VERSION "dbc-export 1 2025.20.8"

NS_ :

BS_:

BU_: ADSP APB APP APS APSB BB BMS CC CMP CMPD CP DAS DI DIF DIR DPB EPAS3P EPAS3S EPASTP EPASTS EPBL EPBR ESP EVSE FC GTW HCML HCMR HVP IBST ICR IDB LS OCS1P PARK PCS PM PMF PMR PNCD PTC RADC RCM RCM2 RCM3 RCU SCCM SCM SCS SDCR TAS TCU TPMS TRCM UI UIS UMC USM VC VCFRONT VCLEFT VCRIGHT VCSEC VEH

BO_ 852 TAS_alertMatrix: 8 TAS
 SG_ TAS_matrixIndex M : 0|4@1+ (1,0) [0|15] "" Vector__XXX
 SG_ TAS_a001_WatchdogReset m0 : 4|1@1+ (1,0) [0|1] "" Vector__XXX
 SG_ TAS_a002_PowerLossReset m0 : 5|1@1+ (1,0) [0|1] "" Vector__XXX
 SG_ TAS_a003_SWAssertion m0 : 6|1@1+ (1,0) [0|1] "" Vector__XXX
 SG_ TAS_a012_CPUReset m0 : 15|1@1+ (1,0) [0|1] "" Vector__XXX
 SG_ TAS_a015_NVMMError m0 : 18|1@1+ (1,0) [0|1] "" Vector__XXX
 SG_ TAS_a016_NVMMRecordError m0 : 19|1@1+ (1,0) [0|1] "" Vector__XXX
 SG_ TAS_a021_TaskSchedulerError m0 : 24|1@1+ (1,0) [0|1] "" Vector__XXX
 SG_ TAS_a022_TaskInitError m0 : 25|1@1+ (1,0) [0|1] "" Vector__XXX
 SG_ TAS_a023_rtosResetRequested m0 : 26|1@1+ (1,0) [0|1] "" Vector__XXX
 SG_ TAS_a024_prefetchAbort m0 : 27|1@1+ (1,0) [0|1] "" Vector__XXX
 SG_ TAS_a025_CrashEvent m0 : 28|1@1+ (1,0) [0|1] "" Vector__XXX
 SG_ TAS_a030_PWMerrorFL m0 : 33|1@1+ (1,0) [0|1] "" Vector__XXX
 SG_ TAS_a031_PWMerrorFR m0 : 34|1@1+ (1,0) [0|1] "" Vector__XXX
 SG_ TAS_a032_PWMerrorRL m0 : 35|1@1+ (1,0) [0|1] "" Vector__XXX
 SG_ TAS_a033_PWMerrorRR m0 : 36|1@1+ (1,0) [0|1] "" Vector__XXX
 SG_ TAS_a034_PWMshortFL m0 : 37|1@1+ (1,0) [0|1] "" Vector__XXX
 SG_ TAS_a035_PWMshortFR m0 : 38|1@1+ (1,0) [0|1] "" Vector__XXX
 SG_ TAS_a036_PWMshortRL m0 : 39|1@1+ (1,0) [0|1] "" Vector__XXX
 SG_ TAS_a037_PWMshortRR m0 : 40|1@1+ (1,0) [0|1] "" Vector__XXX
 SG_ TAS_a038_PWMopenFL m0 : 41|1@1+ (1,0) [0|1] "" Vector__XXX
 SG_ TAS_a039_PWMopenFR m0 : 42|1@1+ (1,0) [0|1] "" Vector__XXX
 SG_ TAS_a040_PWMopenRL m0 : 43|1@1+ (1,0) [0|1] "" Vector__XXX
 SG_ TAS_a041_PWMopenRR m0 : 44|1@1+ (1,0) [0|1] "" Vector__XXX
 SG_ TAS_a043_Task1msError m0 : 46|1@1+ (1,0) [0|1] "" Vector__XXX
 SG_ TAS_a044_Task10msError m0 : 47|1@1+ (1,0) [0|1] "" Vector__XXX
 SG_ TAS_a045_Task100msError m0 : 48|1@1+ (1,0) [0|1] "" Vector__XXX
 SG_ TAS_a046_Task1000msError m0 : 49|1@1+ (1,0) [0|1] "" Vector__XXX
 SG_ TAS_a061_XCPConnected m1 : 4|1@1+ (1,0) [0|1] "" Vector__XXX
 SG_ TAS_a062_XCPWasConnected m1 : 5|1@1+ (1,0) [0|1] "" Vector__XXX
 SG_ TAS_a063_abortFault m1 : 6|1@1+ (1,0) [0|1] "" Vector__XXX
 SG_ TAS_a064_abortFaultExt m1 : 7|1@1+ (1,0) [0|1] "" Vector__XXX
 SG_ TAS_a065_ahbWriteFault m1 : 8|1@1+ (1,0) [0|1] "" Vector__XXX
 SG_ TAS_a066_undefinedInstructionAbo m1 : 9|1@1+ (1,0) [0|1] "" Vector__XXX
 SG_ TAS_a067_reservedHandlerAbort m1 : 10|1@1+ (1,0) [0|1] "" Vector__XXX
 SG_ TAS_a070_underVoltage12V m1 : 13|1@1+ (1,0) [0|1] "" Vector__XXX
 SG_ TAS_a071_overVoltage12V m1 : 14|1@1+ (1,0) [0|1] "" Vector__XXX
 SG_ TAS_a072_shortCircuit5VOnBoard m1 : 15|1@1+ (1,0) [0|1] "" Vector__XXX
 SG_ TAS_a073_underVoltage5VOnBoard m1 : 16|1@1+ (1,0) [0|1] "" Vector__XXX
 SG_ TAS_a074_shortCircuit5VOffBoard m1 : 17|1@1+ (1,0) [0|1] "" Vector__XXX
 SG_ TAS_a075_underVoltage5VOffBoard m1 : 18|1@1+ (1,0) [0|1] "" Vector__XXX
 SG_ TAS_a076_overVoltage5VOffBoard m1 : 19|1@1+ (1,0) [0|1] "" Vector__XXX
 SG_ TAS_a077_pressureSigVTooLow m1 : 20|1@1+ (1,0) [0|1] "" Vector__XXX
 SG_ TAS_a078_pressureSigVTooHigh m1 : 21|1@1+ (1,0) [0|1] "" Vector__XXX
 SG_ TAS_a080_shortCircuit5VHeight m1 : 23|1@1+ (1,0) [0|1] "" Vector__XXX
 SG_ TAS_a081_underVoltage5VHeight m1 : 24|1@1+ (1,0) [0|1] "" Vector__XXX
 SG_ TAS_a082_overVoltage5VHeight m1 : 25|1@1+ (1,0) [0|1] "" Vector__XXX
 SG_ TAS_a083_shortCircuit5VAnalog m1 : 26|1@1+ (1,0) [0|1] "" Vector__XXX
 SG_ TAS_a084_underVoltage5VAnalog m1 : 27|1@1+ (1,0) [0|1] "" Vector__XXX
 SG_ TAS_a085_overVoltage5VAnalog m1 : 28|1@1+ (1,0) [0|1] "" Vector__XXX
 SG_ TAS_a086_underVoltage12VSwtchd m1 : 29|1@1+ (1,0) [0|1] "" Vector__XXX
 SG_ TAS_a087_overVoltage12VSwtchd m1 : 30|1@1+ (1,0) [0|1] "" Vector__XXX
 SG_ TAS_a093_OTPError m1 : 36|1@1+ (1,0) [0|1] "" Vector__XXX
 SG_ TAS_a098_VCFRONT_MIA m1 : 41|1@1+ (1,0) [0|1] "" Vector__XXX
 SG_ TAS_a099_UI_MIA m1 : 42|1@1+ (1,0) [0|1] "" Vector__XXX
 SG_ TAS_a100_RCM_MIA m1 : 43|1@1+ (1,0) [0|1] "" Vector__XXX
 SG_ TAS_a101_ESP_MIA m1 : 44|1@1+ (1,0) [0|1] "" Vector__XXX
 SG_ TAS_a102_DI_MIA m1 : 45|1@1+ (1,0) [0|1] "" Vector__XXX
 SG_ TAS_a103_GTW_MIA m1 : 46|1@1+ (1,0) [0|1] "" Vector__XXX
 SG_ TAS_a105_ECUDebugMode m1 : 48|1@1+ (1,0) [0|1] "" Vector__XXX
 SG_ TAS_a106_HighCPULoad m1 : 49|1@1+ (1,0) [0|1] "" Vector__XXX
 SG_ TAS_a107_HighStackUsage m1 : 50|1@1+ (1,0) [0|1] "" Vector__XXX
 SG_ TAS_a150_accelAvgImplausible_FL_ m2 : 33|1@1+ (1,0) [0|1] "" Vector__XXX
 SG_ TAS_a151_accelAvgImplausible_FL_ m2 : 34|1@1+ (1,0) [0|1] "" Vector__XXX
 SG_ TAS_a152_accelAvgImplausible_FL_ m2 : 35|1@1+ (1,0) [0|1] "" Vector__XXX
 SG_ TAS_a153_accelAvgImplausible_FR_ m2 : 36|1@1+ (1,0) [0|1] "" Vector__XXX
 SG_ TAS_a154_accelAvgImplausible_FR_ m2 : 37|1@1+ (1,0) [0|1] "" Vector__XXX
 SG_ TAS_a155_accelAvgImplausible_FR_ m2 : 38|1@1+ (1,0) [0|1] "" Vector__XXX
 SG_ TAS_a156_accelAvgImplausible_RL_ m2 : 39|1@1+ (1,0) [0|1] "" Vector__XXX
 SG_ TAS_a157_accelAvgImplausible_RL_ m2 : 40|1@1+ (1,0) [0|1] "" Vector__XXX
 SG_ TAS_a158_accelAvgImplausible_RL_ m2 : 41|1@1+ (1,0) [0|1] "" Vector__XXX
 SG_ TAS_a159_accelAvgImplausible_RR_ m2 : 42|1@1+ (1,0) [0|1] "" Vector__XXX
 SG_ TAS_a160_accelAvgImplausible_RR_ m2 : 43|1@1+ (1,0) [0|1] "" Vector__XXX
 SG_ TAS_a161_accelAvgImplausible_RR_ m2 : 44|1@1+ (1,0) [0|1] "" Vector__XXX
 SG_ TAS_a164_damperSolenoidMismatch m2 : 47|1@1+ (1,0) [0|1] "" Vector__XXX
 SG_ TAS_a165_damperValveCompFL m2 : 48|1@1+ (1,0) [0|1] "" Vector__XXX
 SG_ TAS_a166_damperValveRbndFL m2 : 49|1@1+ (1,0) [0|1] "" Vector__XXX
 SG_ TAS_a167_damperValveCompFR m2 : 50|1@1+ (1,0) [0|1] "" Vector__XXX
 SG_ TAS_a168_damperValveRbndFR m2 : 51|1@1+ (1,0) [0|1] "" Vector__XXX
 SG_ TAS_a169_damperValveCompRL m2 : 52|1@1+ (1,0) [0|1] "" Vector__XXX
 SG_ TAS_a170_damperValveRbndRL m2 : 53|1@1+ (1,0) [0|1] "" Vector__XXX
 SG_ TAS_a171_damperValveCompRR m2 : 54|1@1+ (1,0) [0|1] "" Vector__XXX
 SG_ TAS_a172_damperValveRbndRR m2 : 55|1@1+ (1,0) [0|1] "" Vector__XXX
 SG_ TAS_a173_staticLeakDetectFL m2 : 56|1@1+ (1,0) [0|1] "" Vector__XXX
 SG_ TAS_a174_staticLeakDetectFR m2 : 57|1@1+ (1,0) [0|1] "" Vector__XXX
 SG_ TAS_a175_staticLeakDetectRL m2 : 58|1@1+ (1,0) [0|1] "" Vector__XXX
 SG_ TAS_a176_staticLeakDetectRR m2 : 59|1@1+ (1,0) [0|1] "" Vector__XXX
 SG_ TAS_a190_a2bFrontAxleFault m3 : 13|1@1+ (1,0) [0|1] "" Vector__XXX
 SG_ TAS_a191_a2bRearAxleFault m3 : 14|1@1+ (1,0) [0|1] "" Vector__XXX
 SG_ TAS_a192_rideHeightObserverDiver m3 : 15|1@1+ (1,0) [0|1] "" Vector__XXX
 SG_ TAS_a193_EPAS3P_MIA m3 : 16|1@1+ (1,0) [0|1] "" Vector__XXX
 SG_ TAS_a194_a2bFrontAxleDataError m3 : 17|1@1+ (1,0) [0|1] "" Vector__XXX
 SG_ TAS_a195_a2bRearAxleDataError m3 : 18|1@1+ (1,0) [0|1] "" Vector__XXX
 SG_ TAS_a196_adaptiveDampingUsingDSP m3 : 19|1@1+ (1,0) [0|1] "" Vector__XXX
 SG_ TAS_a197_invalidAdaptiveModeRequ m3 : 20|1@1+ (1,0) [0|1] "" Vector__XXX
 SG_ TAS_a200_jackModeActive m3 : 23|1@1+ (1,0) [0|1] "" Vector__XXX
 SG_ TAS_a201_low12VBattery m3 : 24|1@1+ (1,0) [0|1] "" Vector__XXX
 SG_ TAS_a210_outOfRangeCalibration m3 : 33|1@1+ (1,0) [0|1] "" Vector__XXX
 SG_ TAS_a211_noRideHeightCalib m3 : 34|1@1+ (1,0) [0|1] "" Vector__XXX
 SG_ TAS_a213_yellowWarningLamp m3 : 36|1@1+ (1,0) [0|1] "" Vector__XXX
 SG_ TAS_a214_redWarningLamp m3 : 37|1@1+ (1,0) [0|1] "" Vector__XXX
 SG_ TAS_a215_limpHomeMode10 m3 : 38|1@1+ (1,0) [0|1] "" Vector__XXX
 SG_ TAS_a216_limpHomeMode20 m3 : 39|1@1+ (1,0) [0|1] "" Vector__XXX
 SG_ TAS_a217_limpHomeMode30 m3 : 40|1@1+ (1,0) [0|1] "" Vector__XXX
 SG_ TAS_a218_limpHomeMode40 m3 : 41|1@1+ (1,0) [0|1] "" Vector__XXX
 SG_ TAS_a220_exhaustGalleryFault m3 : 43|1@1+ (1,0) [0|1] "" Vector__XXX
 SG_ TAS_a221_valveLeakDetected m3 : 44|1@1+ (1,0) [0|1] "" Vector__XXX
 SG_ TAS_a222_compressorPrefillFault m3 : 45|1@1+ (1,0) [0|1] "" Vector__XXX
 SG_ TAS_a223_blockedAirline m3 : 46|1@1+ (1,0) [0|1] "" Vector__XXX
 SG_ TAS_a224_openAirline m3 : 47|1@1+ (1,0) [0|1] "" Vector__XXX
 SG_ TAS_a225_galleryPressureTooHigh m3 : 48|1@1+ (1,0) [0|1] "" Vector__XXX
 SG_ TAS_a226_PWMfastDetectFL m3 : 49|1@1+ (1,0) [0|1] "" Vector__XXX
 SG_ TAS_a227_PWMfastDetectFR m3 : 50|1@1+ (1,0) [0|1] "" Vector__XXX
 SG_ TAS_a228_PWMfastDetectRL m3 : 51|1@1+ (1,0) [0|1] "" Vector__XXX
 SG_ TAS_a229_PWMfastDetectRR m3 : 52|1@1+ (1,0) [0|1] "" Vector__XXX
 SG_ TAS_a230_notifyGeofence m3 : 53|1@1+ (1,0) [0|1] "" Vector__XXX
 SG_ TAS_a231_notifyRoughRoadRaise m3 : 54|1@1+ (1,0) [0|1] "" Vector__XXX
 SG_ TAS_a232_suspensionTypeMismatch m3 : 55|1@1+ (1,0) [0|1] "" Vector__XXX
 SG_ TAS_a233_compressorStuckOn m3 : 56|1@1+ (1,0) [0|1] "" Vector__XXX
 SG_ TAS_a234_damperHydraulicMismatch m3 : 57|1@1+ (1,0) [0|1] "" Vector__XXX
 SG_ TAS_a240_airSpringLeak m3 : 63|1@1+ (1,0) [0|1] "" Vector__XXX
 SG_ TAS_a284_serviceRunModeActive m4 : 47|1@1+ (1,0) [0|1] "" Vector__XXX
 SG_ TAS_a285_twistSustainedUserVis m4 : 48|1@1+ (1,0) [0|1] "" Vector__XXX
 SG_ TAS_a286_driveCycleStats1 m4 : 49|1@1+ (1,0) [0|1] "" Vector__XXX
 SG_ TAS_a287_driveCycleStats2 m4 : 50|1@1+ (1,0) [0|1] "" Vector__XXX
 SG_ TAS_a288_driveCycleStats3 m4 : 51|1@1+ (1,0) [0|1] "" Vector__XXX
 SG_ TAS_a289_driveCycleStats4 m4 : 52|1@1+ (1,0) [0|1] "" Vector__XXX
 SG_ TAS_a290_twistSustainedAtSpeed m4 : 53|1@1+ (1,0) [0|1] "" Vector__XXX
 SG_ TAS_a291_frontAxleTooHigh m4 : 54|1@1+ (1,0) [0|1] "" Vector__XXX
 SG_ TAS_a292_rearAxleTooHigh m4 : 55|1@1+ (1,0) [0|1] "" Vector__XXX
 SG_ TAS_a293_frontAxleTooLow m4 : 56|1@1+ (1,0) [0|1] "" Vector__XXX
 SG_ TAS_a294_rearAxleTooLow m4 : 57|1@1+ (1,0) [0|1] "" Vector__XXX
 SG_ TAS_a295_targetHeightNotMet m4 : 58|1@1+ (1,0) [0|1] "" Vector__XXX
 SG_ TAS_a296_chassisTypeMismatch m4 : 59|1@1+ (1,0) [0|1] "" Vector__XXX
 SG_ TAS_a297_vinMismatch m4 : 60|1@1+ (1,0) [0|1] "" Vector__XXX
 SG_ TAS_a298_vinNotLearned m4 : 61|1@1+ (1,0) [0|1] "" Vector__XXX
 SG_ TAS_a299_offsetEstimateTooLarge m4 : 62|1@1+ (1,0) [0|1] "" Vector__XXX
 SG_ TAS_a300_offsetEstimateData1 m4 : 63|1@1+ (1,0) [0|1] "" Vector__XXX
 SG_ TAS_a301_offsetEstimateData2 m5 : 4|1@1+ (1,0) [0|1] "" Vector__XXX
 SG_ TAS_a303_massEstimateFrozen m5 : 6|1@1+ (1,0) [0|1] "" Vector__XXX
 SG_ TAS_a304_massEstimateFrozenData m5 : 7|1@1+ (1,0) [0|1] "" Vector__XXX
 SG_ TAS_a305_newEndstopPosition m5 : 8|1@1+ (1,0) [0|1] "" Vector__XXX
 SG_ TAS_a306_hardwareProtectFrozen m5 : 9|1@1+ (1,0) [0|1] "" Vector__XXX
 SG_ TAS_a307_endstopBoundaryComp m5 : 10|1@1+ (1,0) [0|1] "" Vector__XXX
 SG_ TAS_a308_endstopBoundaryRbnd m5 : 11|1@1+ (1,0) [0|1] "" Vector__XXX
 SG_ TAS_a309_controlFrozen m5 : 12|1@1+ (1,0) [0|1] "" Vector__XXX
 SG_ TAS_a310_controlFrozenData m5 : 13|1@1+ (1,0) [0|1] "" Vector__XXX
 SG_ TAS_a311_accelsMIA m5 : 14|1@1+ (1,0) [0|1] "" Vector__XXX
 SG_ TAS_a312_rotationalRatesMIA m5 : 15|1@1+ (1,0) [0|1] "" Vector__XXX
 SG_ TAS_a313_dampingCntrlDisabled m5 : 16|1@1+ (1,0) [0|1] "" Vector__XXX
 SG_ TAS_a314_dampingReduced m5 : 17|1@1+ (1,0) [0|1] "" Vector__XXX
 SG_ TAS_a315_pcbaHighTemp m5 : 18|1@1+ (1,0) [0|1] "" Vector__XXX
 SG_ TAS_a316_offsetsAccels m5 : 19|1@1+ (1,0) [0|1] "" Vector__XXX
 SG_ TAS_a317_offsetsRotationalRates m5 : 20|1@1+ (1,0) [0|1] "" Vector__XXX
 SG_ TAS_a318_dampingCntrlInputMIA m5 : 21|1@1+ (1,0) [0|1] "" Vector__XXX
 SG_ TAS_a319_drivetrainTypeMismatch m5 : 22|1@1+ (1,0) [0|1] "" Vector__XXX
 SG_ TAS_a320_offsetsRotationalRates m5 : 23|1@1+ (1,0) [0|1] "" Vector__XXX
 SG_ TAS_a321_speedBumpAttributes1 m5 : 24|1@1+ (1,0) [0|1] "" Vector__XXX
 SG_ TAS_a322_speedBumpAttributes2 m5 : 25|1@1+ (1,0) [0|1] "" Vector__XXX
 SG_ TAS_a332_levelingThresholds1 m5 : 35|1@1+ (1,0) [0|1] "" Vector__XXX
 SG_ TAS_a333_levelingThresholds2 m5 : 36|1@1+ (1,0) [0|1] "" Vector__XXX

BO_ 523 TAS_axleData: 8 TAS
 SG_ TAS_axleIndex M : 0|1@1+ (1,0) [0|1] "" Vector__XXX
 SG_ TAS_rawHeightFL m0 : 4|10@1+ (1,-512) [-512|510] "mm" Vector__XXX
 SG_ TAS_staticHeightEstimateFL m0 : 14|10@1+ (1,-512) [-512|510] "mm" Vector__XXX
 SG_ TAS_componentPressureFL m0 : 24|8@1+ (0.1,0) [0|25.4] "bara" Vector__XXX
 SG_ TAS_rawHeightFR m0 : 32|10@1+ (1,-512) [-512|510] "mm" Vector__XXX
 SG_ TAS_staticHeightEstimateFR m0 : 42|10@1+ (1,-512) [-512|510] "mm" Vector__XXX
 SG_ TAS_componentPressureFR m0 : 52|8@1+ (0.1,0) [0|25.4] "bara" Vector__XXX
 SG_ TAS_rawHeightRL m1 : 4|10@1+ (1,-512) [-512|510] "mm" Vector__XXX
 SG_ TAS_staticHeightEstimateRL m1 : 14|10@1+ (1,-512) [-512|510] "mm" Vector__XXX
 SG_ TAS_componentPressureRL m1 : 24|8@1+ (0.1,0) [0|25.4] "bara" Vector__XXX
 SG_ TAS_rawHeightRR m1 : 32|10@1+ (1,-512) [-512|510] "mm" Vector__XXX
 SG_ TAS_staticHeightEstimateRR m1 : 42|10@1+ (1,-512) [-512|510] "mm" Vector__XXX
 SG_ TAS_componentPressureRR m1 : 52|8@1+ (0.1,0) [0|25.4] "bara" Vector__XXX

BO_ 1398 TAS_dampingStates: 8 TAS
 SG_ TAS_endstopState : 0|1@1+ (1,0) [0|1] "" Vector__XXX
 SG_ TAS_continuousControlState : 1|1@1+ (1,0) [0|1] "" Vector__XXX
 SG_ TAS_activeTireTune : 2|1@1+ (1,0) [0|1] "" Vector__XXX
 SG_ TAS_roughnessRaiseReason : 3|2@1+ (1,0) [0|3] "" Vector__XXX
 SG_ TAS_frontMetricDrivesRear : 5|2@1+ (1,0) [0|3] "" Vector__XXX
 SG_ TAS_roadCondition : 8|8@1+ (0.005,0) [0|1.27] "-" Vector__XXX
 SG_ TAS_bellyProtect : 16|2@1+ (1,0) [0|3] "" Vector__XXX
 SG_ TAS_frontMetricDrivesFront : 18|2@1+ (1,0) [0|3] "" Vector__XXX
 SG_ TAS_speedBumpAxleFront : 20|3@1+ (1,0) [0|7] "" Vector__XXX
 SG_ TAS_speedBumpAxleRear : 23|3@1+ (1,0) [0|7] "" Vector__XXX
 SG_ TAS_holeProtectFL : 26|2@1+ (1,0) [0|3] "" Vector__XXX
 SG_ TAS_holeProtectFR : 28|2@1+ (1,0) [0|3] "" Vector__XXX
 SG_ TAS_holeProtectRL : 30|2@1+ (1,0) [0|3] "" Vector__XXX
 SG_ TAS_holeProtectRR : 32|2@1+ (1,0) [0|3] "" Vector__XXX
 SG_ TAS_stepProtectFL : 34|2@1+ (1,0) [0|3] "" Vector__XXX
 SG_ TAS_stepProtectFR : 36|2@1+ (1,0) [0|3] "" Vector__XXX
 SG_ TAS_stepProtectRL : 38|2@1+ (1,0) [0|3] "" Vector__XXX
 SG_ TAS_stepProtectRR : 40|2@1+ (1,0) [0|3] "" Vector__XXX
 SG_ TAS_FDUTorqueCorruptionScale : 42|4@1+ (0.075,0) [0|1.05] "-" Vector__XXX
 SG_ TAS_sprungMassEstimate : 46|5@1+ (64,1800) [1800|3720] "kg" Vector__XXX
 SG_ TAS_anyDamperActive : 51|1@1+ (1,0) [0|1] "" Vector__XXX
 SG_ TAS_dampingStatesCounter : 52|4@1+ (1,0) [0|15] "" Vector__XXX
 SG_ TAS_dampingStatesChecksum : 56|8@1+ (1,0) [0|255] "" Vector__XXX

BO_ 1357 TAS_info: 8 TAS
 SG_ TAS_infoIndex M : 0|8@1+ (1,0) [0|255] "" Vector__XXX
 SG_ TAS_infoBuildType m10 : 8|8@1+ (1,0) [0|255] "" Vector__XXX
 SG_ TAS_infoBuildConfigId m10 : 16|16@1+ (1,0) [0|65535] "" Vector__XXX
 SG_ TAS_infoHardwareId m10 : 32|1@1+ (1,0) [0|1] "" Vector__XXX
 SG_ TAS_infoComponentId m10 : 48|16@1+ (1,0) [0|65535] "" Vector__XXX
 SG_ TAS_infoPcbaId m11 : 16|8@1+ (1,0) [0|255] "" Vector__XXX
 SG_ TAS_infoAssemblyId m11 : 24|8@1+ (1,0) [0|254] "" Vector__XXX
 SG_ TAS_infoUsageId m11 : 32|16@1+ (1,0) [0|65535] "" Vector__XXX
 SG_ TAS_infoSubUsageId m11 : 48|16@1+ (1,0) [0|65535] "" Vector__XXX
 SG_ TAS_infoAppCrc m13 : 32|32@1+ (1,0) [0|4294967295] "" Vector__XXX
 SG_ TAS_infoAppGitHash m17 : 8|56@1+ (1,0) [0|7.20575940379e+16] "" Vector__XXX
 SG_ TAS_infoBootGitHash m18 : 8|56@1+ (1,0) [0|7.20575940379e+16] "" Vector__XXX
 SG_ TAS_infoPlatformType m19 : 8|8@1+ (1,0) [0|255] "" Vector__XXX
 SG_ TAS_infoMajorVersion m19 : 16|8@1+ (1,0) [0|254] "" Vector__XXX
 SG_ TAS_infoBranchOrigin m19 : 24|8@1+ (1,0) [0|254] "" Vector__XXX
 SG_ TAS_infoMaturity m19 : 32|8@1+ (1,0) [0|254] "" Vector__XXX
 SG_ TAS_infoHardwareRevision m19 : 40|8@1+ (1,0) [0|254] "" Vector__XXX

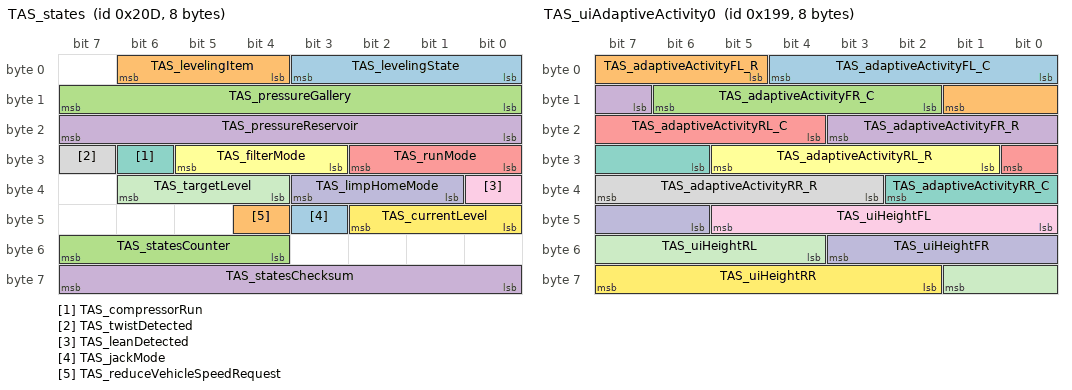
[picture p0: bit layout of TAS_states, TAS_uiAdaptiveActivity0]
BO_ 525 TAS_states: 8 TAS
 SG_ TAS_levelingState : 0|4@1+ (1,0) [0|15] "" Vector__XXX
 SG_ TAS_levelingItem : 4|3@1+ (1,0) [0|7] "" Vector__XXX
 SG_ TAS_pressureGallery : 8|8@1+ (0.1,0) [0|25.4] "bara" Vector__XXX
 SG_ TAS_pressureReservoir : 16|8@1+ (0.1,0) [0|25.4] "bara" Vector__XXX
 SG_ TAS_runMode : 24|3@1+ (1,0) [0|7] "" Vector__XXX
 SG_ TAS_filterMode : 27|3@1+ (1,0) [0|7] "" Vector__XXX
 SG_ TAS_compressorRun : 30|1@1+ (1,0) [0|1] "" Vector__XXX
 SG_ TAS_twistDetected : 31|1@1+ (1,0) [0|1] "" Vector__XXX
 SG_ TAS_leanDetected : 32|1@1+ (1,0) [0|1] "" Vector__XXX
 SG_ TAS_limpHomeMode : 33|3@1+ (1,0) [0|7] "" Vector__XXX
 SG_ TAS_targetLevel : 36|3@1+ (1,0) [0|7] "" Vector__XXX
 SG_ TAS_currentLevel : 40|3@1+ (1,0) [0|7] "" Vector__XXX
 SG_ TAS_jackMode : 43|1@1+ (1,0) [0|1] "" Vector__XXX
 SG_ TAS_reduceVehicleSpeedRequest : 44|1@1+ (1,0) [0|1] "" Vector__XXX
 SG_ TAS_statesCounter : 52|4@1+ (1,0) [0|15] "" Vector__XXX
 SG_ TAS_statesChecksum : 56|8@1+ (1,0) [0|255] "" Vector__XXX

BO_ 409 TAS_uiAdaptiveActivity0: 8 TAS
 SG_ TAS_adaptiveActivityFL_C : 0|5@1+ (0.04,0) [0|1] "-" Vector__XXX
 SG_ TAS_adaptiveActivityFL_R : 5|5@1+ (0.04,0) [0|1] "-" Vector__XXX
 SG_ TAS_adaptiveActivityFR_C : 10|5@1+ (0.04,0) [0|1] "-" Vector__XXX
 SG_ TAS_adaptiveActivityFR_R : 15|5@1+ (0.04,0) [0|1] "-" Vector__XXX
 SG_ TAS_adaptiveActivityRL_C : 20|5@1+ (0.04,0) [0|1] "-" Vector__XXX
 SG_ TAS_adaptiveActivityRL_R : 25|5@1+ (0.04,0) [0|1] "-" Vector__XXX
 SG_ TAS_adaptiveActivityRR_C : 30|5@1+ (0.04,0) [0|1] "-" Vector__XXX
 SG_ TAS_adaptiveActivityRR_R : 35|5@1+ (0.04,0) [0|1] "-" Vector__XXX
 SG_ TAS_uiHeightFL : 40|6@1+ (4,-128) [-128|120] "mm" Vector__XXX
 SG_ TAS_uiHeightFR : 46|6@1+ (4,-128) [-128|120] "mm" Vector__XXX
 SG_ TAS_uiHeightRL : 52|6@1+ (4,-128) [-128|120] "mm" Vector__XXX
 SG_ TAS_uiHeightRR : 58|6@1+ (4,-128) [-128|120] "mm" Vector__XXX

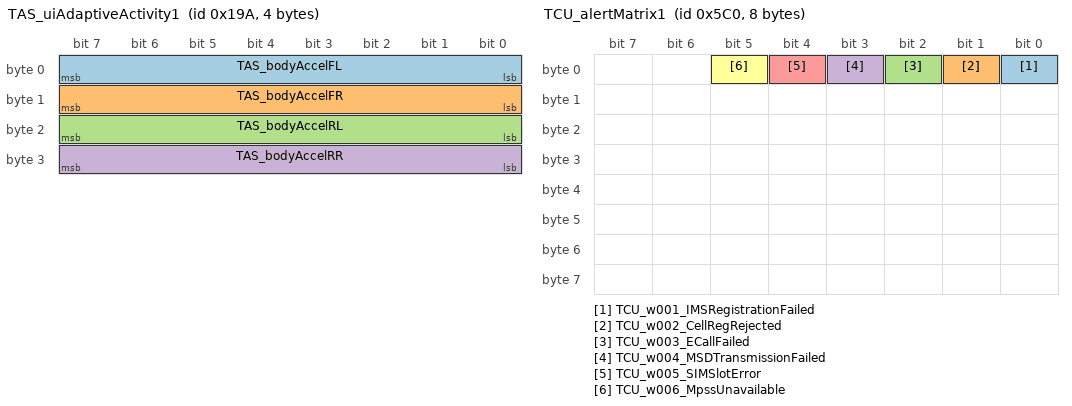
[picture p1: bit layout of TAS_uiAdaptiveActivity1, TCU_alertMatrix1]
BO_ 410 TAS_uiAdaptiveActivity1: 4 TAS
 SG_ TAS_bodyAccelFL : 0|8@1+ (0.05,-5) [-5|5] "g" Vector__XXX
 SG_ TAS_bodyAccelFR : 8|8@1+ (0.05,-5) [-5|5] "g" Vector__XXX
 SG_ TAS_bodyAccelRL : 16|8@1+ (0.05,-5) [-5|5] "g" Vector__XXX
 SG_ TAS_bodyAccelRR : 24|8@1+ (0.05,-5) [-5|5] "g" Vector__XXX

BO_ 538 TAS_uiControl: 5 TAS
 SG_ TAS_yellowWarningLamp : 0|1@1+ (1,0) [0|1] "" Vector__XXX
 SG_ TAS_redWarningLamp : 1|1@1+ (1,0) [0|1] "" Vector__XXX
 SG_ TAS_veryLowAllowed : 2|1@1+ (1,0) [0|1] "" Vector__XXX
 SG_ TAS_lowAllowed : 3|1@1+ (1,0) [0|1] "" Vector__XXX
 SG_ TAS_standardAllowed : 4|1@1+ (1,0) [0|1] "" Vector__XXX
 SG_ TAS_highAllowed : 5|1@1+ (1,0) [0|1] "" Vector__XXX
 SG_ TAS_veryHighAllowed : 6|1@1+ (1,0) [0|1] "" Vector__XXX
 SG_ TAS_extractAllowed : 7|1@1+ (1,0) [0|1] "" Vector__XXX
 SG_ TAS_showSpinner : 9|1@1+ (1,0) [0|1] "" Vector__XXX
 SG_ TAS_adaptiveRideModeOverride : 10|2@1+ (1,0) [0|2] "" Vector__XXX
 SG_ TAS_levelSelectEnabled : 12|1@1+ (1,0) [0|1] "" Vector__XXX
 SG_ TAS_jackModeToggleEnabled : 13|1@1+ (1,0) [0|1] "" Vector__XXX
 SG_ TAS_adaptiveRideSelectEnabled : 14|1@1+ (1,0) [0|1] "" Vector__XXX
 SG_ TAS_launchModeState : 16|3@1+ (1,0) [0|7] "" Vector__XXX
 SG_ TAS_restrictUpLevelingFalcons : 19|1@1+ (1,0) [0|1] "" Vector__XXX
 SG_ TAS_restrictUpLevelingTrunk : 20|1@1+ (1,0) [0|1] "" Vector__XXX
 SG_ TAS_restrictDownLevelingDoors : 21|1@1+ (1,0) [0|1] "" Vector__XXX
 SG_ TAS_restrictLevelingChargeCable : 22|1@1+ (1,0) [0|1] "" Vector__XXX
 SG_ TAS_restrictLevelingSystemCheck : 23|1@1+ (1,0) [0|1] "" Vector__XXX
 SG_ TAS_restrictLevelingTransport : 24|1@1+ (1,0) [0|1] "" Vector__XXX
 SG_ TAS_restrictLevelingShowroom : 25|1@1+ (1,0) [0|1] "" Vector__XXX
 SG_ TAS_uiControlCounter : 28|4@1+ (1,0) [0|15] "" Vector__XXX
 SG_ TAS_uiControlChecksum : 32|8@1+ (1,0) [0|255] "" Vector__XXX

BO_ 1410 TCU_alertLog: 8 TCU
 SG_ TCU_alertID M : 0|3@1+ (1,0) [0|7] "" Vector__XXX
 SG_ TCU_alertState : 15|1@1+ (1,0) [0|1] "" Vector__XXX
 SG_ TCU_w001_FailCode m1 : 16|32@1+ (1,0) [0|4294967295] "" Vector__XXX
 SG_ TCU_w002_RejCause m2 : 16|32@1+ (1,0) [0|4294967295] "" Vector__XXX
 SG_ TCU_w003_CallFailCode m3 : 16|32@1+ (1,0) [0|4294967295] "" Vector__XXX
 SG_ TCU_w004_MSDFailCode m4 : 16|32@1+ (1,0) [0|4294967295] "" Vector__XXX
 SG_ TCU_w006_Count m6 : 16|32@1+ (1,0) [0|4294967295] "" Vector__XXX

BO_ 1472 TCU_alertMatrix1: 8 TCU
 SG_ TCU_w001_IMSRegistrationFailed : 0|1@1+ (1,0) [0|1] "" Vector__XXX
 SG_ TCU_w002_CellRegRejected : 1|1@1+ (1,0) [0|1] "" Vector__XXX
 SG_ TCU_w003_ECallFailed : 2|1@1+ (1,0) [0|1] "" Vector__XXX
 SG_ TCU_w004_MSDTransmissionFailed : 3|1@1+ (1,0) [0|1] "" Vector__XXX
 SG_ TCU_w005_SIMSlotError : 4|1@1+ (1,0) [0|1] "" Vector__XXX
 SG_ TCU_w006_MpssUnavailable : 5|1@1+ (1,0) [0|1] "" Vector__XXX

BO_ 1409 TCU_log: 8 TCU
 SG_ TCU_logMux M : 0|32@1+ (1,0) [0|4294967295] "" Vector__XXX
 SG_ TCU_cpuTemp m0 : 32|32@1+ (1,0) [0|4294967295] "C" Vector__XXX
 SG_ TCU_cpuUsage m1 : 32|32@1+ (1,0) [0|4294967295] "%" Vector__XXX
 SG_ TCU_mdmCoreTemperature m2 : 32|32@1+ (1,0) [0|4294967295] "C" Vector__XXX
 SG_ TCU_availableMemory m3 : 32|32@1+ (1,0) [0|4294967295] "KB" Vector__XXX
 SG_ TCU_pwm m4 : 32|32@1+ (1,0) [0|4294967295] "" Vector__XXX
 SG_ TCU_pwmcap m5 : 32|32@1+ (1,0) [0|4294967295] "" Vector__XXX
 SG_ TCU_totalResumes m6 : 32|32@1+ (1,0) [0|4294967295] "" Vector__XXX
 SG_ TCU_mdmUplinkQueueSize m7 : 32|32@1+ (1,0) [0|4294967295] "bytes" Vector__XXX
 SG_ TCU_mdmRSRP m8 : 32|32@1- (1,0) [-2147483648|2147483647] "dBm" Vector__XXX
 SG_ TCU_mdmSINR m9 : 32|32@1- (1,0) [-2147483648|2147483647] "dBm" Vector__XXX
 SG_ TCU_mdmUplinkAllowedRate m10 : 32|32@1+ (1,0) [0|4294967295] "Kbps" Vector__XXX
 SG_ TCU_mdmUplinkAvgRage m11 : 32|32@1+ (1,0) [0|4294967295] "" Vector__XXX
 SG_ TCU_mdmServiceState m12 : 32|32@1+ (1,0) [0|4294967295] "" Vector__XXX
 SG_ TCU_mdmIMSStatus m13 : 32|32@1+ (1,0) [0|4294967295] "" Vector__XXX
 SG_ TCU_mdmSIMStatus m14 : 32|32@1+ (1,0) [0|4294967295] "" Vector__XXX
 SG_ TCU_mdmBusyActive m15 : 32|32@1+ (1,0) [0|4294967294] "" Vector__XXX

BO_ 1408 TCU_status: 8 TCU
 SG_ TCU_statusMux M : 0|32@1+ (1,0) [0|4294967295] "" Vector__XXX
 SG_ TCU_wakeUpReason m0 : 32|32@1+ (1,0) [0|4294967294] "" Vector__XXX
 SG_ TCU_tcuCmdId m1 : 32|1@1+ (1,0) [0|1] "" Vector__XXX
 SG_ TCU_goingToSleep m2 : 32|32@1+ (1,0) [0|4294967294] "" Vector__XXX

BO_ 879 TPMS_StatusC: 8 TPMS
 SG_ TPMS_c_globalHardWarning : 0|1@1+ (1,0) [0|1] "" Vector__XXX
 SG_ TPMS_c_globalSoftWarning : 1|1@1+ (1,0) [0|1] "" Vector__XXX
 SG_ TPMS_systemMalfunction : 2|1@1+ (1,0) [0|1] "" Vector__XXX
 SG_ TPMS_WA_version : 3|1@1+ (1,0) [0|1] "" Vector__XXX
 SG_ TPMS_globalDeltaPressure : 4|1@1+ (1,0) [0|1] "" Vector__XXX
 SG_ TPMS_newSensorLearnt : 5|3@1+ (1,0) [0|7] "" Vector__XXX
 SG_ TPMS_softWarningRR : 8|1@1+ (1,0) [0|1] "" Vector__XXX
 SG_ TPMS_hardWarningRR : 9|1@1+ (1,0) [0|1] "" Vector__XXX
 SG_ TPMS_softWarningRL : 10|1@1+ (1,0) [0|1] "" Vector__XXX
 SG_ TPMS_hardWarningRL : 11|1@1+ (1,0) [0|1] "" Vector__XXX
 SG_ TPMS_softWarningFR : 12|1@1+ (1,0) [0|1] "" Vector__XXX
 SG_ TPMS_hardWarningFR : 13|1@1+ (1,0) [0|1] "" Vector__XXX
 SG_ TPMS_softWarningFL : 14|1@1+ (1,0) [0|1] "" Vector__XXX
 SG_ TPMS_hardWarningFL : 15|1@1+ (1,0) [0|1] "" Vector__XXX
 SG_ TPMS_learningStatus : 16|2@1+ (1,0) [0|3] "" Vector__XXX
 SG_ TPMS_localisationStatus : 18|2@1+ (1,0) [0|3] "" Vector__XXX
 SG_ TPMS_deltaPressWarningFL : 20|1@1+ (1,0) [0|1] "" Vector__XXX
 SG_ TPMS_deltaPressWarningFR : 21|1@1+ (1,0) [0|1] "" Vector__XXX
 SG_ TPMS_deltaPressWarningRL : 22|1@1+ (1,0) [0|1] "" Vector__XXX
 SG_ TPMS_deltaPressWarningRR : 23|1@1+ (1,0) [0|1] "" Vector__XXX
 SG_ TPMS_sensorNoResponseFL : 24|1@1+ (1,0) [0|1] "" Vector__XXX
 SG_ TPMS_sensorNoResponseFR : 25|1@1+ (1,0) [0|1] "" Vector__XXX
 SG_ TPMS_sensorNoResponseRL : 26|1@1+ (1,0) [0|1] "" Vector__XXX
 SG_ TPMS_sensorNoResponseRR : 27|1@1+ (1,0) [0|1] "" Vector__XXX
 SG_ TPMS_sensorThermShutdownFL : 28|1@1+ (1,0) [0|1] "" Vector__XXX
 SG_ TPMS_sensorThermShutdownFR : 29|1@1+ (1,0) [0|1] "" Vector__XXX
 SG_ TPMS_sensorThermShutdownRL : 30|1@1+ (1,0) [0|1] "" Vector__XXX
 SG_ TPMS_sensorThermShutdownRR : 31|1@1+ (1,0) [0|1] "" Vector__XXX
 SG_ TPMS_sensorBatteryLowFL : 32|1@1+ (1,0) [0|1] "" Vector__XXX
 SG_ TPMS_sensorBatteryLowFR : 33|1@1+ (1,0) [0|1] "" Vector__XXX
 SG_ TPMS_sensorBatteryLowRL : 34|1@1+ (1,0) [0|1] "" Vector__XXX
 SG_ TPMS_sensorBatteryLowRR : 35|1@1+ (1,0) [0|1] "" Vector__XXX
 SG_ TPMS_sensorDefectiveFL : 36|1@1+ (1,0) [0|1] "" Vector__XXX
 SG_ TPMS_sensorDefectiveFR : 37|1@1+ (1,0) [0|1] "" Vector__XXX
 SG_ TPMS_sensorDefectiveRL : 38|1@1+ (1,0) [0|1] "" Vector__XXX
 SG_ TPMS_sensorDefectiveRR : 39|1@1+ (1,0) [0|1] "" Vector__XXX
 SG_ TPMS_ecuUnderVoltage : 40|1@1+ (1,0) [0|1] "" Vector__XXX
 SG_ TPMS_ecuOverVoltage : 41|1@1+ (1,0) [0|1] "" Vector__XXX
 SG_ TPMS_ecuRamRomNvMFail : 42|1@1+ (1,0) [0|1] "" Vector__XXX
 SG_ TPMS_rfReceiverFail : 43|1@1+ (1,0) [0|1] "" Vector__XXX
 SG_ TPMS_wheelPulseMissing : 44|1@1+ (1,0) [0|1] "" Vector__XXX
 SG_ TPMS_vehicleSpeedFail : 45|1@1+ (1,0) [0|1] "" Vector__XXX
 SG_ TPMS_externalTemperatureFail : 46|1@1+ (1,0) [0|1] "" Vector__XXX
 SG_ TPMS_eolNotCompleted : 47|1@1+ (1,0) [0|1] "" Vector__XXX
 SG_ TPMS_rcpFront : 48|8@1+ (0.025,0) [0|6.375] "bar" Vector__XXX
 SG_ TPMS_rcpRear : 56|8@1+ (0.025,0) [0|6.375] "bar" Vector__XXX

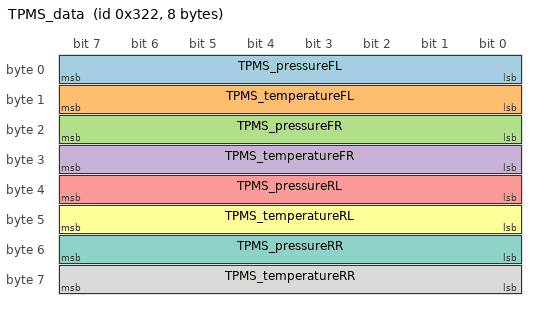
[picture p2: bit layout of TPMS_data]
BO_ 802 TPMS_data: 8 TPMS
 SG_ TPMS_pressureFL : 0|8@1+ (0.025,0) [0|6.35] "bar" Vector__XXX
 SG_ TPMS_temperatureFL : 8|8@1+ (1,-40) [-40|214] "degC" Vector__XXX
 SG_ TPMS_pressureFR : 16|8@1+ (0.025,0) [0|6.35] "bar" Vector__XXX
 SG_ TPMS_temperatureFR : 24|8@1+ (1,-40) [-40|214] "degC" Vector__XXX
 SG_ TPMS_pressureRL : 32|8@1+ (0.025,0) [0|6.35] "bar" Vector__XXX
 SG_ TPMS_temperatureRL : 40|8@1+ (1,-40) [-40|214] "degC" Vector__XXX
 SG_ TPMS_pressureRR : 48|8@1+ (0.025,0) [0|6.35] "bar" Vector__XXX
 SG_ TPMS_temperatureRR : 56|8@1+ (1,-40) [-40|214] "degC" Vector__XXX

BO_ 1519 TPMS_info: 8 TPMS
 SG_ TPMS_infoIndex M : 0|8@1+ (1,0) [0|255] "" Vector__XXX
 SG_ TPMS_infoComponentID m10 : 48|16@1+ (1,0) [0|65535] "" Vector__XXX
 SG_ TPMS_infoPcbaID m11 : 16|8@1+ (1,0) [0|255] "" Vector__XXX
 SG_ TPMS_infoAssemblyID m11 : 24|8@1+ (1,0) [0|255] "" Vector__XXX
 SG_ TPMS_infoUsageID m11 : 32|16@1+ (1,0) [0|65535] "" Vector__XXX
 SG_ TPMS_infoApplicationCRC m13 : 32|32@1+ (1,0) [0|4294967295] "" Vector__XXX
 SG_ TPMS_infoBootUdsProtoVersion m20 : 8|8@1+ (1,0) [0|255] "" Vector__XXX
 SG_ TPMS_infoBootloaderCRC m20 : 32|32@1+ (1,0) [0|4294967295] "" Vector__XXX

BO_ 1298 TRCM_alertLog: 8 TRCM
 SG_ TRCM_alertID M : 0|10@1+ (1,0) [0|1023] "" Vector__XXX
 SG_ TRCM_alertState : 15|1@1+ (1,0) [0|1] "" Vector__XXX
 SG_ TRCM_a015_NVMMMemOverflow m15 : 16|1@1+ (1,0) [0|1] "" Vector__XXX
 SG_ TRCM_a015_NVMMFilesystemError m15 : 17|1@1+ (1,0) [0|1] "" Vector__XXX
 SG_ TRCM_a015_NVMMRecordIDError m15 : 18|1@1+ (1,0) [0|1] "" Vector__XXX
 SG_ TRCM_a057_VEH_cpControl m57 : 16|1@1+ (1,0) [0|1] "" Vector__XXX
 SG_ TRCM_a059_voltageDrop m59 : 16|12@1+ (0.005443676,0) [0|22.29185322] "V" Vector__XXX
 SG_ TRCM_a059_resistanceEstimate m59 : 28|12@1+ (0.00244,0) [0|9.9918] "Ohms" Vector__XXX
 SG_ TRCM_a059_current m59 : 40|12@1+ (0.05,0) [0|204.75] "A" Vector__XXX
 SG_ TRCM_a063_switchChannel m63 : 16|8@1+ (1,0) [0|255] "" Vector__XXX
 SG_ TRCM_a063_switchType m63 : 24|8@1+ (1,0) [0|255] "" Vector__XXX
 SG_ TRCM_a063_ADCVoltage m63 : 32|8@1+ (0.025,0) [0|6.375] "V" Vector__XXX
 SG_ TRCM_a063_disconnected m63 : 40|1@1+ (1,0) [0|1] "" Vector__XXX
 SG_ TRCM_a063_indeterminate m63 : 41|1@1+ (1,0) [0|1] "" Vector__XXX
 SG_ TRCM_a063_stuckActive m63 : 42|1@1+ (1,0) [0|1] "" Vector__XXX
 SG_ TRCM_a063_faulted m63 : 43|1@1+ (1,0) [0|1] "" Vector__XXX
 SG_ TRCM_a082_RIPC_epbPrivateState m82 : 16|1@1+ (1,0) [0|1] "" Vector__XXX
 SG_ TRCM_a082_RIPC_remoteHSD m82 : 17|1@1+ (1,0) [0|1] "" Vector__XXX
 SG_ TRCM_a082_RIPC_railStatus m82 : 18|1@1+ (1,0) [0|1] "" Vector__XXX
 SG_ TRCM_a082_RIPC_remoteMux m82 : 19|1@1+ (1,0) [0|1] "" Vector__XXX
 SG_ TRCM_a083_LIPC_epbPrivateState m83 : 16|1@1+ (1,0) [0|1] "" Vector__XXX
 SG_ TRCM_a083_LIPC_remoteHSD m83 : 17|1@1+ (1,0) [0|1] "" Vector__XXX
 SG_ TRCM_a083_LIPC_railStatus m83 : 18|1@1+ (1,0) [0|1] "" Vector__XXX
 SG_ TRCM_a083_LIPC_HSDFaults m83 : 19|1@1+ (1,0) [0|1] "" Vector__XXX
 SG_ TRCM_a084_CH_StatusC m84 : 16|1@1+ (1,0) [0|1] "" Vector__XXX
 SG_ TRCM_a085_PARTY_buttonStatus m85 : 16|1@1+ (1,0) [0|1] "" Vector__XXX
 SG_ TRCM_a086_VEH_LVBMS_statusHigh m86 : 16|1@1+ (1,0) [0|1] "" Vector__XXX
 SG_ TRCM_a086_VEH_LVBMS_statusLow m86 : 17|1@1+ (1,0) [0|1] "" Vector__XXX
 SG_ TRCM_a086_VEH_status m86 : 18|1@1+ (1,0) [0|1] "" Vector__XXX
 SG_ TRCM_a086_VEH_12VBatteryStatus m86 : 19|1@1+ (1,0) [0|1] "" Vector__XXX
 SG_ TRCM_a086_VEH_LVPowerState m86 : 20|1@1+ (1,0) [0|1] "" Vector__XXX
 SG_ TRCM_a086_VEH_lightStatus m86 : 21|1@1+ (1,0) [0|1] "" Vector__XXX
 SG_ TRCM_a086_VEH_systemStatus m86 : 22|1@1+ (1,0) [0|1] "" Vector__XXX
 SG_ TRCM_a086_VEH_thermalStatus m86 : 23|1@1+ (1,0) [0|1] "" Vector__XXX
 SG_ TRCM_a086_VEH_vehNm m86 : 24|1@1+ (1,0) [0|1] "" Vector__XXX
 SG_ TRCM_a087_VEH_temperature m87 : 16|1@1+ (1,0) [0|1] "" Vector__XXX
 SG_ TRCM_a087_VEH_thermalControl m87 : 17|1@1+ (1,0) [0|1] "" Vector__XXX
 SG_ TRCM_a087_VEH_torque m87 : 18|1@1+ (1,0) [0|1] "" Vector__XXX
 SG_ TRCM_a087_VEH_status m87 : 19|1@1+ (1,0) [0|1] "" Vector__XXX
 SG_ TRCM_a087_PARTY_torque m87 : 20|1@1+ (1,0) [0|1] "" Vector__XXX
 SG_ TRCM_a087_PARTY_status m87 : 21|1@1+ (1,0) [0|1] "" Vector__XXX
 SG_ TRCM_a087_PARTY_temperature m87 : 22|1@1+ (1,0) [0|1] "" Vector__XXX
 SG_ TRCM_a087_PARTY_thermalControl m87 : 23|1@1+ (1,0) [0|1] "" Vector__XXX
 SG_ TRCM_a088_VEH_temperature m88 : 16|1@1+ (1,0) [0|1] "" Vector__XXX
 SG_ TRCM_a088_VEH_thermalControl m88 : 17|1@1+ (1,0) [0|1] "" Vector__XXX
 SG_ TRCM_a088_VEH_torque m88 : 18|1@1+ (1,0) [0|1] "" Vector__XXX
 SG_ TRCM_a088_VEH_status m88 : 19|1@1+ (1,0) [0|1] "" Vector__XXX
 SG_ TRCM_a088_PARTY_torque m88 : 20|1@1+ (1,0) [0|1] "" Vector__XXX
 SG_ TRCM_a088_PARTY_status m88 : 21|1@1+ (1,0) [0|1] "" Vector__XXX
 SG_ TRCM_a088_PARTY_temperature m88 : 22|1@1+ (1,0) [0|1] "" Vector__XXX
 SG_ TRCM_a088_PARTY_thermalControl m88 : 23|1@1+ (1,0) [0|1] "" Vector__XXX
 SG_ TRCM_a089_PARTY_party1 m89 : 16|1@1+ (1,0) [0|1] "" Vector__XXX
 SG_ TRCM_a089_PARTY_status m89 : 17|1@1+ (1,0) [0|1] "" Vector__XXX
 SG_ TRCM_a089_VEH_status m89 : 18|1@1+ (1,0) [0|1] "" Vector__XXX
 SG_ TRCM_a089_BDY_party1 m89 : 19|1@1+ (1,0) [0|1] "" Vector__XXX
 SG_ TRCM_a089_BDY_status m89 : 20|1@1+ (1,0) [0|1] "" Vector__XXX
 SG_ TRCM_a089_CH_status m89 : 21|1@1+ (1,0) [0|1] "" Vector__XXX
 SG_ TRCM_a089_CH_party1 m89 : 22|1@1+ (1,0) [0|1] "" Vector__XXX
 SG_ TRCM_a089_CH_party3 m89 : 23|1@1+ (1,0) [0|1] "" Vector__XXX
 SG_ TRCM_a089_VEH_party1 m89 : 24|1@1+ (1,0) [0|1] "" Vector__XXX
 SG_ TRCM_a089_VEH_party3 m89 : 25|1@1+ (1,0) [0|1] "" Vector__XXX
 SG_ TRCM_a091_VEH_faultsAndExtras m91 : 16|1@1+ (1,0) [0|1] "" Vector__XXX
 SG_ TRCM_a091_VEH_info m91 : 17|1@1+ (1,0) [0|1] "" Vector__XXX
 SG_ TRCM_a091_VEH_state m91 : 18|1@1+ (1,0) [0|1] "" Vector__XXX
 SG_ TRCM_a092_VEH_restraintStatus m92 : 16|1@1+ (1,0) [0|1] "" Vector__XXX
 SG_ TRCM_a092_VEH_switchStatus m92 : 17|1@1+ (1,0) [0|1] "" Vector__XXX
 SG_ TRCM_a092_VEH_seatStatus2 m92 : 18|1@1+ (1,0) [0|1] "" Vector__XXX
 SG_ TRCM_a092_VEH_vehNm m92 : 19|1@1+ (1,0) [0|1] "" Vector__XXX
 SG_ TRCM_a093_VEH_restraintStatus m93 : 16|1@1+ (1,0) [0|1] "" Vector__XXX
 SG_ TRCM_a093_VEH_switchStatus m93 : 17|1@1+ (1,0) [0|1] "" Vector__XXX
 SG_ TRCM_a093_VEH_seatStatus2 m93 : 18|1@1+ (1,0) [0|1] "" Vector__XXX
 SG_ TRCM_a093_VEH_vehNm m93 : 19|1@1+ (1,0) [0|1] "" Vector__XXX
 SG_ TRCM_a094_VEH_sysStatus m94 : 16|1@1+ (1,0) [0|1] "" Vector__XXX
 SG_ TRCM_a094_PARTY_sysStatus m94 : 17|1@1+ (1,0) [0|1] "" Vector__XXX
 SG_ TRCM_a095_PT_ptNm m95 : 16|1@1+ (1,0) [0|1] "" Vector__XXX
 SG_ TRCM_a095_PT_status m95 : 17|1@1+ (1,0) [0|1] "" Vector__XXX
 SG_ TRCM_a096_VEH_status m96 : 16|1@1+ (1,0) [0|1] "" Vector__XXX
 SG_ TRCM_a096_CH_status m96 : 17|1@1+ (1,0) [0|1] "" Vector__XXX
 SG_ TRCM_a098_CH_torque m98 : 16|1@1+ (1,0) [0|1] "" Vector__XXX
 SG_ TRCM_a098_VEH_hvStatus m98 : 17|1@1+ (1,0) [0|1] "" Vector__XXX
 SG_ TRCM_a098_VEH_status m98 : 18|1@1+ (1,0) [0|1] "" Vector__XXX
 SG_ TRCM_a098_VEH_thermalControl m98 : 19|1@1+ (1,0) [0|1] "" Vector__XXX
 SG_ TRCM_a098_VEH_temperature m98 : 20|1@1+ (1,0) [0|1] "" Vector__XXX
 SG_ TRCM_a098_VEH_torque m98 : 21|1@1+ (1,0) [0|1] "" Vector__XXX
 SG_ TRCM_a098_PARTY_status m98 : 22|1@1+ (1,0) [0|1] "" Vector__XXX
 SG_ TRCM_a098_PARTY_temperature m98 : 23|1@1+ (1,0) [0|1] "" Vector__XXX
 SG_ TRCM_a098_PARTY_thermalControl m98 : 24|1@1+ (1,0) [0|1] "" Vector__XXX
 SG_ TRCM_a098_PARTY_torque m98 : 25|1@1+ (1,0) [0|1] "" Vector__XXX
 SG_ TRCM_a098_PT_thermalControl m98 : 26|1@1+ (1,0) [0|1] "" Vector__XXX
 SG_ TRCM_a098_PT_temperature m98 : 27|1@1+ (1,0) [0|1] "" Vector__XXX
 SG_ TRCM_a099_VEH_oocStatus m99 : 16|1@1+ (1,0) [0|1] "" Vector__XXX
 SG_ TRCM_a100_VEH m100 : 16|1@1+ (1,0) [0|1] "" Vector__XXX
 SG_ TRCM_a100_PARTY m100 : 17|1@1+ (1,0) [0|1] "" Vector__XXX
 SG_ TRCM_a100_PT m100 : 18|1@1+ (1,0) [0|1] "" Vector__XXX
 SG_ TRCM_a100_CH m100 : 19|1@1+ (1,0) [0|1] "" Vector__XXX
 SG_ TRCM_a100_OBD m100 : 20|1@1+ (1,0) [0|1] "" Vector__XXX
 SG_ TRCM_a101_VEH_state m101 : 16|1@1+ (1,0) [0|1] "" Vector__XXX
 SG_ TRCM_a101_PARTY_locState m101 : 17|1@1+ (1,0) [0|1] "" Vector__XXX
 SG_ TRCM_a101_LIPC_externalWatchdogH m101 : 18|1@1+ (1,0) [0|1] "" Vector__XXX
 SG_ TRCM_a101_VEH_locState m101 : 19|1@1+ (1,0) [0|1] "" Vector__XXX
 SG_ TRCM_a101_BDY_locState m101 : 20|1@1+ (1,0) [0|1] "" Vector__XXX
 SG_ TRCM_a102_VEH_faultsAndExtras m102 : 16|1@1+ (1,0) [0|1] "" Vector__XXX
 SG_ TRCM_a102_VEH_feedbackStatus m102 : 17|1@1+ (1,0) [0|1] "" Vector__XXX
 SG_ TRCM_a102_VEH_sensorStatus m102 : 18|1@1+ (1,0) [0|1] "" Vector__XXX
 SG_ TRCM_a102_VEH_rods m102 : 19|1@1+ (1,0) [0|1] "" Vector__XXX
 SG_ TRCM_a103_VEH_hvsNm m103 : 16|1@1+ (1,0) [0|1] "" Vector__XXX
 SG_ TRCM_a103_VEH_vehNm m103 : 17|1@1+ (1,0) [0|1] "" Vector__XXX
 SG_ TRCM_a103_VEH_status m103 : 18|1@1+ (1,0) [0|1] "" Vector__XXX
 SG_ TRCM_a103_PT_ptNm m103 : 19|1@1+ (1,0) [0|1] "" Vector__XXX
 SG_ TRCM_a103_PT_status m103 : 20|1@1+ (1,0) [0|1] "" Vector__XXX
 SG_ TRCM_a103_VEH_evseStatus m103 : 21|1@1+ (1,0) [0|1] "" Vector__XXX
 SG_ TRCM_a105_VEH_states m105 : 16|1@1+ (1,0) [0|1] "" Vector__XXX
 SG_ TRCM_a105_VEH_chNm m105 : 17|1@1+ (1,0) [0|1] "" Vector__XXX
 SG_ TRCM_a105_VEH_dampingStates m105 : 18|1@1+ (1,0) [0|1] "" Vector__XXX
 SG_ TRCM_a106_VEH_dcdcStatus m106 : 16|1@1+ (1,0) [0|1] "" Vector__XXX
 SG_ TRCM_a106_VEH_thermalControl m106 : 17|1@1+ (1,0) [0|1] "" Vector__XXX
 SG_ TRCM_a106_VEH_thermalInterface m106 : 18|1@1+ (1,0) [0|1] "" Vector__XXX
 SG_ TRCM_a106_VEH_dcdcRailStatus m106 : 19|1@1+ (1,0) [0|1] "" Vector__XXX
 SG_ TRCM_a106_CH_dcdcRailStatus m106 : 20|1@1+ (1,0) [0|1] "" Vector__XXX
 SG_ TRCM_a106_CH_alertMatrix m106 : 21|1@1+ (1,0) [0|1] "" Vector__XXX
 SG_ TRCM_a107_VEH_hvsNm m107 : 16|1@1+ (1,0) [0|1] "" Vector__XXX
 SG_ TRCM_a107_VEH_vehNm m107 : 17|1@1+ (1,0) [0|1] "" Vector__XXX
 SG_ TRCM_a107_VEH_status m107 : 18|1@1+ (1,0) [0|1] "" Vector__XXX
 SG_ TRCM_a107_VEH_thermalStatus m107 : 19|1@1+ (1,0) [0|1] "" Vector__XXX
 SG_ TRCM_a107_VEH_thermalStatus2 m107 : 20|1@1+ (1,0) [0|1] "" Vector__XXX
 SG_ TRCM_a107_VEH_bmbMinMax m107 : 21|1@1+ (1,0) [0|1] "" Vector__XXX
 SG_ TRCM_a107_VEH_powerAvailable m107 : 22|1@1+ (1,0) [0|1] "" Vector__XXX
 SG_ TRCM_a107_PT_ptNm m107 : 23|1@1+ (1,0) [0|1] "" Vector__XXX
 SG_ TRCM_a107_PT_status m107 : 24|1@1+ (1,0) [0|1] "" Vector__XXX
 SG_ TRCM_a107_PT_thermalStatus m107 : 25|1@1+ (1,0) [0|1] "" Vector__XXX
 SG_ TRCM_a107_PT_socStatus m107 : 26|1@1+ (1,0) [0|1] "" Vector__XXX
 SG_ TRCM_a107_VEH_socStatus m107 : 27|1@1+ (1,0) [0|1] "" Vector__XXX
 SG_ TRCM_a107_VEH_packConfig m107 : 28|1@1+ (1,0) [0|1] "" Vector__XXX
 SG_ TRCM_a107_VEH_energyStatus m107 : 29|1@1+ (1,0) [0|1] "" Vector__XXX
 SG_ TRCM_a107_VEH_chargeInfo m107 : 30|1@1+ (1,0) [0|1] "" Vector__XXX
 SG_ TRCM_a108_VEH_hvStatus m108 : 16|1@1+ (1,0) [0|1] "" Vector__XXX
 SG_ TRCM_a108_VEH_temperature m108 : 17|1@1+ (1,0) [0|1] "" Vector__XXX
 SG_ TRCM_a108_VEH_thermalControl m108 : 18|1@1+ (1,0) [0|1] "" Vector__XXX
 SG_ TRCM_a108_VEH_torque m108 : 19|1@1+ (1,0) [0|1] "" Vector__XXX
 SG_ TRCM_a108_VEH_status m108 : 20|1@1+ (1,0) [0|1] "" Vector__XXX
 SG_ TRCM_a108_PARTY_torque m108 : 21|1@1+ (1,0) [0|1] "" Vector__XXX
 SG_ TRCM_a108_PARTY_status m108 : 22|1@1+ (1,0) [0|1] "" Vector__XXX
 SG_ TRCM_a108_PARTY_temperature m108 : 23|1@1+ (1,0) [0|1] "" Vector__XXX
 SG_ TRCM_a108_PARTY_thermalControl m108 : 24|1@1+ (1,0) [0|1] "" Vector__XXX
 SG_ TRCM_a108_PT_temperature m108 : 25|1@1+ (1,0) [0|1] "" Vector__XXX
 SG_ TRCM_a108_PT_thermalControl m108 : 26|1@1+ (1,0) [0|1] "" Vector__XXX
 SG_ TRCM_a109_PARTY_status m109 : 16|1@1+ (1,0) [0|1] "" Vector__XXX
 SG_ TRCM_a109_PARTY_inertial2 m109 : 17|1@1+ (1,0) [0|1] "" Vector__XXX
 SG_ TRCM_a109_PARTY_nearDeploy m109 : 18|1@1+ (1,0) [0|1] "" Vector__XXX
 SG_ TRCM_a109_PARTY_collision m109 : 19|1@1+ (1,0) [0|1] "" Vector__XXX
 SG_ TRCM_a109_VEH_status m109 : 20|1@1+ (1,0) [0|1] "" Vector__XXX
 SG_ TRCM_a109_VEH_imuOffsets m109 : 21|1@1+ (1,0) [0|1] "" Vector__XXX
 SG_ TRCM_a109_PARTY_inertial1 m109 : 22|1@1+ (1,0) [0|1] "" Vector__XXX
 SG_ TRCM_a109_BDY_imuOffsets m109 : 23|1@1+ (1,0) [0|1] "" Vector__XXX
 SG_ TRCM_a109_BDY_inertial1 m109 : 24|1@1+ (1,0) [0|1] "" Vector__XXX
 SG_ TRCM_a109_BDY_inertial2 m109 : 25|1@1+ (1,0) [0|1] "" Vector__XXX
 SG_ TRCM_a109_BDY_status m109 : 26|1@1+ (1,0) [0|1] "" Vector__XXX
 SG_ TRCM_a109_VEH_inertial1 m109 : 27|1@1+ (1,0) [0|1] "" Vector__XXX
 SG_ TRCM_a109_VEH_inertial2 m109 : 28|1@1+ (1,0) [0|1] "" Vector__XXX
 SG_ TRCM_a109_CH_inertial1 m109 : 29|1@1+ (1,0) [0|1] "" Vector__XXX
 SG_ TRCM_a109_CH_inertial2 m109 : 30|1@1+ (1,0) [0|1] "" Vector__XXX
 SG_ TRCM_a109_CH_status m109 : 31|1@1+ (1,0) [0|1] "" Vector__XXX
 SG_ TRCM_a110_VEH_carState m110 : 16|1@1+ (1,0) [0|1] "" Vector__XXX
 SG_ TRCM_a110_VEH_carConfig m110 : 17|1@1+ (1,0) [0|1] "" Vector__XXX
 SG_ TRCM_a110_VEH_time m110 : 18|1@1+ (1,0) [0|1] "" Vector__XXX
 SG_ TRCM_a110_VEH_updateStatus m110 : 19|1@1+ (1,0) [0|1] "" Vector__XXX
 SG_ TRCM_a110_VEH_vehNm m110 : 20|1@1+ (1,0) [0|1] "" Vector__XXX
 SG_ TRCM_a110_VEH_mismatchFault m110 : 21|1@1+ (1,0) [0|1] "" Vector__XXX
 SG_ TRCM_a110_VEH_vin m110 : 22|1@1+ (1,0) [0|1] "" Vector__XXX
 SG_ TRCM_a110_VEH_bmpDebug m110 : 23|1@1+ (1,0) [0|1] "" Vector__XXX
 SG_ TRCM_a110_VEH_gearControl m110 : 24|1@1+ (1,0) [0|1] "" Vector__XXX
 SG_ TRCM_a110_VEH_canLogAvailability m110 : 25|1@1+ (1,0) [0|1] "" Vector__XXX
 SG_ TRCM_a110_CH_airbagCutoffStatus m110 : 26|1@1+ (1,0) [0|1] "" Vector__XXX
 SG_ TRCM_a110_CH_carConfig m110 : 27|1@1+ (1,0) [0|1] "" Vector__XXX
 SG_ TRCM_a110_CH_carState m110 : 28|1@1+ (1,0) [0|1] "" Vector__XXX
 SG_ TRCM_a110_CH_vin m110 : 29|1@1+ (1,0) [0|1] "" Vector__XXX
 SG_ TRCM_a110_CH_chNm m110 : 30|1@1+ (1,0) [0|1] "" Vector__XXX
 SG_ TRCM_a110_CH_epochTimeGtw m110 : 31|1@1+ (1,0) [0|1] "" Vector__XXX
 SG_ TRCM_a111_VEH_internalStatus m111 : 16|1@1+ (1,0) [0|1] "" Vector__XXX
 SG_ TRCM_a111_VEH_status m111 : 17|1@1+ (1,0) [0|1] "" Vector__XXX
 SG_ TRCM_a111_VEH_vehNm m111 : 18|1@1+ (1,0) [0|1] "" Vector__XXX
 SG_ TRCM_a111_RIPC_LVPowerState m111 : 19|1@1+ (1,0) [0|1] "" Vector__XXX
 SG_ TRCM_a111_RIPC_epbPrivateState m111 : 20|1@1+ (1,0) [0|1] "" Vector__XXX
 SG_ TRCM_a111_RIPC_railStatus m111 : 21|1@1+ (1,0) [0|1] "" Vector__XXX
 SG_ TRCM_a111_RIPC_remoteADC m111 : 22|1@1+ (1,0) [0|1] "" Vector__XXX
 SG_ TRCM_a111_RIPC_switchStatus m111 : 23|1@1+ (1,0) [0|1] "" Vector__XXX
 SG_ TRCM_a111_VEH_LVPowerState m111 : 24|1@1+ (1,0) [0|1] "" Vector__XXX
 SG_ TRCM_a111_VEH_seatStatus m111 : 25|1@1+ (1,0) [0|1] "" Vector__XXX
 SG_ TRCM_a111_PARTY_status m111 : 26|1@1+ (1,0) [0|1] "" Vector__XXX
 SG_ TRCM_a111_CH_status m111 : 27|1@1+ (1,0) [0|1] "" Vector__XXX
 SG_ TRCM_a112_VEH_internalStatus m112 : 16|1@1+ (1,0) [0|1] "" Vector__XXX
 SG_ TRCM_a112_VEH_status m112 : 17|1@1+ (1,0) [0|1] "" Vector__XXX
 SG_ TRCM_a112_VEH_vehNm m112 : 18|1@1+ (1,0) [0|1] "" Vector__XXX
 SG_ TRCM_a112_LIPC_LVPowerState m112 : 19|1@1+ (1,0) [0|1] "" Vector__XXX
 SG_ TRCM_a112_LIPC_epbPrivateState m112 : 20|1@1+ (1,0) [0|1] "" Vector__XXX
 SG_ TRCM_a112_LIPC_railStatus m112 : 21|1@1+ (1,0) [0|1] "" Vector__XXX
 SG_ TRCM_a112_LIPC_remoteADC m112 : 22|1@1+ (1,0) [0|1] "" Vector__XXX
 SG_ TRCM_a112_LIPC_switchStatus m112 : 23|1@1+ (1,0) [0|1] "" Vector__XXX
 SG_ TRCM_a112_VEH_LVPowerState m112 : 24|1@1+ (1,0) [0|1] "" Vector__XXX
 SG_ TRCM_a112_PARTY_status m112 : 25|1@1+ (1,0) [0|1] "" Vector__XXX
 SG_ TRCM_a112_CH_status m112 : 26|1@1+ (1,0) [0|1] "" Vector__XXX
 SG_ TRCM_a114_PARTY_status m114 : 16|1@1+ (1,0) [0|1] "" Vector__XXX
 SG_ TRCM_a114_PARTY_wheelSpeeds m114 : 17|1@1+ (1,0) [0|1] "" Vector__XXX
 SG_ TRCM_a114_VEH_wheelSpeeds m114 : 18|1@1+ (1,0) [0|1] "" Vector__XXX
 SG_ TRCM_a114_CH_wheelSpeeds m114 : 19|1@1+ (1,0) [0|1] "" Vector__XXX
 SG_ TRCM_a114_PARTY_party3 m114 : 20|1@1+ (1,0) [0|1] "" Vector__XXX
 SG_ TRCM_a114_VEH_party3 m114 : 21|1@1+ (1,0) [0|1] "" Vector__XXX
 SG_ TRCM_a114_VEH_status m114 : 22|1@1+ (1,0) [0|1] "" Vector__XXX
 SG_ TRCM_a114_PARTY_wheelRotation m114 : 23|1@1+ (1,0) [0|1] "" Vector__XXX
 SG_ TRCM_a114_CH_wheelRotation m114 : 24|1@1+ (1,0) [0|1] "" Vector__XXX
 SG_ TRCM_a114_VEH_wheelRotation m114 : 25|1@1+ (1,0) [0|1] "" Vector__XXX
 SG_ TRCM_a114_PARTY_brakeTorque m114 : 26|1@1+ (1,0) [0|1] "" Vector__XXX
 SG_ TRCM_a114_PARTY_offsets m114 : 27|1@1+ (1,0) [0|1] "" Vector__XXX
 SG_ TRCM_a114_BDY_offsets m114 : 28|1@1+ (1,0) [0|1] "" Vector__XXX
 SG_ TRCM_a114_BDY_party3 m114 : 29|1@1+ (1,0) [0|1] "" Vector__XXX
 SG_ TRCM_a114_BDY_status m114 : 30|1@1+ (1,0) [0|1] "" Vector__XXX
 SG_ TRCM_a114_BDY_wheelRotation m114 : 31|1@1+ (1,0) [0|1] "" Vector__XXX
 SG_ TRCM_a114_BDY_wheelSpeeds m114 : 32|1@1+ (1,0) [0|1] "" Vector__XXX
 SG_ TRCM_a114_CH_party1 m114 : 33|1@1+ (1,0) [0|1] "" Vector__XXX
 SG_ TRCM_a114_CH_party3 m114 : 34|1@1+ (1,0) [0|1] "" Vector__XXX
 SG_ TRCM_a114_CH_status m114 : 35|1@1+ (1,0) [0|1] "" Vector__XXX
 SG_ TRCM_a115_VEH_vehNm m115 : 16|1@1+ (1,0) [0|1] "" Vector__XXX
 SG_ TRCM_a115_VEH_authentication m115 : 17|1@1+ (1,0) [0|1] "" Vector__XXX
 SG_ TRCM_a115_VEH_BLEResetRequest m115 : 18|1@1+ (1,0) [0|1] "" Vector__XXX
 SG_ TRCM_a115_VEH_requests m115 : 19|1@1+ (1,0) [0|1] "" Vector__XXX
 SG_ TRCM_a115_VEH_requests2 m115 : 20|1@1+ (1,0) [0|1] "" Vector__XXX
 SG_ TRCM_a115_REM_authentication m115 : 21|1@1+ (1,0) [0|1] "" Vector__XXX
 SG_ TRCM_a115_UI_corianderVehicleCon m115 : 22|1@1+ (1,0) [0|1] "" Vector__XXX
 SG_ TRCM_a115_CH_TPMSDisplay m115 : 23|1@1+ (1,0) [0|1] "" Vector__XXX
 SG_ TRCM_a116_PARTY_epbmStatus m116 : 16|1@1+ (1,0) [0|1] "" Vector__XXX
 SG_ TRCM_a116_VEH_vehNm m116 : 17|1@1+ (1,0) [0|1] "" Vector__XXX
 SG_ TRCM_a116_VEH_hvacRequest m116 : 18|1@1+ (1,0) [0|1] "" Vector__XXX
 SG_ TRCM_a116_VEH_hvacStatus m116 : 19|1@1+ (1,0) [0|1] "" Vector__XXX
 SG_ TRCM_a116_VEH_LVPowerState m116 : 20|1@1+ (1,0) [0|1] "" Vector__XXX
 SG_ TRCM_a116_VEH_lightStatus m116 : 21|1@1+ (1,0) [0|1] "" Vector__XXX
 SG_ TRCM_a116_VEH_seatStatus m116 : 22|1@1+ (1,0) [0|1] "" Vector__XXX
 SG_ TRCM_a116_VEH_thsStatus m116 : 23|1@1+ (1,0) [0|1] "" Vector__XXX
 SG_ TRCM_a116_VEH_doorStatus m116 : 24|1@1+ (1,0) [0|1] "" Vector__XXX
 SG_ TRCM_a116_VEH_seatHeatStatus m116 : 25|1@1+ (1,0) [0|1] "" Vector__XXX
 SG_ TRCM_a116_VEH_restraintStatus m116 : 26|1@1+ (1,0) [0|1] "" Vector__XXX
 SG_ TRCM_a116_VEH_switchStatus m116 : 27|1@1+ (1,0) [0|1] "" Vector__XXX
 SG_ TRCM_a116_VEH_logging1Hz m116 : 28|1@1+ (1,0) [0|1] "" Vector__XXX
 SG_ TRCM_a116_VEH_seatStatus2 m116 : 29|1@1+ (1,0) [0|1] "" Vector__XXX
 SG_ TRCM_a116_VEH_status m116 : 30|1@1+ (1,0) [0|1] "" Vector__XXX
 SG_ TRCM_a116_VEH_thermalCommand m116 : 31|1@1+ (1,0) [0|1] "" Vector__XXX
 SG_ TRCM_a116_VEH_windowStatus m116 : 32|1@1+ (1,0) [0|1] "" Vector__XXX
 SG_ TRCM_a116_PARTY_restraintStatus m116 : 33|1@1+ (1,0) [0|1] "" Vector__XXX
 SG_ TRCM_a116_PARTY_doorStatus m116 : 34|1@1+ (1,0) [0|1] "" Vector__XXX
 SG_ TRCM_a116_BDY_epbmStatus m116 : 35|1@1+ (1,0) [0|1] "" Vector__XXX
 SG_ TRCM_a116_BDY_restraintStatus m116 : 36|1@1+ (1,0) [0|1] "" Vector__XXX
 SG_ TRCM_a117_BDY_epbmStatus m117 : 16|1@1+ (1,0) [0|1] "" Vector__XXX
 SG_ TRCM_a117_BDY_restraintStatus m117 : 17|1@1+ (1,0) [0|1] "" Vector__XXX
 SG_ TRCM_a117_VEH_prndStatus m117 : 18|1@1+ (1,0) [0|1] "" Vector__XXX
 SG_ TRCM_a117_PARTY_epbmStatus m117 : 19|1@1+ (1,0) [0|1] "" Vector__XXX
 SG_ TRCM_a117_VEH_vehNm m117 : 20|1@1+ (1,0) [0|1] "" Vector__XXX
 SG_ TRCM_a117_VEH_hvacBlowerFdb m117 : 21|1@1+ (1,0) [0|1] "" Vector__XXX
 SG_ TRCM_a117_VEH_LVPowerState m117 : 22|1@1+ (1,0) [0|1] "" Vector__XXX
 SG_ TRCM_a117_VEH_restraintStatus m117 : 23|1@1+ (1,0) [0|1] "" Vector__XXX
 SG_ TRCM_a117_VEH_lightStatus m117 : 24|1@1+ (1,0) [0|1] "" Vector__XXX
 SG_ TRCM_a117_VEH_seatStatus m117 : 25|1@1+ (1,0) [0|1] "" Vector__XXX
 SG_ TRCM_a117_BDY_falconSwitchStatus m117 : 26|1@1+ (1,0) [0|1] "" Vector__XXX
 SG_ TRCM_a117_VEH_doorStatus m117 : 27|1@1+ (1,0) [0|1] "" Vector__XXX
 SG_ TRCM_a117_VEH_doorStatus2 m117 : 28|1@1+ (1,0) [0|1] "" Vector__XXX
 SG_ TRCM_a117_VEH_windowStatus m117 : 29|1@1+ (1,0) [0|1] "" Vector__XXX
 SG_ TRCM_a117_VEH_switchStatus m117 : 30|1@1+ (1,0) [0|1] "" Vector__XXX
 SG_ TRCM_a117_VEH_intrusionSensorSta m117 : 31|1@1+ (1,0) [0|1] "" Vector__XXX
 SG_ TRCM_a117_VEH_liftgateStatus m117 : 32|1@1+ (1,0) [0|1] "" Vector__XXX
 SG_ TRCM_a117_VEH_seatStatus2 m117 : 33|1@1+ (1,0) [0|1] "" Vector__XXX
 SG_ TRCM_a117_PARTY_restraintStatus m117 : 34|1@1+ (1,0) [0|1] "" Vector__XXX
 SG_ TRCM_a117_VEH_thermalStatus m117 : 35|1@1+ (1,0) [0|1] "" Vector__XXX
 SG_ TRCM_a117_PARTY_doorStatus m117 : 36|1@1+ (1,0) [0|1] "" Vector__XXX
 SG_ TRCM_a117_VEH_status m117 : 37|1@1+ (1,0) [0|1] "" Vector__XXX
 SG_ TRCM_a117_PARTY_prndStatus m117 : 38|1@1+ (1,0) [0|1] "" Vector__XXX
 SG_ TRCM_a118_VEH_vehNm m118 : 16|1@1+ (1,0) [0|1] "" Vector__XXX
 SG_ TRCM_a118_VEH_lighting m118 : 17|1@1+ (1,0) [0|1] "" Vector__XXX
 SG_ TRCM_a118_VEH_sensors m118 : 18|1@1+ (1,0) [0|1] "" Vector__XXX
 SG_ TRCM_a118_VEH_status m118 : 19|1@1+ (1,0) [0|1] "" Vector__XXX
 SG_ TRCM_a118_VEH_okToUseHighPwr m118 : 20|1@1+ (1,0) [0|1] "" Vector__XXX
 SG_ TRCM_a118_VEH_LVPowerState m118 : 21|1@1+ (1,0) [0|1] "" Vector__XXX
 SG_ TRCM_a118_VEH_coolant m118 : 22|1@1+ (1,0) [0|1] "" Vector__XXX
 SG_ TRCM_a118_VEH_vehicleStatus m118 : 23|1@1+ (1,0) [0|1] "" Vector__XXX
 SG_ TRCM_a118_VEH_12VBatteryStatus m118 : 24|1@1+ (1,0) [0|1] "" Vector__XXX
 SG_ TRCM_a118_VEH_systemStatus m118 : 25|1@1+ (1,0) [0|1] "" Vector__XXX
 SG_ TRCM_a118_PARTY_LVPowerState m118 : 26|1@1+ (1,0) [0|1] "" Vector__XXX
 SG_ TRCM_a118_PARTY_outputPowerStatu m118 : 27|1@1+ (1,0) [0|1] "" Vector__XXX
 SG_ TRCM_a118_PARTY_vehicleTime m118 : 28|1@1+ (1,0) [0|1] "" Vector__XXX
 SG_ TRCM_a118_VEH_thermalCommand m118 : 29|1@1+ (1,0) [0|1] "" Vector__XXX
 SG_ TRCM_a118_CH_LVPowerState m118 : 30|1@1+ (1,0) [0|1] "" Vector__XXX
 SG_ TRCM_a118_PARTY_sensors m118 : 31|1@1+ (1,0) [0|1] "" Vector__XXX
 SG_ TRCM_a118_CH_sensors m118 : 32|1@1+ (1,0) [0|1] "" Vector__XXX
 SG_ TRCM_a118_VEH_interNodeResistanc m118 : 33|1@1+ (1,0) [0|1] "" Vector__XXX
 SG_ TRCM_a118_CH_lighting m118 : 34|1@1+ (1,0) [0|1] "" Vector__XXX
 SG_ TRCM_a118_VEH_lightStatus m118 : 35|1@1+ (1,0) [0|1] "" Vector__XXX
 SG_ TRCM_a118_PARTY_vehNm m118 : 36|1@1+ (1,0) [0|1] "" Vector__XXX
 SG_ TRCM_a118_CH_12VBatteryStatus m118 : 37|1@1+ (1,0) [0|1] "" Vector__XXX
 SG_ TRCM_a118_CH_LVBMS_statusHigh m118 : 38|1@1+ (1,0) [0|1] "" Vector__XXX
 SG_ TRCM_a118_CH_alertMatrix m118 : 39|1@1+ (1,0) [0|1] "" Vector__XXX
 SG_ TRCM_a118_BDY_outputPowerStatus m118 : 40|1@1+ (1,0) [0|1] "" Vector__XXX
 SG_ TRCM_a118_BDY_vehicleTime m118 : 41|1@1+ (1,0) [0|1] "" Vector__XXX
 SG_ TRCM_a118_PARTY_AP_vehicleState1 m118 : 42|1@1+ (1,0) [0|1] "" Vector__XXX
 SG_ TRCM_a118_BDY_AP_vehicleState1Hz m118 : 43|1@1+ (1,0) [0|1] "" Vector__XXX
 SG_ TRCM_a119_VEH_steerAngle m119 : 16|1@1+ (1,0) [0|1] "" Vector__XXX
 SG_ TRCM_a119_VEH_leftStalk m119 : 17|1@1+ (1,0) [0|1] "" Vector__XXX
 SG_ TRCM_a119_VEH_rightStalk m119 : 18|1@1+ (1,0) [0|1] "" Vector__XXX
 SG_ TRCM_a119_PARTY_rightStalk m119 : 19|1@1+ (1,0) [0|1] "" Vector__XXX
 SG_ TRCM_a119_CH_steerAngle m119 : 20|1@1+ (1,0) [0|1] "" Vector__XXX
 SG_ TRCM_a119_PARTY_steerAngle m119 : 21|1@1+ (1,0) [0|1] "" Vector__XXX
 SG_ TRCM_a120_PARTY_chassisCntl m120 : 16|1@1+ (1,0) [0|1] "" Vector__XXX
 SG_ TRCM_a120_VEH_systemStatus m120 : 17|1@1+ (1,0) [0|1] "" Vector__XXX
 SG_ TRCM_a120_CH_chassisCntl m120 : 18|1@1+ (1,0) [0|1] "" Vector__XXX
 SG_ TRCM_a120_PARTY_systemStatus m120 : 19|1@1+ (1,0) [0|1] "" Vector__XXX
 SG_ TRCM_a120_PARTY_torque m120 : 20|1@1+ (1,0) [0|1] "" Vector__XXX
 SG_ TRCM_a120_VEH_torque m120 : 21|1@1+ (1,0) [0|1] "" Vector__XXX
 SG_ TRCM_a120_PARTY_locStatus m120 : 22|1@1+ (1,0) [0|1] "" Vector__XXX
 SG_ TRCM_a120_PARTY_speed m120 : 23|1@1+ (1,0) [0|1] "" Vector__XXX
 SG_ TRCM_a120_VEH_speed m120 : 24|1@1+ (1,0) [0|1] "" Vector__XXX
 SG_ TRCM_a120_PARTY_status m120 : 25|1@1+ (1,0) [0|1] "" Vector__XXX
 SG_ TRCM_a120_PT_speed m120 : 26|1@1+ (1,0) [0|1] "" Vector__XXX
 SG_ TRCM_a120_PT_systemStatus m120 : 27|1@1+ (1,0) [0|1] "" Vector__XXX
 SG_ TRCM_a120_PARTY_vehicleEstimates m120 : 28|1@1+ (1,0) [0|1] "" Vector__XXX
 SG_ TRCM_a120_VEH_aggregatedAxleSpee m120 : 29|1@1+ (1,0) [0|1] "" Vector__XXX
 SG_ TRCM_a120_PARTY_aggregatedAxleSp m120 : 30|1@1+ (1,0) [0|1] "" Vector__XXX
 SG_ TRCM_a120_VEH_systemPower m120 : 31|1@1+ (1,0) [0|1] "" Vector__XXX
 SG_ TRCM_a120_PT_systemPower m120 : 32|1@1+ (1,0) [0|1] "" Vector__XXX
 SG_ TRCM_a120_PARTY_stalklessInterfa m120 : 33|1@1+ (1,0) [0|1] "" Vector__XXX
 SG_ TRCM_a120_CH_speed m120 : 34|1@1+ (1,0) [0|1] "" Vector__XXX
 SG_ TRCM_a120_VEH_estimatedBrakeTemp m120 : 35|1@1+ (1,0) [0|1] "" Vector__XXX
 SG_ TRCM_a120_PARTY_prndControl m120 : 36|1@1+ (1,0) [0|1] "" Vector__XXX
 SG_ TRCM_a120_PARTY_locStatus2 m120 : 37|1@1+ (1,0) [0|1] "" Vector__XXX
 SG_ TRCM_a120_VEH_chassisCntl m120 : 38|1@1+ (1,0) [0|1] "" Vector__XXX
 SG_ TRCM_a120_VEH_locStatus m120 : 39|1@1+ (1,0) [0|1] "" Vector__XXX
 SG_ TRCM_a120_VEH_locStatus2 m120 : 40|1@1+ (1,0) [0|1] "" Vector__XXX
 SG_ TRCM_a120_VEH_prndControl m120 : 41|1@1+ (1,0) [0|1] "" Vector__XXX
 SG_ TRCM_a120_VEH_vehicleEstimates m120 : 42|1@1+ (1,0) [0|1] "" Vector__XXX

BO_TX_BU_ 852 : TAS;
BO_TX_BU_ 523 : TAS;
BO_TX_BU_ 1398 : TAS;
BO_TX_BU_ 1357 : TAS;
BO_TX_BU_ 525 : TAS;
BO_TX_BU_ 409 : TAS;
BO_TX_BU_ 410 : TAS;
BO_TX_BU_ 538 : TAS;
BO_TX_BU_ 1410 : TCU;
BO_TX_BU_ 1472 : TCU;
BO_TX_BU_ 1409 : TCU;
BO_TX_BU_ 1408 : TCU;
BO_TX_BU_ 879 : TPMS;
BO_TX_BU_ 802 : TPMS;
BO_TX_BU_ 1519 : TPMS;
BO_TX_BU_ 1298 : TRCM;
CM_ BO_ 852 "Air suspension controller message: alert matrix";
CM_ SG_ 852 TAS_matrixIndex "Air suspension controller: matrix index";
CM_ SG_ 852 TAS_a001_WatchdogReset "Air suspension controller: a001 watchdog reset";
CM_ SG_ 852 TAS_a002_PowerLossReset "Air suspension controller: a002 power loss reset";
CM_ SG_ 852 TAS_a003_SWAssertion "Air suspension controller: a003 SW assertion";
CM_ SG_ 852 TAS_a012_CPUReset "Air suspension controller: a012 CPU reset";
CM_ SG_ 852 TAS_a015_NVMMError "Air suspension controller: a015 NVMM error";
CM_ SG_ 852 TAS_a016_NVMMRecordError "Air suspension controller: a016 NVMM record error";
CM_ SG_ 852 TAS_a021_TaskSchedulerError "Air suspension controller: a021 task scheduler error";
CM_ SG_ 852 TAS_a022_TaskInitError "Air suspension controller: a022 task init error";
CM_ SG_ 852 TAS_a023_rtosResetRequested "Air suspension controller: a023 rtos reset requested";
CM_ SG_ 852 TAS_a024_prefetchAbort "Air suspension controller: a024 prefetch abort";
CM_ SG_ 852 TAS_a025_CrashEvent "Air suspension controller: a025 crash event";
CM_ SG_ 852 TAS_a030_PWMerrorFL "Air suspension controller: a030 PW merror FL";
CM_ SG_ 852 TAS_a031_PWMerrorFR "Air suspension controller: a031 PW merror FR";
CM_ SG_ 852 TAS_a032_PWMerrorRL "Air suspension controller: a032 PW merror RL";
CM_ SG_ 852 TAS_a033_PWMerrorRR "Air suspension controller: a033 PW merror RR";
CM_ SG_ 852 TAS_a034_PWMshortFL "Air suspension controller: a034 PW mshort FL";
CM_ SG_ 852 TAS_a035_PWMshortFR "Air suspension controller: a035 PW mshort FR";
CM_ SG_ 852 TAS_a036_PWMshortRL "Air suspension controller: a036 PW mshort RL";
CM_ SG_ 852 TAS_a037_PWMshortRR "Air suspension controller: a037 PW mshort RR";
CM_ SG_ 852 TAS_a038_PWMopenFL "Air suspension controller: a038 PW mopen FL";
CM_ SG_ 852 TAS_a039_PWMopenFR "Air suspension controller: a039 PW mopen FR";
CM_ SG_ 852 TAS_a040_PWMopenRL "Air suspension controller: a040 PW mopen RL";
CM_ SG_ 852 TAS_a041_PWMopenRR "Air suspension controller: a041 PW mopen RR";
CM_ SG_ 852 TAS_a043_Task1msError "Air suspension controller: a043 task1ms error";
CM_ SG_ 852 TAS_a044_Task10msError "Air suspension controller: a044 task10ms error";
CM_ SG_ 852 TAS_a045_Task100msError "Air suspension controller: a045 task100ms error";
CM_ SG_ 852 TAS_a046_Task1000msError "Air suspension controller: a046 task1000ms error";
CM_ SG_ 852 TAS_a061_XCPConnected "Air suspension controller: a061 XCP connected";
CM_ SG_ 852 TAS_a062_XCPWasConnected "Air suspension controller: a062 XCP was connected";
CM_ SG_ 852 TAS_a063_abortFault "Air suspension controller: a063 abort fault";
CM_ SG_ 852 TAS_a064_abortFaultExt "Air suspension controller: a064 abort fault ext";
CM_ SG_ 852 TAS_a065_ahbWriteFault "Air suspension controller: a065 ahb write fault";
CM_ SG_ 852 TAS_a066_undefinedInstructionAbo "Air suspension controller: a066 undefined instruction abort";
CM_ SG_ 852 TAS_a067_reservedHandlerAbort "Air suspension controller: a067 reserved handler abort";
CM_ SG_ 852 TAS_a070_underVoltage12V "Air suspension controller: a070 under voltage12 v";
CM_ SG_ 852 TAS_a071_overVoltage12V "Air suspension controller: a071 over voltage12 v";
CM_ SG_ 852 TAS_a072_shortCircuit5VOnBoard "Air suspension controller: a072 short circuit5 v on board";
CM_ SG_ 852 TAS_a073_underVoltage5VOnBoard "Air suspension controller: a073 under voltage5 v on board";
CM_ SG_ 852 TAS_a074_shortCircuit5VOffBoard "Air suspension controller: a074 short circuit5 v off board";
CM_ SG_ 852 TAS_a075_underVoltage5VOffBoard "Air suspension controller: a075 under voltage5 v off board";
CM_ SG_ 852 TAS_a076_overVoltage5VOffBoard "Air suspension controller: a076 over voltage5 v off board";
CM_ SG_ 852 TAS_a077_pressureSigVTooLow "Air suspension controller: a077 pressure sig v too low";
CM_ SG_ 852 TAS_a078_pressureSigVTooHigh "Air suspension controller: a078 pressure sig v too high";
CM_ SG_ 852 TAS_a080_shortCircuit5VHeight "Air suspension controller: a080 short circuit5 v height";
CM_ SG_ 852 TAS_a081_underVoltage5VHeight "Air suspension controller: a081 under voltage5 v height";
CM_ SG_ 852 TAS_a082_overVoltage5VHeight "Air suspension controller: a082 over voltage5 v height";
CM_ SG_ 852 TAS_a083_shortCircuit5VAnalog "Air suspension controller: a083 short circuit5 v analog";
CM_ SG_ 852 TAS_a084_underVoltage5VAnalog "Air suspension controller: a084 under voltage5 v analog";
CM_ SG_ 852 TAS_a085_overVoltage5VAnalog "Air suspension controller: a085 over voltage5 v analog";
CM_ SG_ 852 TAS_a086_underVoltage12VSwtchd "Air suspension controller: a086 under voltage12 v swtchd";
CM_ SG_ 852 TAS_a087_overVoltage12VSwtchd "Air suspension controller: a087 over voltage12 v swtchd";
CM_ SG_ 852 TAS_a093_OTPError "Air suspension controller: a093 OTP error";
CM_ SG_ 852 TAS_a098_VCFRONT_MIA "Air suspension controller: a098 VCFRONT MIA";
CM_ SG_ 852 TAS_a099_UI_MIA "Air suspension controller: a099 UI MIA";
CM_ SG_ 852 TAS_a100_RCM_MIA "Air suspension controller: a100 RCM MIA";
CM_ SG_ 852 TAS_a101_ESP_MIA "Air suspension controller: a101 ESP MIA";
CM_ SG_ 852 TAS_a102_DI_MIA "Air suspension controller: a102 DI MIA";
CM_ SG_ 852 TAS_a103_GTW_MIA "Air suspension controller: a103 GTW MIA";
CM_ SG_ 852 TAS_a105_ECUDebugMode "Air suspension controller: a105 ECU debug mode";
CM_ SG_ 852 TAS_a106_HighCPULoad "Air suspension controller: a106 high CPU load";
CM_ SG_ 852 TAS_a107_HighStackUsage "Air suspension controller: a107 high stack usage";
CM_ SG_ 852 TAS_a150_accelAvgImplausible_FL_ "Air suspension controller: a150 accel avg implausible FL x";
CM_ SG_ 852 TAS_a151_accelAvgImplausible_FL_ "Air suspension controller: a151 accel avg implausible FL y";
CM_ SG_ 852 TAS_a152_accelAvgImplausible_FL_ "Air suspension controller: a152 accel avg implausible FL z";
CM_ SG_ 852 TAS_a153_accelAvgImplausible_FR_ "Air suspension controller: a153 accel avg implausible FR x";
CM_ SG_ 852 TAS_a154_accelAvgImplausible_FR_ "Air suspension controller: a154 accel avg implausible FR y";
CM_ SG_ 852 TAS_a155_accelAvgImplausible_FR_ "Air suspension controller: a155 accel avg implausible FR z";
CM_ SG_ 852 TAS_a156_accelAvgImplausible_RL_ "Air suspension controller: a156 accel avg implausible RL x";
CM_ SG_ 852 TAS_a157_accelAvgImplausible_RL_ "Air suspension controller: a157 accel avg implausible RL y";
CM_ SG_ 852 TAS_a158_accelAvgImplausible_RL_ "Air suspension controller: a158 accel avg implausible RL z";
CM_ SG_ 852 TAS_a159_accelAvgImplausible_RR_ "Air suspension controller: a159 accel avg implausible RR x";
CM_ SG_ 852 TAS_a160_accelAvgImplausible_RR_ "Air suspension controller: a160 accel avg implausible RR y";
CM_ SG_ 852 TAS_a161_accelAvgImplausible_RR_ "Air suspension controller: a161 accel avg implausible RR z";
CM_ SG_ 852 TAS_a164_damperSolenoidMismatch "Air suspension controller: a164 damper solenoid mismatch";
CM_ SG_ 852 TAS_a165_damperValveCompFL "Air suspension controller: a165 damper valve comp FL";
CM_ SG_ 852 TAS_a166_damperValveRbndFL "Air suspension controller: a166 damper valve rbnd FL";
CM_ SG_ 852 TAS_a167_damperValveCompFR "Air suspension controller: a167 damper valve comp FR";
CM_ SG_ 852 TAS_a168_damperValveRbndFR "Air suspension controller: a168 damper valve rbnd FR";
CM_ SG_ 852 TAS_a169_damperValveCompRL "Air suspension controller: a169 damper valve comp RL";
CM_ SG_ 852 TAS_a170_damperValveRbndRL "Air suspension controller: a170 damper valve rbnd RL";
CM_ SG_ 852 TAS_a171_damperValveCompRR "Air suspension controller: a171 damper valve comp RR";
CM_ SG_ 852 TAS_a172_damperValveRbndRR "Air suspension controller: a172 damper valve rbnd RR";
CM_ SG_ 852 TAS_a173_staticLeakDetectFL "Air suspension controller: a173 static leak detect FL";
CM_ SG_ 852 TAS_a174_staticLeakDetectFR "Air suspension controller: a174 static leak detect FR";
CM_ SG_ 852 TAS_a175_staticLeakDetectRL "Air suspension controller: a175 static leak detect RL";
CM_ SG_ 852 TAS_a176_staticLeakDetectRR "Air suspension controller: a176 static leak detect RR";
CM_ SG_ 852 TAS_a190_a2bFrontAxleFault "Air suspension controller: a190 a2b front axle fault";
CM_ SG_ 852 TAS_a191_a2bRearAxleFault "Air suspension controller: a191 a2b rear axle fault";
CM_ SG_ 852 TAS_a192_rideHeightObserverDiver "Air suspension controller: a192 ride height observer divergence";
CM_ SG_ 852 TAS_a193_EPAS3P_MIA "Air suspension controller: a193 EPAS3 p MIA";
CM_ SG_ 852 TAS_a194_a2bFrontAxleDataError "Air suspension controller: a194 a2b front axle data error";
CM_ SG_ 852 TAS_a195_a2bRearAxleDataError "Air suspension controller: a195 a2b rear axle data error";
CM_ SG_ 852 TAS_a196_adaptiveDampingUsingDSP "Air suspension controller: a196 adaptive damping using DSP";
CM_ SG_ 852 TAS_a197_invalidAdaptiveModeRequ "Air suspension controller: a197 invalid adaptive mode requested";
CM_ SG_ 852 TAS_a200_jackModeActive "Air suspension controller: a200 jack mode active";
CM_ SG_ 852 TAS_a201_low12VBattery "Air suspension controller: a201 low12 v battery";
CM_ SG_ 852 TAS_a210_outOfRangeCalibration "Air suspension controller: a210 out of range calibration";
CM_ SG_ 852 TAS_a211_noRideHeightCalib "Air suspension controller: a211 no ride height calib";
CM_ SG_ 852 TAS_a213_yellowWarningLamp "Air suspension controller: a213 yellow warning lamp";
CM_ SG_ 852 TAS_a214_redWarningLamp "Air suspension controller: a214 red warning lamp";
CM_ SG_ 852 TAS_a215_limpHomeMode10 "Air suspension controller: a215 limp home mode10";
CM_ SG_ 852 TAS_a216_limpHomeMode20 "Air suspension controller: a216 limp home mode20";
CM_ SG_ 852 TAS_a217_limpHomeMode30 "Air suspension controller: a217 limp home mode30";
CM_ SG_ 852 TAS_a218_limpHomeMode40 "Air suspension controller: a218 limp home mode40";
CM_ SG_ 852 TAS_a220_exhaustGalleryFault "Air suspension controller: a220 exhaust gallery fault";
CM_ SG_ 852 TAS_a221_valveLeakDetected "Air suspension controller: a221 valve leak detected";
CM_ SG_ 852 TAS_a222_compressorPrefillFault "Air suspension controller: a222 compressor prefill fault";
CM_ SG_ 852 TAS_a223_blockedAirline "Air suspension controller: a223 blocked airline";
CM_ SG_ 852 TAS_a224_openAirline "Air suspension controller: a224 open airline";
CM_ SG_ 852 TAS_a225_galleryPressureTooHigh "Air suspension controller: a225 gallery pressure too high";
CM_ SG_ 852 TAS_a226_PWMfastDetectFL "Air suspension controller: a226 PW mfast detect FL";
CM_ SG_ 852 TAS_a227_PWMfastDetectFR "Air suspension controller: a227 PW mfast detect FR";
CM_ SG_ 852 TAS_a228_PWMfastDetectRL "Air suspension controller: a228 PW mfast detect RL";
CM_ SG_ 852 TAS_a229_PWMfastDetectRR "Air suspension controller: a229 PW mfast detect RR";
CM_ SG_ 852 TAS_a230_notifyGeofence "Air suspension controller: a230 notify geofence";
CM_ SG_ 852 TAS_a231_notifyRoughRoadRaise "Air suspension controller: a231 notify rough road raise";
CM_ SG_ 852 TAS_a232_suspensionTypeMismatch "Air suspension controller: a232 suspension type mismatch";
CM_ SG_ 852 TAS_a233_compressorStuckOn "Air suspension controller: a233 compressor stuck on";
CM_ SG_ 852 TAS_a234_damperHydraulicMismatch "Air suspension controller: a234 damper hydraulic mismatch";
CM_ SG_ 852 TAS_a240_airSpringLeak "Air suspension controller: a240 air spring leak";
CM_ SG_ 852 TAS_a284_serviceRunModeActive "Air suspension controller: a284 service run mode active";
CM_ SG_ 852 TAS_a285_twistSustainedUserVis "Air suspension controller: a285 twist sustained user vis";
CM_ SG_ 852 TAS_a286_driveCycleStats1 "Air suspension controller: a286 drive cycle stats1";
CM_ SG_ 852 TAS_a287_driveCycleStats2 "Air suspension controller: a287 drive cycle stats2";
CM_ SG_ 852 TAS_a288_driveCycleStats3 "Air suspension controller: a288 drive cycle stats3";
CM_ SG_ 852 TAS_a289_driveCycleStats4 "Air suspension controller: a289 drive cycle stats4";
CM_ SG_ 852 TAS_a290_twistSustainedAtSpeed "Air suspension controller: a290 twist sustained at speed";
CM_ SG_ 852 TAS_a291_frontAxleTooHigh "Air suspension controller: a291 front axle too high";
CM_ SG_ 852 TAS_a292_rearAxleTooHigh "Air suspension controller: a292 rear axle too high";
CM_ SG_ 852 TAS_a293_frontAxleTooLow "Air suspension controller: a293 front axle too low";
CM_ SG_ 852 TAS_a294_rearAxleTooLow "Air suspension controller: a294 rear axle too low";
CM_ SG_ 852 TAS_a295_targetHeightNotMet "Air suspension controller: a295 target height not met";
CM_ SG_ 852 TAS_a296_chassisTypeMismatch "Air suspension controller: a296 chassis type mismatch";
CM_ SG_ 852 TAS_a297_vinMismatch "Air suspension controller: a297 vin mismatch";
CM_ SG_ 852 TAS_a298_vinNotLearned "Air suspension controller: a298 vin not learned";
CM_ SG_ 852 TAS_a299_offsetEstimateTooLarge "Air suspension controller: a299 offset estimate too large";
CM_ SG_ 852 TAS_a300_offsetEstimateData1 "Air suspension controller: a300 offset estimate data1";
CM_ SG_ 852 TAS_a301_offsetEstimateData2 "Air suspension controller: a301 offset estimate data2";
CM_ SG_ 852 TAS_a303_massEstimateFrozen "Air suspension controller: a303 mass estimate frozen";
CM_ SG_ 852 TAS_a304_massEstimateFrozenData "Air suspension controller: a304 mass estimate frozen data";
CM_ SG_ 852 TAS_a305_newEndstopPosition "Air suspension controller: a305 new endstop position";
CM_ SG_ 852 TAS_a306_hardwareProtectFrozen "Air suspension controller: a306 hardware protect frozen";
CM_ SG_ 852 TAS_a307_endstopBoundaryComp "Air suspension controller: a307 endstop boundary comp";
CM_ SG_ 852 TAS_a308_endstopBoundaryRbnd "Air suspension controller: a308 endstop boundary rbnd";
CM_ SG_ 852 TAS_a309_controlFrozen "Air suspension controller: a309 control frozen";
CM_ SG_ 852 TAS_a310_controlFrozenData "Air suspension controller: a310 control frozen data";
CM_ SG_ 852 TAS_a311_accelsMIA "Air suspension controller: a311 accels MIA";
CM_ SG_ 852 TAS_a312_rotationalRatesMIA "Air suspension controller: a312 rotational rates MIA";
CM_ SG_ 852 TAS_a313_dampingCntrlDisabled "Air suspension controller: a313 damping cntrl disabled";
CM_ SG_ 852 TAS_a314_dampingReduced "Air suspension controller: a314 damping reduced";
CM_ SG_ 852 TAS_a315_pcbaHighTemp "Air suspension controller: a315 pcba high temp";
CM_ SG_ 852 TAS_a316_offsetsAccels "Air suspension controller: a316 offsets accels";
CM_ SG_ 852 TAS_a317_offsetsRotationalRates "Air suspension controller: a317 offsets rotational rates";
CM_ SG_ 852 TAS_a318_dampingCntrlInputMIA "Air suspension controller: a318 damping cntrl input MIA";
CM_ SG_ 852 TAS_a319_drivetrainTypeMismatch "Air suspension controller: a319 drivetrain type mismatch";
CM_ SG_ 852 TAS_a320_offsetsRotationalRates "Air suspension controller: a320 offsets rotational rates";
CM_ SG_ 852 TAS_a321_speedBumpAttributes1 "Air suspension controller: a321 speed bump attributes1";
CM_ SG_ 852 TAS_a322_speedBumpAttributes2 "Air suspension controller: a322 speed bump attributes2";
CM_ SG_ 852 TAS_a332_levelingThresholds1 "Air suspension controller: a332 leveling thresholds1";
CM_ SG_ 852 TAS_a333_levelingThresholds2 "Air suspension controller: a333 leveling thresholds2";
CM_ BO_ 523 "Air suspension controller message: axle data";
CM_ SG_ 523 TAS_axleIndex "Air suspension controller: axle index";
CM_ SG_ 523 TAS_rawHeightFL "Current height of the FL air spring.; raw 1023 = signal not available (SNA)";
CM_ SG_ 523 TAS_staticHeightEstimateFL "Current static height estimate of the FL air spring.; raw 1023 = signal not available (SNA)";
CM_ SG_ 523 TAS_componentPressureFL "Current static pressure of the FL air spring.; raw 255 = signal not available (SNA)";
CM_ SG_ 523 TAS_rawHeightFR "Current height of the FR air spring.; raw 1023 = signal not available (SNA)";
CM_ SG_ 523 TAS_staticHeightEstimateFR "Current static height estimate of the FR air spring.; raw 1023 = signal not available (SNA)";
CM_ SG_ 523 TAS_componentPressureFR "Current static pressure of the FR air spring.; raw 255 = signal not available (SNA)";
CM_ SG_ 523 TAS_rawHeightRL "Current height of the RL air spring.; raw 1023 = signal not available (SNA)";
CM_ SG_ 523 TAS_staticHeightEstimateRL "Current static height estimate of the RL air spring.; raw 1023 = signal not available (SNA)";
CM_ SG_ 523 TAS_componentPressureRL "Current static pressure of the RL air spring.; raw 255 = signal not available (SNA)";
CM_ SG_ 523 TAS_rawHeightRR "Current height of the RR air spring.; raw 1023 = signal not available (SNA)";
CM_ SG_ 523 TAS_staticHeightEstimateRR "Current static height estimate of the RR air spring.; raw 1023 = signal not available (SNA)";
CM_ SG_ 523 TAS_componentPressureRR "Current static pressure of the RR air spring.; raw 255 = signal not available (SNA)";
CM_ BO_ 1398 "Air suspension controller message: damping states";
CM_ SG_ 1398 TAS_endstopState "Air suspension controller: endstop state";
CM_ SG_ 1398 TAS_continuousControlState "SW-237496";
CM_ SG_ 1398 TAS_activeTireTune "Air suspension controller: active tire tune";
CM_ SG_ 1398 TAS_roughnessRaiseReason "Air suspension controller: roughness raise reason";
CM_ SG_ 1398 TAS_frontMetricDrivesRear "Air suspension controller: front metric drives rear";
CM_ SG_ 1398 TAS_roadCondition "Air suspension controller: road condition; raw 255 = signal not available (SNA)";
CM_ SG_ 1398 TAS_bellyProtect "Air suspension controller: belly protect";
CM_ SG_ 1398 TAS_frontMetricDrivesFront "Air suspension controller: front metric drives front";
CM_ SG_ 1398 TAS_speedBumpAxleFront "Air suspension controller: speed bump axle front";
CM_ SG_ 1398 TAS_speedBumpAxleRear "Air suspension controller: speed bump axle rear";
CM_ SG_ 1398 TAS_holeProtectFL "Air suspension controller: hole protect FL";
CM_ SG_ 1398 TAS_holeProtectFR "Air suspension controller: hole protect FR";
CM_ SG_ 1398 TAS_holeProtectRL "Air suspension controller: hole protect RL";
CM_ SG_ 1398 TAS_holeProtectRR "Air suspension controller: hole protect RR";
CM_ SG_ 1398 TAS_stepProtectFL "Air suspension controller: step protect FL";
CM_ SG_ 1398 TAS_stepProtectFR "Air suspension controller: step protect FR";
CM_ SG_ 1398 TAS_stepProtectRL "Air suspension controller: step protect RL";
CM_ SG_ 1398 TAS_stepProtectRR "Air suspension controller: step protect RR";
CM_ SG_ 1398 TAS_FDUTorqueCorruptionScale "Air suspension controller: FDU torque corruption scale; raw 15 = signal not available (SNA)";
CM_ SG_ 1398 TAS_sprungMassEstimate "Air suspension controller: sprung mass estimate; raw 31 = signal not available (SNA)";
CM_ SG_ 1398 TAS_anyDamperActive "Air suspension controller: any damper active";
CM_ SG_ 1398 TAS_dampingStatesCounter "Air suspension controller: damping states counter";
CM_ SG_ 1398 TAS_dampingStatesChecksum "Air suspension controller: damping states checksum";
CM_ BO_ 1357 "Air suspension controller message: info";
CM_ SG_ 1357 TAS_infoIndex "Air suspension controller: info index";
CM_ SG_ 1357 TAS_infoBuildType "Air suspension controller: info build type";
CM_ SG_ 1357 TAS_infoBuildConfigId "Air suspension controller: info build config id";
CM_ SG_ 1357 TAS_infoHardwareId "Air suspension controller: info hardware id";
CM_ SG_ 1357 TAS_infoComponentId "Air suspension controller: info component id";
CM_ SG_ 1357 TAS_infoPcbaId "Air suspension controller: info pcba id";
CM_ SG_ 1357 TAS_infoAssemblyId "Air suspension controller: info assembly id; raw 255 = signal not available (SNA)";
CM_ SG_ 1357 TAS_infoUsageId "Air suspension controller: info usage id";
CM_ SG_ 1357 TAS_infoSubUsageId "Air suspension controller: info sub usage id";
CM_ SG_ 1357 TAS_infoAppCrc "Air suspension controller: info app crc";
CM_ SG_ 1357 TAS_infoAppGitHash "Air suspension controller: info app git hash";
CM_ SG_ 1357 TAS_infoBootGitHash "Air suspension controller: info boot git hash";
CM_ SG_ 1357 TAS_infoPlatformType "Air suspension controller: info platform type";
CM_ SG_ 1357 TAS_infoMajorVersion "Air suspension controller: info major version; raw 255 = signal not available (SNA)";
CM_ SG_ 1357 TAS_infoBranchOrigin "Air suspension controller: info branch origin; raw 255 = signal not available (SNA)";
CM_ SG_ 1357 TAS_infoMaturity "Air suspension controller: info maturity; raw 255 = signal not available (SNA)";
CM_ SG_ 1357 TAS_infoHardwareRevision "Air suspension controller: info hardware revision; raw 255 = signal not available (SNA)";
CM_ BO_ 525 "Air suspension controller message: states";
CM_ SG_ 525 TAS_levelingState "Indicates air suspension leveling state.";
CM_ SG_ 525 TAS_levelingItem "Indicates the currently active air suspension components.";
CM_ SG_ 525 TAS_pressureGallery "Current air suspension valve block gallery pressure.; raw 255 = signal not available (SNA)";
CM_ SG_ 525 TAS_pressureReservoir "Indicates the latest valid reservoir pressure.; raw 255 = signal not available (SNA)";
CM_ SG_ 525 TAS_runMode "Indicates the status of run mode.";
CM_ SG_ 525 TAS_filterMode "Indicates the status of filter mode.";
CM_ SG_ 525 TAS_compressorRun "Either an indication that the compressor is running or a request to run the air compressor";
CM_ SG_ 525 TAS_twistDetected "TAS has detected large amount of twist.";
CM_ SG_ 525 TAS_leanDetected "TAS has detected vehicle to be leaning left or right.";
CM_ SG_ 525 TAS_limpHomeMode "Indicates which limp home mode is active.";
CM_ SG_ 525 TAS_targetLevel "Indicates target ride height.";
CM_ SG_ 525 TAS_currentLevel "Indicates current ride height.";
CM_ SG_ 525 TAS_jackMode "Indicates the status of Jack mode.";
CM_ SG_ 525 TAS_reduceVehicleSpeedRequest "Air suspension controller: reduce vehicle speed request";
CM_ SG_ 525 TAS_statesCounter "Air suspension controller: states counter";
CM_ SG_ 525 TAS_statesChecksum "Air suspension controller: states checksum";
CM_ BO_ 409 "Air suspension controller message: ui adaptive activity0";
CM_ SG_ 409 TAS_adaptiveActivityFL_C "Air suspension controller: adaptive activity FL c; raw 31 = signal not available (SNA)";
CM_ SG_ 409 TAS_adaptiveActivityFL_R "Air suspension controller: adaptive activity FL r; raw 31 = signal not available (SNA)";
CM_ SG_ 409 TAS_adaptiveActivityFR_C "Air suspension controller: adaptive activity FR c; raw 31 = signal not available (SNA)";
CM_ SG_ 409 TAS_adaptiveActivityFR_R "Air suspension controller: adaptive activity FR r; raw 31 = signal not available (SNA)";
CM_ SG_ 409 TAS_adaptiveActivityRL_C "Air suspension controller: adaptive activity RL c; raw 31 = signal not available (SNA)";
CM_ SG_ 409 TAS_adaptiveActivityRL_R "Air suspension controller: adaptive activity RL r; raw 31 = signal not available (SNA)";
CM_ SG_ 409 TAS_adaptiveActivityRR_C "Air suspension controller: adaptive activity RR c; raw 31 = signal not available (SNA)";
CM_ SG_ 409 TAS_adaptiveActivityRR_R "Air suspension controller: adaptive activity RR r; raw 31 = signal not available (SNA)";
CM_ SG_ 409 TAS_uiHeightFL "Air suspension controller: ui height FL; raw 63 = signal not available (SNA)";
CM_ SG_ 409 TAS_uiHeightFR "Air suspension controller: ui height FR; raw 63 = signal not available (SNA)";
CM_ SG_ 409 TAS_uiHeightRL "Air suspension controller: ui height RL; raw 63 = signal not available (SNA)";
CM_ SG_ 409 TAS_uiHeightRR "Air suspension controller: ui height RR; raw 63 = signal not available (SNA)";
CM_ BO_ 410 "Air suspension controller message: ui adaptive activity1";
CM_ SG_ 410 TAS_bodyAccelFL "Air suspension controller: body accel FL; raw 255 = signal not available (SNA)";
CM_ SG_ 410 TAS_bodyAccelFR "Air suspension controller: body accel FR; raw 255 = signal not available (SNA)";
CM_ SG_ 410 TAS_bodyAccelRL "Air suspension controller: body accel RL; raw 255 = signal not available (SNA)";
CM_ SG_ 410 TAS_bodyAccelRR "Air suspension controller: body accel RR; raw 255 = signal not available (SNA)";
CM_ BO_ 538 "Air suspension controller message: ui control";
CM_ SG_ 538 TAS_yellowWarningLamp "Air suspension controller: yellow warning lamp";
CM_ SG_ 538 TAS_redWarningLamp "Air suspension controller: red warning lamp";
CM_ SG_ 538 TAS_veryLowAllowed "Air suspension controller: very low allowed";
CM_ SG_ 538 TAS_lowAllowed "Air suspension controller: low allowed";
CM_ SG_ 538 TAS_standardAllowed "Air suspension controller: standard allowed";
CM_ SG_ 538 TAS_highAllowed "Air suspension controller: high allowed";
CM_ SG_ 538 TAS_veryHighAllowed "Air suspension controller: very high allowed";
CM_ SG_ 538 TAS_extractAllowed "Air suspension controller: extract allowed";
CM_ SG_ 538 TAS_showSpinner "Air suspension controller: show spinner";
CM_ SG_ 538 TAS_adaptiveRideModeOverride "Air suspension controller: adaptive ride mode override; raw 3 = signal not available (SNA)";
CM_ SG_ 538 TAS_levelSelectEnabled "Air suspension controller: level select enabled";
CM_ SG_ 538 TAS_jackModeToggleEnabled "Air suspension controller: jack mode toggle enabled";
CM_ SG_ 538 TAS_adaptiveRideSelectEnabled "Air suspension controller: adaptive ride select enabled";
CM_ SG_ 538 TAS_launchModeState "Air suspension controller: launch mode state";
CM_ SG_ 538 TAS_restrictUpLevelingFalcons "Air suspension controller: restrict up leveling falcons";
CM_ SG_ 538 TAS_restrictUpLevelingTrunk "Air suspension controller: restrict up leveling trunk";
CM_ SG_ 538 TAS_restrictDownLevelingDoors "Air suspension controller: restrict down leveling doors";
CM_ SG_ 538 TAS_restrictLevelingChargeCable "Air suspension controller: restrict leveling charge cable";
CM_ SG_ 538 TAS_restrictLevelingSystemCheck "Air suspension controller: restrict leveling system check";
CM_ SG_ 538 TAS_restrictLevelingTransport "Air suspension controller: restrict leveling transport";
CM_ SG_ 538 TAS_restrictLevelingShowroom "Indication that up and down leveling are restricted while showroom mode is active.";
CM_ SG_ 538 TAS_uiControlCounter "Air suspension controller: ui control counter";
CM_ SG_ 538 TAS_uiControlChecksum "Air suspension controller: ui control checksum";
CM_ BO_ 1410 "TCU ECU message: alert log";
CM_ SG_ 1410 TCU_alertID "TCU ECU: alert ID";
CM_ SG_ 1410 TCU_alertState "TCU ECU: alert state";
CM_ SG_ 1410 TCU_w001_FailCode "TCU ECU: w001 fail code";
CM_ SG_ 1410 TCU_w002_RejCause "TCU ECU: w002 rej cause";
CM_ SG_ 1410 TCU_w003_CallFailCode "TCU ECU: w003 call fail code";
CM_ SG_ 1410 TCU_w004_MSDFailCode "TCU ECU: w004 MSD fail code";
CM_ SG_ 1410 TCU_w006_Count "TCU ECU: w006 count";
CM_ BO_ 1472 "TCU ECU message: alert matrix1";
CM_ SG_ 1472 TCU_w001_IMSRegistrationFailed "TCU ECU: w001 IMS registration failed";
CM_ SG_ 1472 TCU_w002_CellRegRejected "TCU ECU: w002 cell reg rejected";
CM_ SG_ 1472 TCU_w003_ECallFailed "TCU ECU: w003 e call failed";
CM_ SG_ 1472 TCU_w004_MSDTransmissionFailed "TCU ECU: w004 MSD transmission failed";
CM_ SG_ 1472 TCU_w005_SIMSlotError "TCU ECU: w005 SIM slot error";
CM_ SG_ 1472 TCU_w006_MpssUnavailable "TCU ECU: w006 mpss unavailable";
CM_ BO_ 1409 "TCU ECU message: log";
CM_ SG_ 1409 TCU_logMux "TCU ECU: log mux";
CM_ SG_ 1409 TCU_cpuTemp "Indicates the current temperature reported by the Central Processing Unit (CPU) in the modem application processor";
CM_ SG_ 1409 TCU_cpuUsage "Indicates the current CPU usage in percentage reported by the modem application processor";
CM_ SG_ 1409 TCU_mdmCoreTemperature "Indicates the current Communication Processor (CP) temperature reported by the modem CP.";
CM_ SG_ 1409 TCU_availableMemory "Indicates the currently available Random Access Memory in the modem application processor";
CM_ SG_ 1409 TCU_pwm "Indicates the active Pulse Width Modulation (PWM) duty cycle applied to the modem fan.";
CM_ SG_ 1409 TCU_pwmcap "Indicates the active Pulse Width Modulation (PWM) duty cycle restriciton applied to the modem fan.";
CM_ SG_ 1409 TCU_totalResumes "Indicates the total amount of times the modem has been resumed";
CM_ SG_ 1409 TCU_mdmUplinkQueueSize "TCU ECU: mdm uplink queue size";
CM_ SG_ 1409 TCU_mdmRSRP "TCU ECU: mdm RSRP";
CM_ SG_ 1409 TCU_mdmSINR "TCU ECU: mdm SINR";
CM_ SG_ 1409 TCU_mdmUplinkAllowedRate "TCU ECU: mdm uplink allowed rate";
CM_ SG_ 1409 TCU_mdmUplinkAvgRage "TCU ECU: mdm uplink avg rage";
CM_ SG_ 1409 TCU_mdmServiceState "TCU ECU: mdm service state";
CM_ SG_ 1409 TCU_mdmIMSStatus "Indicates the current IP Multimedia System (IMS) registration state.";
CM_ SG_ 1409 TCU_mdmSIMStatus "TCU ECU: mdm SIM status";
CM_ SG_ 1409 TCU_mdmBusyActive "Reports whether the modem busy service is active on the modem application processor.; raw 4294967295 = signal not available (SNA)";
CM_ BO_ 1408 "TCU ECU message: status";
CM_ SG_ 1408 TCU_statusMux "TCU ECU: status mux";
CM_ SG_ 1408 TCU_wakeUpReason "TCU ECU: wake up reason; raw 4294967295 = signal not available (SNA)";
CM_ SG_ 1408 TCU_tcuCmdId "TCU ECU: tcu cmd id";
CM_ SG_ 1408 TCU_goingToSleep "TCU ECU: going to sleep; raw 4294967295 = signal not available (SNA)";
CM_ BO_ 879 "Tire pressure monitoring message: status c";
CM_ SG_ 879 TPMS_c_globalHardWarning "Tire pressure monitoring: c global hard warning";
CM_ SG_ 879 TPMS_c_globalSoftWarning "Tire pressure monitoring: c global soft warning";
CM_ SG_ 879 TPMS_systemMalfunction "Tire pressure monitoring: system malfunction";
CM_ SG_ 879 TPMS_WA_version "Tire pressure monitoring: WA version";
CM_ SG_ 879 TPMS_globalDeltaPressure "Tire pressure monitoring: global delta pressure";
CM_ SG_ 879 TPMS_newSensorLearnt "Tire pressure monitoring: new sensor learnt";
CM_ SG_ 879 TPMS_softWarningRR "Tire pressure monitoring: soft warning RR";
CM_ SG_ 879 TPMS_hardWarningRR "Tire pressure monitoring: hard warning RR";
CM_ SG_ 879 TPMS_softWarningRL "Tire pressure monitoring: soft warning RL";
CM_ SG_ 879 TPMS_hardWarningRL "Tire pressure monitoring: hard warning RL";
CM_ SG_ 879 TPMS_softWarningFR "Tire pressure monitoring: soft warning FR";
CM_ SG_ 879 TPMS_hardWarningFR "Tire pressure monitoring: hard warning FR";
CM_ SG_ 879 TPMS_softWarningFL "Tire pressure monitoring: soft warning FL";
CM_ SG_ 879 TPMS_hardWarningFL "Tire pressure monitoring: hard warning FL";
CM_ SG_ 879 TPMS_learningStatus "Monitors Tire Pressure Monitoring System (TPMS) Learn Status and evaluates issues.";
CM_ SG_ 879 TPMS_localisationStatus "Monitors Tire Pressure Monitoring System (TPMS) Localization Status and evaluates issues.";
CM_ SG_ 879 TPMS_deltaPressWarningFL "Tire pressure monitoring: delta press warning FL";
CM_ SG_ 879 TPMS_deltaPressWarningFR "Tire pressure monitoring: delta press warning FR";
CM_ SG_ 879 TPMS_deltaPressWarningRL "Tire pressure monitoring: delta press warning RL";
CM_ SG_ 879 TPMS_deltaPressWarningRR "Tire pressure monitoring: delta press warning RR";
CM_ SG_ 879 TPMS_sensorNoResponseFL "Count of times Front Left sensor did not respond to message";
CM_ SG_ 879 TPMS_sensorNoResponseFR "Count of times Front Right sensor did not respond to message";
CM_ SG_ 879 TPMS_sensorNoResponseRL "Count of times Rear Left sensor did not respond to message";
CM_ SG_ 879 TPMS_sensorNoResponseRR "Count of times Rear Right sensor did not respond to message";
CM_ SG_ 879 TPMS_sensorThermShutdownFL "Tire pressure monitoring: sensor therm shutdown FL";
CM_ SG_ 879 TPMS_sensorThermShutdownFR "Tire pressure monitoring: sensor therm shutdown FR";
CM_ SG_ 879 TPMS_sensorThermShutdownRL "Tire pressure monitoring: sensor therm shutdown RL";
CM_ SG_ 879 TPMS_sensorThermShutdownRR "Tire pressure monitoring: sensor therm shutdown RR";
CM_ SG_ 879 TPMS_sensorBatteryLowFL "Tracks near end of life sensor batteries in the fleet.";
CM_ SG_ 879 TPMS_sensorBatteryLowFR "Tracks near end of life sensor batteries in the fleet.";
CM_ SG_ 879 TPMS_sensorBatteryLowRL "Tracks near end of life sensor batteries in the fleet.";
CM_ SG_ 879 TPMS_sensorBatteryLowRR "Tracks near end of life sensor batteries in the fleet.";
CM_ SG_ 879 TPMS_sensorDefectiveFL "Tracks malfunctioning sensors in the fleet.";
CM_ SG_ 879 TPMS_sensorDefectiveFR "Tracks malfunctioning sensors in the fleet.";
CM_ SG_ 879 TPMS_sensorDefectiveRL "Tracks malfunctioning sensors in the fleet.";
CM_ SG_ 879 TPMS_sensorDefectiveRR "Tracks malfunctioning sensors in the fleet.";
CM_ SG_ 879 TPMS_ecuUnderVoltage "Tire pressure monitoring: ecu under voltage";
CM_ SG_ 879 TPMS_ecuOverVoltage "Tire pressure monitoring: ecu over voltage";
CM_ SG_ 879 TPMS_ecuRamRomNvMFail "Tire pressure monitoring: ecu ram rom nv m fail";
CM_ SG_ 879 TPMS_rfReceiverFail "Tire pressure monitoring: rf receiver fail";
CM_ SG_ 879 TPMS_wheelPulseMissing "Tire pressure monitoring: wheel pulse missing";
CM_ SG_ 879 TPMS_vehicleSpeedFail "Tire pressure monitoring: vehicle speed fail";
CM_ SG_ 879 TPMS_externalTemperatureFail "Tire pressure monitoring: external temperature fail";
CM_ SG_ 879 TPMS_eolNotCompleted "Monitors sensor completion of End of Line (EOL) routine.";
CM_ SG_ 879 TPMS_rcpFront "Front tire recommended cold pressure";
CM_ SG_ 879 TPMS_rcpRear "Rear tire recommended cold pressure";
CM_ BO_ 802 "Tire pressure monitoring message: data";
CM_ SG_ 802 TPMS_pressureFL "front left tire pressure; raw 255 = signal not available (SNA)";
CM_ SG_ 802 TPMS_temperatureFL "front left tire temperature; raw 255 = signal not available (SNA)";
CM_ SG_ 802 TPMS_pressureFR "front right tire pressure; raw 255 = signal not available (SNA)";
CM_ SG_ 802 TPMS_temperatureFR "front right tire temperature; raw 255 = signal not available (SNA)";
CM_ SG_ 802 TPMS_pressureRL "rear left tire pressure; raw 255 = signal not available (SNA)";
CM_ SG_ 802 TPMS_temperatureRL "rear left tire temperature; raw 255 = signal not available (SNA)";
CM_ SG_ 802 TPMS_pressureRR "rear right tire pressure; raw 255 = signal not available (SNA)";
CM_ SG_ 802 TPMS_temperatureRR "rear right tire temperature; raw 255 = signal not available (SNA)";
CM_ BO_ 1519 "Tire pressure monitoring message: info";
CM_ SG_ 1519 TPMS_infoIndex "Tire pressure monitoring: info index";
CM_ SG_ 1519 TPMS_infoComponentID "Tire pressure monitoring: info component ID";
CM_ SG_ 1519 TPMS_infoPcbaID "Tire pressure monitoring: info pcba ID";
CM_ SG_ 1519 TPMS_infoAssemblyID "Tire pressure monitoring: info assembly ID";
CM_ SG_ 1519 TPMS_infoUsageID "Tire pressure monitoring: info usage ID";
CM_ SG_ 1519 TPMS_infoApplicationCRC "Tire pressure monitoring: info application CRC";
CM_ SG_ 1519 TPMS_infoBootUdsProtoVersion "Tire pressure monitoring: info boot uds proto version";
CM_ SG_ 1519 TPMS_infoBootloaderCRC "Tire pressure monitoring: info bootloader CRC";
CM_ BO_ 1298 "TRCM ECU message: alert log";
CM_ SG_ 1298 TRCM_alertID "TRCM ECU: alert ID";
CM_ SG_ 1298 TRCM_alertState "TRCM ECU: alert state";
CM_ SG_ 1298 TRCM_a015_NVMMMemOverflow "TRCM ECU: a015 NVMM mem overflow";
CM_ SG_ 1298 TRCM_a015_NVMMFilesystemError "TRCM ECU: a015 NVMM filesystem error";
CM_ SG_ 1298 TRCM_a015_NVMMRecordIDError "TRCM ECU: a015 NVMM record ID error";
CM_ SG_ 1298 TRCM_a057_VEH_cpControl "TRCM ECU: a057 VEH cp control";
CM_ SG_ 1298 TRCM_a059_voltageDrop "TRCM ECU: a059 voltage drop";
CM_ SG_ 1298 TRCM_a059_resistanceEstimate "TRCM ECU: a059 resistance estimate";
CM_ SG_ 1298 TRCM_a059_current "TRCM ECU: a059 current";
CM_ SG_ 1298 TRCM_a063_switchChannel "TRCM ECU: a063 switch channel";
CM_ SG_ 1298 TRCM_a063_switchType "TRCM ECU: a063 switch type";
CM_ SG_ 1298 TRCM_a063_ADCVoltage "TRCM ECU: a063 ADC voltage";
CM_ SG_ 1298 TRCM_a063_disconnected "TRCM ECU: a063 disconnected";
CM_ SG_ 1298 TRCM_a063_indeterminate "TRCM ECU: a063 indeterminate";
CM_ SG_ 1298 TRCM_a063_stuckActive "TRCM ECU: a063 stuck active";
CM_ SG_ 1298 TRCM_a063_faulted "TRCM ECU: a063 faulted";
CM_ SG_ 1298 TRCM_a082_RIPC_epbPrivateState "TRCM ECU: a082 RIPC epb private state";
CM_ SG_ 1298 TRCM_a082_RIPC_remoteHSD "TRCM ECU: a082 RIPC remote HSD";
CM_ SG_ 1298 TRCM_a082_RIPC_railStatus "TRCM ECU: a082 RIPC rail status";
CM_ SG_ 1298 TRCM_a082_RIPC_remoteMux "TRCM ECU: a082 RIPC remote mux";
CM_ SG_ 1298 TRCM_a083_LIPC_epbPrivateState "TRCM ECU: a083 LIPC epb private state";
CM_ SG_ 1298 TRCM_a083_LIPC_remoteHSD "TRCM ECU: a083 LIPC remote HSD";
CM_ SG_ 1298 TRCM_a083_LIPC_railStatus "TRCM ECU: a083 LIPC rail status";
CM_ SG_ 1298 TRCM_a083_LIPC_HSDFaults "TRCM ECU: a083 LIPC HSD faults";
CM_ SG_ 1298 TRCM_a084_CH_StatusC "TRCM ECU: a084 CH status c";
CM_ SG_ 1298 TRCM_a085_PARTY_buttonStatus "TRCM ECU: a085 PARTY button status";
CM_ SG_ 1298 TRCM_a086_VEH_LVBMS_statusHigh "TRCM ECU: a086 VEH LVBMS status high";
CM_ SG_ 1298 TRCM_a086_VEH_LVBMS_statusLow "TRCM ECU: a086 VEH LVBMS status low";
CM_ SG_ 1298 TRCM_a086_VEH_status "TRCM ECU: a086 VEH status";
CM_ SG_ 1298 TRCM_a086_VEH_12VBatteryStatus "TRCM ECU: a086 VEH 12 v battery status";
CM_ SG_ 1298 TRCM_a086_VEH_LVPowerState "TRCM ECU: a086 VEH LV power state";
CM_ SG_ 1298 TRCM_a086_VEH_lightStatus "TRCM ECU: a086 VEH light status";
CM_ SG_ 1298 TRCM_a086_VEH_systemStatus "TRCM ECU: a086 VEH system status";
CM_ SG_ 1298 TRCM_a086_VEH_thermalStatus "TRCM ECU: a086 VEH thermal status";
CM_ SG_ 1298 TRCM_a086_VEH_vehNm "TRCM ECU: a086 VEH veh nm";
CM_ SG_ 1298 TRCM_a087_VEH_temperature "TRCM ECU: a087 VEH temperature";
CM_ SG_ 1298 TRCM_a087_VEH_thermalControl "TRCM ECU: a087 VEH thermal control";
CM_ SG_ 1298 TRCM_a087_VEH_torque "TRCM ECU: a087 VEH torque";
CM_ SG_ 1298 TRCM_a087_VEH_status "TRCM ECU: a087 VEH status";
CM_ SG_ 1298 TRCM_a087_PARTY_torque "TRCM ECU: a087 PARTY torque";
CM_ SG_ 1298 TRCM_a087_PARTY_status "TRCM ECU: a087 PARTY status";
CM_ SG_ 1298 TRCM_a087_PARTY_temperature "TRCM ECU: a087 PARTY temperature";
CM_ SG_ 1298 TRCM_a087_PARTY_thermalControl "TRCM ECU: a087 PARTY thermal control";
CM_ SG_ 1298 TRCM_a088_VEH_temperature "TRCM ECU: a088 VEH temperature";
CM_ SG_ 1298 TRCM_a088_VEH_thermalControl "TRCM ECU: a088 VEH thermal control";
CM_ SG_ 1298 TRCM_a088_VEH_torque "TRCM ECU: a088 VEH torque";
CM_ SG_ 1298 TRCM_a088_VEH_status "TRCM ECU: a088 VEH status";
CM_ SG_ 1298 TRCM_a088_PARTY_torque "TRCM ECU: a088 PARTY torque";
CM_ SG_ 1298 TRCM_a088_PARTY_status "TRCM ECU: a088 PARTY status";
CM_ SG_ 1298 TRCM_a088_PARTY_temperature "TRCM ECU: a088 PARTY temperature";
CM_ SG_ 1298 TRCM_a088_PARTY_thermalControl "TRCM ECU: a088 PARTY thermal control";
CM_ SG_ 1298 TRCM_a089_PARTY_party1 "TRCM ECU: a089 PARTY party1";
CM_ SG_ 1298 TRCM_a089_PARTY_status "TRCM ECU: a089 PARTY status";
CM_ SG_ 1298 TRCM_a089_VEH_status "TRCM ECU: a089 VEH status";
CM_ SG_ 1298 TRCM_a089_BDY_party1 "TRCM ECU: a089 BDY party1";
CM_ SG_ 1298 TRCM_a089_BDY_status "TRCM ECU: a089 BDY status";
CM_ SG_ 1298 TRCM_a089_CH_status "TRCM ECU: a089 CH status";
CM_ SG_ 1298 TRCM_a089_CH_party1 "TRCM ECU: a089 CH party1";
CM_ SG_ 1298 TRCM_a089_CH_party3 "TRCM ECU: a089 CH party3";
CM_ SG_ 1298 TRCM_a089_VEH_party1 "TRCM ECU: a089 VEH party1";
CM_ SG_ 1298 TRCM_a089_VEH_party3 "TRCM ECU: a089 VEH party3";
CM_ SG_ 1298 TRCM_a091_VEH_faultsAndExtras "TRCM ECU: a091 VEH faults and extras";
CM_ SG_ 1298 TRCM_a091_VEH_info "TRCM ECU: a091 VEH info";
CM_ SG_ 1298 TRCM_a091_VEH_state "TRCM ECU: a091 VEH state";
CM_ SG_ 1298 TRCM_a092_VEH_restraintStatus "TRCM ECU: a092 VEH restraint status";
CM_ SG_ 1298 TRCM_a092_VEH_switchStatus "TRCM ECU: a092 VEH switch status";
CM_ SG_ 1298 TRCM_a092_VEH_seatStatus2 "TRCM ECU: a092 VEH seat status2";
CM_ SG_ 1298 TRCM_a092_VEH_vehNm "TRCM ECU: a092 VEH veh nm";
CM_ SG_ 1298 TRCM_a093_VEH_restraintStatus "TRCM ECU: a093 VEH restraint status";
CM_ SG_ 1298 TRCM_a093_VEH_switchStatus "TRCM ECU: a093 VEH switch status";
CM_ SG_ 1298 TRCM_a093_VEH_seatStatus2 "TRCM ECU: a093 VEH seat status2";
CM_ SG_ 1298 TRCM_a093_VEH_vehNm "TRCM ECU: a093 VEH veh nm";
CM_ SG_ 1298 TRCM_a094_VEH_sysStatus "TRCM ECU: a094 VEH sys status";
CM_ SG_ 1298 TRCM_a094_PARTY_sysStatus "TRCM ECU: a094 PARTY sys status";
CM_ SG_ 1298 TRCM_a095_PT_ptNm "TRCM ECU: a095 PT pt nm";
CM_ SG_ 1298 TRCM_a095_PT_status "TRCM ECU: a095 PT status";
CM_ SG_ 1298 TRCM_a096_VEH_status "TRCM ECU: a096 VEH status";
CM_ SG_ 1298 TRCM_a096_CH_status "TRCM ECU: a096 CH status";
CM_ SG_ 1298 TRCM_a098_CH_torque "TRCM ECU: a098 CH torque";
CM_ SG_ 1298 TRCM_a098_VEH_hvStatus "TRCM ECU: a098 VEH hv status";
CM_ SG_ 1298 TRCM_a098_VEH_status "TRCM ECU: a098 VEH status";
CM_ SG_ 1298 TRCM_a098_VEH_thermalControl "TRCM ECU: a098 VEH thermal control";
CM_ SG_ 1298 TRCM_a098_VEH_temperature "TRCM ECU: a098 VEH temperature";
CM_ SG_ 1298 TRCM_a098_VEH_torque "TRCM ECU: a098 VEH torque";
CM_ SG_ 1298 TRCM_a098_PARTY_status "TRCM ECU: a098 PARTY status";
CM_ SG_ 1298 TRCM_a098_PARTY_temperature "TRCM ECU: a098 PARTY temperature";
CM_ SG_ 1298 TRCM_a098_PARTY_thermalControl "TRCM ECU: a098 PARTY thermal control";
CM_ SG_ 1298 TRCM_a098_PARTY_torque "TRCM ECU: a098 PARTY torque";
CM_ SG_ 1298 TRCM_a098_PT_thermalControl "TRCM ECU: a098 PT thermal control";
CM_ SG_ 1298 TRCM_a098_PT_temperature "TRCM ECU: a098 PT temperature";
CM_ SG_ 1298 TRCM_a099_VEH_oocStatus "TRCM ECU: a099 VEH ooc status";
CM_ SG_ 1298 TRCM_a100_VEH "TRCM ECU: a100 VEH";
CM_ SG_ 1298 TRCM_a100_PARTY "TRCM ECU: a100 PARTY";
CM_ SG_ 1298 TRCM_a100_PT "TRCM ECU: a100 PT";
CM_ SG_ 1298 TRCM_a100_CH "TRCM ECU: a100 CH";
CM_ SG_ 1298 TRCM_a100_OBD "TRCM ECU: a100 OBD";
CM_ SG_ 1298 TRCM_a101_VEH_state "TRCM ECU: a101 VEH state";
CM_ SG_ 1298 TRCM_a101_PARTY_locState "TRCM ECU: a101 PARTY loc state";
CM_ SG_ 1298 TRCM_a101_LIPC_externalWatchdogH "TRCM ECU: a101 LIPC external watchdog heart beat";
CM_ SG_ 1298 TRCM_a101_VEH_locState "TRCM ECU: a101 VEH loc state";
CM_ SG_ 1298 TRCM_a101_BDY_locState "TRCM ECU: a101 BDY loc state";
CM_ SG_ 1298 TRCM_a102_VEH_faultsAndExtras "TRCM ECU: a102 VEH faults and extras";
CM_ SG_ 1298 TRCM_a102_VEH_feedbackStatus "TRCM ECU: a102 VEH feedback status";
CM_ SG_ 1298 TRCM_a102_VEH_sensorStatus "TRCM ECU: a102 VEH sensor status";
CM_ SG_ 1298 TRCM_a102_VEH_rods "TRCM ECU: a102 VEH rods";
CM_ SG_ 1298 TRCM_a103_VEH_hvsNm "TRCM ECU: a103 VEH hvs nm";
CM_ SG_ 1298 TRCM_a103_VEH_vehNm "TRCM ECU: a103 VEH veh nm";
CM_ SG_ 1298 TRCM_a103_VEH_status "TRCM ECU: a103 VEH status";
CM_ SG_ 1298 TRCM_a103_PT_ptNm "TRCM ECU: a103 PT pt nm";
CM_ SG_ 1298 TRCM_a103_PT_status "TRCM ECU: a103 PT status";
CM_ SG_ 1298 TRCM_a103_VEH_evseStatus "TRCM ECU: a103 VEH evse status";
CM_ SG_ 1298 TRCM_a105_VEH_states "TRCM ECU: a105 VEH states";
CM_ SG_ 1298 TRCM_a105_VEH_chNm "TRCM ECU: a105 VEH ch nm";
CM_ SG_ 1298 TRCM_a105_VEH_dampingStates "TRCM ECU: a105 VEH damping states";
CM_ SG_ 1298 TRCM_a106_VEH_dcdcStatus "TRCM ECU: a106 VEH dcdc status";
CM_ SG_ 1298 TRCM_a106_VEH_thermalControl "TRCM ECU: a106 VEH thermal control";
CM_ SG_ 1298 TRCM_a106_VEH_thermalInterface "TRCM ECU: a106 VEH thermal interface";
CM_ SG_ 1298 TRCM_a106_VEH_dcdcRailStatus "TRCM ECU: a106 VEH dcdc rail status";
CM_ SG_ 1298 TRCM_a106_CH_dcdcRailStatus "TRCM ECU: a106 CH dcdc rail status";
CM_ SG_ 1298 TRCM_a106_CH_alertMatrix "TRCM ECU: a106 CH alert matrix";
CM_ SG_ 1298 TRCM_a107_VEH_hvsNm "TRCM ECU: a107 VEH hvs nm";
CM_ SG_ 1298 TRCM_a107_VEH_vehNm "TRCM ECU: a107 VEH veh nm";
CM_ SG_ 1298 TRCM_a107_VEH_status "TRCM ECU: a107 VEH status";
CM_ SG_ 1298 TRCM_a107_VEH_thermalStatus "TRCM ECU: a107 VEH thermal status";
CM_ SG_ 1298 TRCM_a107_VEH_thermalStatus2 "TRCM ECU: a107 VEH thermal status2";
CM_ SG_ 1298 TRCM_a107_VEH_bmbMinMax "TRCM ECU: a107 VEH bmb min max";
CM_ SG_ 1298 TRCM_a107_VEH_powerAvailable "TRCM ECU: a107 VEH power available";
CM_ SG_ 1298 TRCM_a107_PT_ptNm "TRCM ECU: a107 PT pt nm";
CM_ SG_ 1298 TRCM_a107_PT_status "TRCM ECU: a107 PT status";
CM_ SG_ 1298 TRCM_a107_PT_thermalStatus "TRCM ECU: a107 PT thermal status";
CM_ SG_ 1298 TRCM_a107_PT_socStatus "TRCM ECU: a107 PT soc status";
CM_ SG_ 1298 TRCM_a107_VEH_socStatus "TRCM ECU: a107 VEH soc status";
CM_ SG_ 1298 TRCM_a107_VEH_packConfig "TRCM ECU: a107 VEH pack config";
CM_ SG_ 1298 TRCM_a107_VEH_energyStatus "TRCM ECU: a107 VEH energy status";
CM_ SG_ 1298 TRCM_a107_VEH_chargeInfo "TRCM ECU: a107 VEH charge info";
CM_ SG_ 1298 TRCM_a108_VEH_hvStatus "TRCM ECU: a108 VEH hv status";
CM_ SG_ 1298 TRCM_a108_VEH_temperature "TRCM ECU: a108 VEH temperature";
CM_ SG_ 1298 TRCM_a108_VEH_thermalControl "TRCM ECU: a108 VEH thermal control";
CM_ SG_ 1298 TRCM_a108_VEH_torque "TRCM ECU: a108 VEH torque";
CM_ SG_ 1298 TRCM_a108_VEH_status "TRCM ECU: a108 VEH status";
CM_ SG_ 1298 TRCM_a108_PARTY_torque "TRCM ECU: a108 PARTY torque";
CM_ SG_ 1298 TRCM_a108_PARTY_status "TRCM ECU: a108 PARTY status";
CM_ SG_ 1298 TRCM_a108_PARTY_temperature "TRCM ECU: a108 PARTY temperature";
CM_ SG_ 1298 TRCM_a108_PARTY_thermalControl "TRCM ECU: a108 PARTY thermal control";
CM_ SG_ 1298 TRCM_a108_PT_temperature "TRCM ECU: a108 PT temperature";
CM_ SG_ 1298 TRCM_a108_PT_thermalControl "TRCM ECU: a108 PT thermal control";
CM_ SG_ 1298 TRCM_a109_PARTY_status "TRCM ECU: a109 PARTY status";
CM_ SG_ 1298 TRCM_a109_PARTY_inertial2 "TRCM ECU: a109 PARTY inertial2";
CM_ SG_ 1298 TRCM_a109_PARTY_nearDeploy "TRCM ECU: a109 PARTY near deploy";
CM_ SG_ 1298 TRCM_a109_PARTY_collision "TRCM ECU: a109 PARTY collision";
CM_ SG_ 1298 TRCM_a109_VEH_status "TRCM ECU: a109 VEH status";
CM_ SG_ 1298 TRCM_a109_VEH_imuOffsets "TRCM ECU: a109 VEH imu offsets";
CM_ SG_ 1298 TRCM_a109_PARTY_inertial1 "TRCM ECU: a109 PARTY inertial1";
CM_ SG_ 1298 TRCM_a109_BDY_imuOffsets "TRCM ECU: a109 BDY imu offsets";
CM_ SG_ 1298 TRCM_a109_BDY_inertial1 "TRCM ECU: a109 BDY inertial1";
CM_ SG_ 1298 TRCM_a109_BDY_inertial2 "TRCM ECU: a109 BDY inertial2";
CM_ SG_ 1298 TRCM_a109_BDY_status "TRCM ECU: a109 BDY status";
CM_ SG_ 1298 TRCM_a109_VEH_inertial1 "TRCM ECU: a109 VEH inertial1";
CM_ SG_ 1298 TRCM_a109_VEH_inertial2 "TRCM ECU: a109 VEH inertial2";
CM_ SG_ 1298 TRCM_a109_CH_inertial1 "TRCM ECU: a109 CH inertial1";
CM_ SG_ 1298 TRCM_a109_CH_inertial2 "TRCM ECU: a109 CH inertial2";
CM_ SG_ 1298 TRCM_a109_CH_status "TRCM ECU: a109 CH status";
CM_ SG_ 1298 TRCM_a110_VEH_carState "TRCM ECU: a110 VEH car state";
CM_ SG_ 1298 TRCM_a110_VEH_carConfig "TRCM ECU: a110 VEH car config";
CM_ SG_ 1298 TRCM_a110_VEH_time "TRCM ECU: a110 VEH time";
CM_ SG_ 1298 TRCM_a110_VEH_updateStatus "TRCM ECU: a110 VEH update status";
CM_ SG_ 1298 TRCM_a110_VEH_vehNm "TRCM ECU: a110 VEH veh nm";
CM_ SG_ 1298 TRCM_a110_VEH_mismatchFault "TRCM ECU: a110 VEH mismatch fault";
CM_ SG_ 1298 TRCM_a110_VEH_vin "TRCM ECU: a110 VEH vin";
CM_ SG_ 1298 TRCM_a110_VEH_bmpDebug "TRCM ECU: a110 VEH bmp debug";
CM_ SG_ 1298 TRCM_a110_VEH_gearControl "TRCM ECU: a110 VEH gear control";
CM_ SG_ 1298 TRCM_a110_VEH_canLogAvailability "TRCM ECU: a110 VEH can log availability";
CM_ SG_ 1298 TRCM_a110_CH_airbagCutoffStatus "TRCM ECU: a110 CH airbag cutoff status";
CM_ SG_ 1298 TRCM_a110_CH_carConfig "TRCM ECU: a110 CH car config";
CM_ SG_ 1298 TRCM_a110_CH_carState "TRCM ECU: a110 CH car state";
CM_ SG_ 1298 TRCM_a110_CH_vin "TRCM ECU: a110 CH vin";
CM_ SG_ 1298 TRCM_a110_CH_chNm "TRCM ECU: a110 CH ch nm";
CM_ SG_ 1298 TRCM_a110_CH_epochTimeGtw "TRCM ECU: a110 CH epoch time gtw";
CM_ SG_ 1298 TRCM_a111_VEH_internalStatus "TRCM ECU: a111 VEH internal status";
CM_ SG_ 1298 TRCM_a111_VEH_status "TRCM ECU: a111 VEH status";
CM_ SG_ 1298 TRCM_a111_VEH_vehNm "TRCM ECU: a111 VEH veh nm";
CM_ SG_ 1298 TRCM_a111_RIPC_LVPowerState "TRCM ECU: a111 RIPC LV power state";
CM_ SG_ 1298 TRCM_a111_RIPC_epbPrivateState "TRCM ECU: a111 RIPC epb private state";
CM_ SG_ 1298 TRCM_a111_RIPC_railStatus "TRCM ECU: a111 RIPC rail status";
CM_ SG_ 1298 TRCM_a111_RIPC_remoteADC "TRCM ECU: a111 RIPC remote ADC";
CM_ SG_ 1298 TRCM_a111_RIPC_switchStatus "TRCM ECU: a111 RIPC switch status";
CM_ SG_ 1298 TRCM_a111_VEH_LVPowerState "TRCM ECU: a111 VEH LV power state";
CM_ SG_ 1298 TRCM_a111_VEH_seatStatus "TRCM ECU: a111 VEH seat status";
CM_ SG_ 1298 TRCM_a111_PARTY_status "TRCM ECU: a111 PARTY status";
CM_ SG_ 1298 TRCM_a111_CH_status "TRCM ECU: a111 CH status";
CM_ SG_ 1298 TRCM_a112_VEH_internalStatus "TRCM ECU: a112 VEH internal status";
CM_ SG_ 1298 TRCM_a112_VEH_status "TRCM ECU: a112 VEH status";
CM_ SG_ 1298 TRCM_a112_VEH_vehNm "TRCM ECU: a112 VEH veh nm";
CM_ SG_ 1298 TRCM_a112_LIPC_LVPowerState "TRCM ECU: a112 LIPC LV power state";
CM_ SG_ 1298 TRCM_a112_LIPC_epbPrivateState "TRCM ECU: a112 LIPC epb private state";
CM_ SG_ 1298 TRCM_a112_LIPC_railStatus "TRCM ECU: a112 LIPC rail status";
CM_ SG_ 1298 TRCM_a112_LIPC_remoteADC "TRCM ECU: a112 LIPC remote ADC";
CM_ SG_ 1298 TRCM_a112_LIPC_switchStatus "TRCM ECU: a112 LIPC switch status";
CM_ SG_ 1298 TRCM_a112_VEH_LVPowerState "TRCM ECU: a112 VEH LV power state";
CM_ SG_ 1298 TRCM_a112_PARTY_status "TRCM ECU: a112 PARTY status";
CM_ SG_ 1298 TRCM_a112_CH_status "TRCM ECU: a112 CH status";
CM_ SG_ 1298 TRCM_a114_PARTY_status "TRCM ECU: a114 PARTY status";
CM_ SG_ 1298 TRCM_a114_PARTY_wheelSpeeds "TRCM ECU: a114 PARTY wheel speeds";
CM_ SG_ 1298 TRCM_a114_VEH_wheelSpeeds "TRCM ECU: a114 VEH wheel speeds";
CM_ SG_ 1298 TRCM_a114_CH_wheelSpeeds "TRCM ECU: a114 CH wheel speeds";
CM_ SG_ 1298 TRCM_a114_PARTY_party3 "TRCM ECU: a114 PARTY party3";
CM_ SG_ 1298 TRCM_a114_VEH_party3 "TRCM ECU: a114 VEH party3";
CM_ SG_ 1298 TRCM_a114_VEH_status "TRCM ECU: a114 VEH status";
CM_ SG_ 1298 TRCM_a114_PARTY_wheelRotation "TRCM ECU: a114 PARTY wheel rotation";
CM_ SG_ 1298 TRCM_a114_CH_wheelRotation "TRCM ECU: a114 CH wheel rotation";
CM_ SG_ 1298 TRCM_a114_VEH_wheelRotation "TRCM ECU: a114 VEH wheel rotation";
CM_ SG_ 1298 TRCM_a114_PARTY_brakeTorque "TRCM ECU: a114 PARTY brake torque";
CM_ SG_ 1298 TRCM_a114_PARTY_offsets "TRCM ECU: a114 PARTY offsets";
CM_ SG_ 1298 TRCM_a114_BDY_offsets "TRCM ECU: a114 BDY offsets";
CM_ SG_ 1298 TRCM_a114_BDY_party3 "TRCM ECU: a114 BDY party3";
CM_ SG_ 1298 TRCM_a114_BDY_status "TRCM ECU: a114 BDY status";
CM_ SG_ 1298 TRCM_a114_BDY_wheelRotation "TRCM ECU: a114 BDY wheel rotation";
CM_ SG_ 1298 TRCM_a114_BDY_wheelSpeeds "TRCM ECU: a114 BDY wheel speeds";
CM_ SG_ 1298 TRCM_a114_CH_party1 "TRCM ECU: a114 CH party1";
CM_ SG_ 1298 TRCM_a114_CH_party3 "TRCM ECU: a114 CH party3";
CM_ SG_ 1298 TRCM_a114_CH_status "TRCM ECU: a114 CH status";
CM_ SG_ 1298 TRCM_a115_VEH_vehNm "TRCM ECU: a115 VEH veh nm";
CM_ SG_ 1298 TRCM_a115_VEH_authentication "TRCM ECU: a115 VEH authentication";
CM_ SG_ 1298 TRCM_a115_VEH_BLEResetRequest "TRCM ECU: a115 VEH BLE reset request";
CM_ SG_ 1298 TRCM_a115_VEH_requests "TRCM ECU: a115 VEH requests";
CM_ SG_ 1298 TRCM_a115_VEH_requests2 "TRCM ECU: a115 VEH requests2";
CM_ SG_ 1298 TRCM_a115_REM_authentication "TRCM ECU: a115 REM authentication";
CM_ SG_ 1298 TRCM_a115_UI_corianderVehicleCon "TRCM ECU: a115 UI coriander vehicle control";
CM_ SG_ 1298 TRCM_a115_CH_TPMSDisplay "TRCM ECU: a115 CH TPMS display";
CM_ SG_ 1298 TRCM_a116_PARTY_epbmStatus "TRCM ECU: a116 PARTY epbm status";
CM_ SG_ 1298 TRCM_a116_VEH_vehNm "TRCM ECU: a116 VEH veh nm";
CM_ SG_ 1298 TRCM_a116_VEH_hvacRequest "TRCM ECU: a116 VEH hvac request";
CM_ SG_ 1298 TRCM_a116_VEH_hvacStatus "TRCM ECU: a116 VEH hvac status";
CM_ SG_ 1298 TRCM_a116_VEH_LVPowerState "TRCM ECU: a116 VEH LV power state";
CM_ SG_ 1298 TRCM_a116_VEH_lightStatus "TRCM ECU: a116 VEH light status";
CM_ SG_ 1298 TRCM_a116_VEH_seatStatus "TRCM ECU: a116 VEH seat status";
CM_ SG_ 1298 TRCM_a116_VEH_thsStatus "TRCM ECU: a116 VEH ths status";
CM_ SG_ 1298 TRCM_a116_VEH_doorStatus "TRCM ECU: a116 VEH door status";
CM_ SG_ 1298 TRCM_a116_VEH_seatHeatStatus "TRCM ECU: a116 VEH seat heat status";
CM_ SG_ 1298 TRCM_a116_VEH_restraintStatus "TRCM ECU: a116 VEH restraint status";
CM_ SG_ 1298 TRCM_a116_VEH_switchStatus "TRCM ECU: a116 VEH switch status";
CM_ SG_ 1298 TRCM_a116_VEH_logging1Hz "TRCM ECU: a116 VEH logging1 hz";
CM_ SG_ 1298 TRCM_a116_VEH_seatStatus2 "TRCM ECU: a116 VEH seat status2";
CM_ SG_ 1298 TRCM_a116_VEH_status "TRCM ECU: a116 VEH status";
CM_ SG_ 1298 TRCM_a116_VEH_thermalCommand "TRCM ECU: a116 VEH thermal command";
CM_ SG_ 1298 TRCM_a116_VEH_windowStatus "TRCM ECU: a116 VEH window status";
CM_ SG_ 1298 TRCM_a116_PARTY_restraintStatus "TRCM ECU: a116 PARTY restraint status";
CM_ SG_ 1298 TRCM_a116_PARTY_doorStatus "TRCM ECU: a116 PARTY door status";
CM_ SG_ 1298 TRCM_a116_BDY_epbmStatus "TRCM ECU: a116 BDY epbm status";
CM_ SG_ 1298 TRCM_a116_BDY_restraintStatus "TRCM ECU: a116 BDY restraint status";
CM_ SG_ 1298 TRCM_a117_BDY_epbmStatus "TRCM ECU: a117 BDY epbm status";
CM_ SG_ 1298 TRCM_a117_BDY_restraintStatus "TRCM ECU: a117 BDY restraint status";
CM_ SG_ 1298 TRCM_a117_VEH_prndStatus "TRCM ECU: a117 VEH prnd status";
CM_ SG_ 1298 TRCM_a117_PARTY_epbmStatus "TRCM ECU: a117 PARTY epbm status";
CM_ SG_ 1298 TRCM_a117_VEH_vehNm "TRCM ECU: a117 VEH veh nm";
CM_ SG_ 1298 TRCM_a117_VEH_hvacBlowerFdb "TRCM ECU: a117 VEH hvac blower fdb";
CM_ SG_ 1298 TRCM_a117_VEH_LVPowerState "TRCM ECU: a117 VEH LV power state";
CM_ SG_ 1298 TRCM_a117_VEH_restraintStatus "TRCM ECU: a117 VEH restraint status";
CM_ SG_ 1298 TRCM_a117_VEH_lightStatus "TRCM ECU: a117 VEH light status";
CM_ SG_ 1298 TRCM_a117_VEH_seatStatus "TRCM ECU: a117 VEH seat status";
CM_ SG_ 1298 TRCM_a117_BDY_falconSwitchStatus "TRCM ECU: a117 BDY falcon switch status";
CM_ SG_ 1298 TRCM_a117_VEH_doorStatus "TRCM ECU: a117 VEH door status";
CM_ SG_ 1298 TRCM_a117_VEH_doorStatus2 "TRCM ECU: a117 VEH door status2";
CM_ SG_ 1298 TRCM_a117_VEH_windowStatus "TRCM ECU: a117 VEH window status";
CM_ SG_ 1298 TRCM_a117_VEH_switchStatus "TRCM ECU: a117 VEH switch status";
CM_ SG_ 1298 TRCM_a117_VEH_intrusionSensorSta "TRCM ECU: a117 VEH intrusion sensor status";
CM_ SG_ 1298 TRCM_a117_VEH_liftgateStatus "TRCM ECU: a117 VEH liftgate status";
CM_ SG_ 1298 TRCM_a117_VEH_seatStatus2 "TRCM ECU: a117 VEH seat status2";
CM_ SG_ 1298 TRCM_a117_PARTY_restraintStatus "TRCM ECU: a117 PARTY restraint status";
CM_ SG_ 1298 TRCM_a117_VEH_thermalStatus "TRCM ECU: a117 VEH thermal status";
CM_ SG_ 1298 TRCM_a117_PARTY_doorStatus "TRCM ECU: a117 PARTY door status";
CM_ SG_ 1298 TRCM_a117_VEH_status "TRCM ECU: a117 VEH status";
CM_ SG_ 1298 TRCM_a117_PARTY_prndStatus "TRCM ECU: a117 PARTY prnd status";
CM_ SG_ 1298 TRCM_a118_VEH_vehNm "TRCM ECU: a118 VEH veh nm";
CM_ SG_ 1298 TRCM_a118_VEH_lighting "TRCM ECU: a118 VEH lighting";
CM_ SG_ 1298 TRCM_a118_VEH_sensors "TRCM ECU: a118 VEH sensors";
CM_ SG_ 1298 TRCM_a118_VEH_status "TRCM ECU: a118 VEH status";
CM_ SG_ 1298 TRCM_a118_VEH_okToUseHighPwr "TRCM ECU: a118 VEH ok to use high pwr";
CM_ SG_ 1298 TRCM_a118_VEH_LVPowerState "TRCM ECU: a118 VEH LV power state";
CM_ SG_ 1298 TRCM_a118_VEH_coolant "TRCM ECU: a118 VEH coolant";
CM_ SG_ 1298 TRCM_a118_VEH_vehicleStatus "TRCM ECU: a118 VEH vehicle status";
CM_ SG_ 1298 TRCM_a118_VEH_12VBatteryStatus "TRCM ECU: a118 VEH 12 v battery status";
CM_ SG_ 1298 TRCM_a118_VEH_systemStatus "TRCM ECU: a118 VEH system status";
CM_ SG_ 1298 TRCM_a118_PARTY_LVPowerState "TRCM ECU: a118 PARTY LV power state";
CM_ SG_ 1298 TRCM_a118_PARTY_outputPowerStatu "TRCM ECU: a118 PARTY output power status";
CM_ SG_ 1298 TRCM_a118_PARTY_vehicleTime "TRCM ECU: a118 PARTY vehicle time";
CM_ SG_ 1298 TRCM_a118_VEH_thermalCommand "TRCM ECU: a118 VEH thermal command";
CM_ SG_ 1298 TRCM_a118_CH_LVPowerState "TRCM ECU: a118 CH LV power state";
CM_ SG_ 1298 TRCM_a118_PARTY_sensors "TRCM ECU: a118 PARTY sensors";
CM_ SG_ 1298 TRCM_a118_CH_sensors "TRCM ECU: a118 CH sensors";
CM_ SG_ 1298 TRCM_a118_VEH_interNodeResistanc "TRCM ECU: a118 VEH inter node resistance";
CM_ SG_ 1298 TRCM_a118_CH_lighting "TRCM ECU: a118 CH lighting";
CM_ SG_ 1298 TRCM_a118_VEH_lightStatus "TRCM ECU: a118 VEH light status";
CM_ SG_ 1298 TRCM_a118_PARTY_vehNm "TRCM ECU: a118 PARTY veh nm";
CM_ SG_ 1298 TRCM_a118_CH_12VBatteryStatus "TRCM ECU: a118 CH 12 v battery status";
CM_ SG_ 1298 TRCM_a118_CH_LVBMS_statusHigh "TRCM ECU: a118 CH LVBMS status high";
CM_ SG_ 1298 TRCM_a118_CH_alertMatrix "TRCM ECU: a118 CH alert matrix";
CM_ SG_ 1298 TRCM_a118_BDY_outputPowerStatus "TRCM ECU: a118 BDY output power status";
CM_ SG_ 1298 TRCM_a118_BDY_vehicleTime "TRCM ECU: a118 BDY vehicle time";
CM_ SG_ 1298 TRCM_a118_PARTY_AP_vehicleState1 "TRCM ECU: a118 PARTY AP vehicle state1 hz muxed";
CM_ SG_ 1298 TRCM_a118_BDY_AP_vehicleState1Hz "TRCM ECU: a118 BDY AP vehicle state1 hz muxed";
CM_ SG_ 1298 TRCM_a119_VEH_steerAngle "TRCM ECU: a119 VEH steer angle";
CM_ SG_ 1298 TRCM_a119_VEH_leftStalk "TRCM ECU: a119 VEH left stalk";
CM_ SG_ 1298 TRCM_a119_VEH_rightStalk "TRCM ECU: a119 VEH right stalk";
CM_ SG_ 1298 TRCM_a119_PARTY_rightStalk "TRCM ECU: a119 PARTY right stalk";
CM_ SG_ 1298 TRCM_a119_CH_steerAngle "TRCM ECU: a119 CH steer angle";
CM_ SG_ 1298 TRCM_a119_PARTY_steerAngle "TRCM ECU: a119 PARTY steer angle";
CM_ SG_ 1298 TRCM_a120_PARTY_chassisCntl "TRCM ECU: a120 PARTY chassis cntl";
CM_ SG_ 1298 TRCM_a120_VEH_systemStatus "TRCM ECU: a120 VEH system status";
CM_ SG_ 1298 TRCM_a120_CH_chassisCntl "TRCM ECU: a120 CH chassis cntl";
CM_ SG_ 1298 TRCM_a120_PARTY_systemStatus "TRCM ECU: a120 PARTY system status";
CM_ SG_ 1298 TRCM_a120_PARTY_torque "TRCM ECU: a120 PARTY torque";
CM_ SG_ 1298 TRCM_a120_VEH_torque "TRCM ECU: a120 VEH torque";
CM_ SG_ 1298 TRCM_a120_PARTY_locStatus "TRCM ECU: a120 PARTY loc status";
CM_ SG_ 1298 TRCM_a120_PARTY_speed "TRCM ECU: a120 PARTY speed";
CM_ SG_ 1298 TRCM_a120_VEH_speed "TRCM ECU: a120 VEH speed";
CM_ SG_ 1298 TRCM_a120_PARTY_status "TRCM ECU: a120 PARTY status";
CM_ SG_ 1298 TRCM_a120_PT_speed "TRCM ECU: a120 PT speed";
CM_ SG_ 1298 TRCM_a120_PT_systemStatus "TRCM ECU: a120 PT system status";
CM_ SG_ 1298 TRCM_a120_PARTY_vehicleEstimates "TRCM ECU: a120 PARTY vehicle estimates";
CM_ SG_ 1298 TRCM_a120_VEH_aggregatedAxleSpee "TRCM ECU: a120 VEH aggregated axle speed";
CM_ SG_ 1298 TRCM_a120_PARTY_aggregatedAxleSp "TRCM ECU: a120 PARTY aggregated axle speed";
CM_ SG_ 1298 TRCM_a120_VEH_systemPower "TRCM ECU: a120 VEH system power";
CM_ SG_ 1298 TRCM_a120_PT_systemPower "TRCM ECU: a120 PT system power";
CM_ SG_ 1298 TRCM_a120_PARTY_stalklessInterfa "TRCM ECU: a120 PARTY stalkless interfaces";
CM_ SG_ 1298 TRCM_a120_CH_speed "TRCM ECU: a120 CH speed";
CM_ SG_ 1298 TRCM_a120_VEH_estimatedBrakeTemp "TRCM ECU: a120 VEH estimated brake temp";
CM_ SG_ 1298 TRCM_a120_PARTY_prndControl "TRCM ECU: a120 PARTY prnd control";
CM_ SG_ 1298 TRCM_a120_PARTY_locStatus2 "TRCM ECU: a120 PARTY loc status2";
CM_ SG_ 1298 TRCM_a120_VEH_chassisCntl "TRCM ECU: a120 VEH chassis cntl";
CM_ SG_ 1298 TRCM_a120_VEH_locStatus "TRCM ECU: a120 VEH loc status";
CM_ SG_ 1298 TRCM_a120_VEH_locStatus2 "TRCM ECU: a120 VEH loc status2";
CM_ SG_ 1298 TRCM_a120_VEH_prndControl "TRCM ECU: a120 VEH prnd control";
CM_ SG_ 1298 TRCM_a120_VEH_vehicleEstimates "TRCM ECU: a120 VEH vehicle estimates";
BA_DEF_ BO_ "GenMsgCycleTime" INT 0 3600000;
BA_DEF_ BO_ "GenMsgSendType" ENUM "Cyclic","NotUsed","NotUsed","NotUsed","NotUsed","NotUsed","NotUsed","IfActive","NoMsgSendType","NotUsed";
BA_DEF_ BO_ "VFrameFormat" ENUM "StandardCAN","ExtendedCAN","reserved","J1939PG","reserved","reserved","reserved","reserved","reserved","reserved","reserved","reserved","reserved","reserved","StandardCAN_FD","ExtendedCAN_FD";
BA_DEF_ BO_ "CANFD_BRS" ENUM "0","1";
BA_DEF_ SG_ "GenSigSNA" STRING;
BA_DEF_ SG_ "SystemSignalLongSymbol" STRING;
BA_DEF_ SG_ "Confidence" ENUM "validated","plausible","layout-only","contradicted";
BA_DEF_DEF_ "GenMsgCycleTime" 0;
BA_DEF_DEF_ "GenMsgSendType" "NoMsgSendType";
BA_DEF_DEF_ "VFrameFormat" "StandardCAN";
BA_DEF_DEF_ "CANFD_BRS" "1";
BA_DEF_DEF_ "GenSigSNA" "";
BA_DEF_DEF_ "SystemSignalLongSymbol" "";
BA_DEF_DEF_ "Confidence" "layout-only";
BA_ "GenMsgCycleTime" BO_ 852 100;
BA_ "GenMsgSendType" BO_ 852 0;
BA_ "GenMsgCycleTime" BO_ 523 20;
BA_ "GenMsgSendType" BO_ 523 0;
BA_ "GenMsgCycleTime" BO_ 1398 100;
BA_ "GenMsgSendType" BO_ 1398 0;
BA_ "GenMsgCycleTime" BO_ 1357 1000;
BA_ "GenMsgSendType" BO_ 1357 0;
BA_ "GenMsgCycleTime" BO_ 525 100;
BA_ "GenMsgSendType" BO_ 525 0;
BA_ "GenMsgCycleTime" BO_ 409 50;
BA_ "GenMsgSendType" BO_ 409 0;
BA_ "GenMsgCycleTime" BO_ 410 50;
BA_ "GenMsgSendType" BO_ 410 0;
BA_ "GenMsgCycleTime" BO_ 538 100;
BA_ "GenMsgSendType" BO_ 538 0;
BA_ "GenMsgCycleTime" BO_ 1472 1000;
BA_ "GenMsgSendType" BO_ 1472 0;
BA_ "GenMsgCycleTime" BO_ 1409 1000;
BA_ "GenMsgSendType" BO_ 1409 0;
BA_ "GenMsgCycleTime" BO_ 1408 1000;
BA_ "GenMsgSendType" BO_ 1408 0;
BA_ "GenMsgCycleTime" BO_ 879 1000;
BA_ "GenMsgSendType" BO_ 879 0;
BA_ "GenMsgCycleTime" BO_ 802 1000;
BA_ "GenMsgSendType" BO_ 802 0;
BA_ "GenMsgCycleTime" BO_ 1519 1000;
BA_ "GenMsgSendType" BO_ 1519 0;
BA_ "Confidence" SG_ 852 TAS_matrixIndex 1;
BA_ "SystemSignalLongSymbol" SG_ 852 TAS_a066_undefinedInstructionAbo "TAS_a066_undefinedInstructionAbort";
BA_ "SystemSignalLongSymbol" SG_ 852 TAS_a150_accelAvgImplausible_FL_ "TAS_a150_accelAvgImplausible_FL_X";
BA_ "SystemSignalLongSymbol" SG_ 852 TAS_a151_accelAvgImplausible_FL_ "TAS_a151_accelAvgImplausible_FL_Y";
BA_ "SystemSignalLongSymbol" SG_ 852 TAS_a152_accelAvgImplausible_FL_ "TAS_a152_accelAvgImplausible_FL_Z";
BA_ "SystemSignalLongSymbol" SG_ 852 TAS_a153_accelAvgImplausible_FR_ "TAS_a153_accelAvgImplausible_FR_X";
BA_ "SystemSignalLongSymbol" SG_ 852 TAS_a154_accelAvgImplausible_FR_ "TAS_a154_accelAvgImplausible_FR_Y";
BA_ "SystemSignalLongSymbol" SG_ 852 TAS_a155_accelAvgImplausible_FR_ "TAS_a155_accelAvgImplausible_FR_Z";
BA_ "SystemSignalLongSymbol" SG_ 852 TAS_a156_accelAvgImplausible_RL_ "TAS_a156_accelAvgImplausible_RL_X";
BA_ "SystemSignalLongSymbol" SG_ 852 TAS_a157_accelAvgImplausible_RL_ "TAS_a157_accelAvgImplausible_RL_Y";
BA_ "SystemSignalLongSymbol" SG_ 852 TAS_a158_accelAvgImplausible_RL_ "TAS_a158_accelAvgImplausible_RL_Z";
BA_ "SystemSignalLongSymbol" SG_ 852 TAS_a159_accelAvgImplausible_RR_ "TAS_a159_accelAvgImplausible_RR_X";
BA_ "SystemSignalLongSymbol" SG_ 852 TAS_a160_accelAvgImplausible_RR_ "TAS_a160_accelAvgImplausible_RR_Y";
BA_ "SystemSignalLongSymbol" SG_ 852 TAS_a161_accelAvgImplausible_RR_ "TAS_a161_accelAvgImplausible_RR_Z";
BA_ "SystemSignalLongSymbol" SG_ 852 TAS_a192_rideHeightObserverDiver "TAS_a192_rideHeightObserverDivergence";
BA_ "SystemSignalLongSymbol" SG_ 852 TAS_a197_invalidAdaptiveModeRequ "TAS_a197_invalidAdaptiveModeRequested";
BA_ "Confidence" SG_ 523 TAS_axleIndex 1;
BA_ "Confidence" SG_ 523 TAS_rawHeightFL 0;
BA_ "GenSigSNA" SG_ 523 TAS_rawHeightFL "1023";
BA_ "Confidence" SG_ 523 TAS_staticHeightEstimateFL 0;
BA_ "GenSigSNA" SG_ 523 TAS_staticHeightEstimateFL "1023";
BA_ "Confidence" SG_ 523 TAS_componentPressureFL 0;
BA_ "GenSigSNA" SG_ 523 TAS_componentPressureFL "255";
BA_ "Confidence" SG_ 523 TAS_rawHeightFR 0;
BA_ "GenSigSNA" SG_ 523 TAS_rawHeightFR "1023";
BA_ "Confidence" SG_ 523 TAS_staticHeightEstimateFR 0;
BA_ "GenSigSNA" SG_ 523 TAS_staticHeightEstimateFR "1023";
BA_ "Confidence" SG_ 523 TAS_componentPressureFR 0;
BA_ "GenSigSNA" SG_ 523 TAS_componentPressureFR "255";
BA_ "Confidence" SG_ 523 TAS_rawHeightRL 0;
BA_ "GenSigSNA" SG_ 523 TAS_rawHeightRL "1023";
BA_ "Confidence" SG_ 523 TAS_staticHeightEstimateRL 0;
BA_ "GenSigSNA" SG_ 523 TAS_staticHeightEstimateRL "1023";
BA_ "Confidence" SG_ 523 TAS_componentPressureRL 0;
BA_ "GenSigSNA" SG_ 523 TAS_componentPressureRL "255";
BA_ "Confidence" SG_ 523 TAS_rawHeightRR 0;
BA_ "GenSigSNA" SG_ 523 TAS_rawHeightRR "1023";
BA_ "Confidence" SG_ 523 TAS_staticHeightEstimateRR 0;
BA_ "GenSigSNA" SG_ 523 TAS_staticHeightEstimateRR "1023";
BA_ "Confidence" SG_ 523 TAS_componentPressureRR 0;
BA_ "GenSigSNA" SG_ 523 TAS_componentPressureRR "255";
BA_ "Confidence" SG_ 1398 TAS_endstopState 0;
BA_ "Confidence" SG_ 1398 TAS_continuousControlState 0;
BA_ "Confidence" SG_ 1398 TAS_activeTireTune 0;
BA_ "Confidence" SG_ 1398 TAS_roughnessRaiseReason 0;
BA_ "Confidence" SG_ 1398 TAS_frontMetricDrivesRear 0;
BA_ "Confidence" SG_ 1398 TAS_roadCondition 0;
BA_ "GenSigSNA" SG_ 1398 TAS_roadCondition "255";
BA_ "Confidence" SG_ 1398 TAS_bellyProtect 0;
BA_ "Confidence" SG_ 1398 TAS_frontMetricDrivesFront 0;
BA_ "Confidence" SG_ 1398 TAS_speedBumpAxleFront 0;
BA_ "Confidence" SG_ 1398 TAS_speedBumpAxleRear 0;
BA_ "Confidence" SG_ 1398 TAS_holeProtectFL 0;
BA_ "Confidence" SG_ 1398 TAS_holeProtectFR 0;
BA_ "Confidence" SG_ 1398 TAS_holeProtectRL 0;
BA_ "Confidence" SG_ 1398 TAS_holeProtectRR 0;
BA_ "Confidence" SG_ 1398 TAS_stepProtectFL 0;
BA_ "Confidence" SG_ 1398 TAS_stepProtectFR 0;
BA_ "Confidence" SG_ 1398 TAS_stepProtectRL 0;
BA_ "Confidence" SG_ 1398 TAS_stepProtectRR 0;
BA_ "Confidence" SG_ 1398 TAS_FDUTorqueCorruptionScale 0;
BA_ "GenSigSNA" SG_ 1398 TAS_FDUTorqueCorruptionScale "15";
BA_ "Confidence" SG_ 1398 TAS_sprungMassEstimate 0;
BA_ "GenSigSNA" SG_ 1398 TAS_sprungMassEstimate "31";
BA_ "Confidence" SG_ 1398 TAS_anyDamperActive 0;
BA_ "Confidence" SG_ 1398 TAS_dampingStatesCounter 0;
BA_ "Confidence" SG_ 1398 TAS_dampingStatesChecksum 0;
BA_ "Confidence" SG_ 1357 TAS_infoIndex 1;
BA_ "Confidence" SG_ 1357 TAS_infoBuildType 0;
BA_ "Confidence" SG_ 1357 TAS_infoBuildConfigId 0;
BA_ "Confidence" SG_ 1357 TAS_infoHardwareId 0;
BA_ "Confidence" SG_ 1357 TAS_infoComponentId 0;
BA_ "Confidence" SG_ 1357 TAS_infoPcbaId 0;
BA_ "Confidence" SG_ 1357 TAS_infoAssemblyId 0;
BA_ "GenSigSNA" SG_ 1357 TAS_infoAssemblyId "255";
BA_ "Confidence" SG_ 1357 TAS_infoUsageId 0;
BA_ "Confidence" SG_ 1357 TAS_infoSubUsageId 0;
BA_ "Confidence" SG_ 1357 TAS_infoAppCrc 0;
BA_ "Confidence" SG_ 1357 TAS_infoAppGitHash 0;
BA_ "Confidence" SG_ 1357 TAS_infoBootGitHash 0;
BA_ "Confidence" SG_ 1357 TAS_infoPlatformType 0;
BA_ "Confidence" SG_ 1357 TAS_infoMajorVersion 0;
BA_ "GenSigSNA" SG_ 1357 TAS_infoMajorVersion "255";
BA_ "Confidence" SG_ 1357 TAS_infoBranchOrigin 0;
BA_ "GenSigSNA" SG_ 1357 TAS_infoBranchOrigin "255";
BA_ "Confidence" SG_ 1357 TAS_infoMaturity 0;
BA_ "GenSigSNA" SG_ 1357 TAS_infoMaturity "255";
BA_ "Confidence" SG_ 1357 TAS_infoHardwareRevision 0;
BA_ "GenSigSNA" SG_ 1357 TAS_infoHardwareRevision "255";
BA_ "Confidence" SG_ 525 TAS_levelingState 0;
BA_ "Confidence" SG_ 525 TAS_levelingItem 0;
BA_ "Confidence" SG_ 525 TAS_pressureGallery 0;
BA_ "GenSigSNA" SG_ 525 TAS_pressureGallery "255";
BA_ "Confidence" SG_ 525 TAS_pressureReservoir 0;
BA_ "GenSigSNA" SG_ 525 TAS_pressureReservoir "255";
BA_ "Confidence" SG_ 525 TAS_runMode 0;
BA_ "Confidence" SG_ 525 TAS_filterMode 0;
BA_ "Confidence" SG_ 525 TAS_compressorRun 0;
BA_ "Confidence" SG_ 525 TAS_twistDetected 0;
BA_ "Confidence" SG_ 525 TAS_leanDetected 0;
BA_ "Confidence" SG_ 525 TAS_limpHomeMode 0;
BA_ "Confidence" SG_ 525 TAS_targetLevel 0;
BA_ "Confidence" SG_ 525 TAS_currentLevel 0;
BA_ "Confidence" SG_ 525 TAS_jackMode 0;
BA_ "Confidence" SG_ 525 TAS_reduceVehicleSpeedRequest 0;
BA_ "Confidence" SG_ 525 TAS_statesCounter 0;
BA_ "Confidence" SG_ 525 TAS_statesChecksum 0;
BA_ "Confidence" SG_ 409 TAS_adaptiveActivityFL_C 0;
BA_ "GenSigSNA" SG_ 409 TAS_adaptiveActivityFL_C "31";
BA_ "Confidence" SG_ 409 TAS_adaptiveActivityFL_R 0;
BA_ "GenSigSNA" SG_ 409 TAS_adaptiveActivityFL_R "31";
BA_ "Confidence" SG_ 409 TAS_adaptiveActivityFR_C 0;
BA_ "GenSigSNA" SG_ 409 TAS_adaptiveActivityFR_C "31";
BA_ "Confidence" SG_ 409 TAS_adaptiveActivityFR_R 0;
BA_ "GenSigSNA" SG_ 409 TAS_adaptiveActivityFR_R "31";
BA_ "Confidence" SG_ 409 TAS_adaptiveActivityRL_C 0;
BA_ "GenSigSNA" SG_ 409 TAS_adaptiveActivityRL_C "31";
BA_ "Confidence" SG_ 409 TAS_adaptiveActivityRL_R 0;
BA_ "GenSigSNA" SG_ 409 TAS_adaptiveActivityRL_R "31";
BA_ "Confidence" SG_ 409 TAS_adaptiveActivityRR_C 0;
BA_ "GenSigSNA" SG_ 409 TAS_adaptiveActivityRR_C "31";
BA_ "Confidence" SG_ 409 TAS_adaptiveActivityRR_R 0;
BA_ "GenSigSNA" SG_ 409 TAS_adaptiveActivityRR_R "31";
BA_ "Confidence" SG_ 409 TAS_uiHeightFL 0;
BA_ "GenSigSNA" SG_ 409 TAS_uiHeightFL "63";
BA_ "Confidence" SG_ 409 TAS_uiHeightFR 0;
BA_ "GenSigSNA" SG_ 409 TAS_uiHeightFR "63";
BA_ "Confidence" SG_ 409 TAS_uiHeightRL 0;
BA_ "GenSigSNA" SG_ 409 TAS_uiHeightRL "63";
BA_ "Confidence" SG_ 409 TAS_uiHeightRR 0;
BA_ "GenSigSNA" SG_ 409 TAS_uiHeightRR "63";
BA_ "Confidence" SG_ 410 TAS_bodyAccelFL 0;
BA_ "GenSigSNA" SG_ 410 TAS_bodyAccelFL "255";
BA_ "Confidence" SG_ 410 TAS_bodyAccelFR 0;
BA_ "GenSigSNA" SG_ 410 TAS_bodyAccelFR "255";
BA_ "Confidence" SG_ 410 TAS_bodyAccelRL 0;
BA_ "GenSigSNA" SG_ 410 TAS_bodyAccelRL "255";
BA_ "Confidence" SG_ 410 TAS_bodyAccelRR 0;
BA_ "GenSigSNA" SG_ 410 TAS_bodyAccelRR "255";
BA_ "Confidence" SG_ 538 TAS_yellowWarningLamp 0;
BA_ "Confidence" SG_ 538 TAS_redWarningLamp 0;
BA_ "Confidence" SG_ 538 TAS_veryLowAllowed 0;
BA_ "Confidence" SG_ 538 TAS_lowAllowed 0;
BA_ "Confidence" SG_ 538 TAS_standardAllowed 0;
BA_ "Confidence" SG_ 538 TAS_highAllowed 0;
BA_ "Confidence" SG_ 538 TAS_veryHighAllowed 0;
BA_ "Confidence" SG_ 538 TAS_extractAllowed 0;
BA_ "Confidence" SG_ 538 TAS_showSpinner 0;
BA_ "Confidence" SG_ 538 TAS_adaptiveRideModeOverride 0;
BA_ "GenSigSNA" SG_ 538 TAS_adaptiveRideModeOverride "3";
BA_ "Confidence" SG_ 538 TAS_levelSelectEnabled 0;
BA_ "Confidence" SG_ 538 TAS_jackModeToggleEnabled 0;
BA_ "Confidence" SG_ 538 TAS_adaptiveRideSelectEnabled 0;
BA_ "Confidence" SG_ 538 TAS_launchModeState 0;
BA_ "Confidence" SG_ 538 TAS_restrictUpLevelingFalcons 0;
BA_ "Confidence" SG_ 538 TAS_restrictUpLevelingTrunk 0;
BA_ "Confidence" SG_ 538 TAS_restrictDownLevelingDoors 0;
BA_ "Confidence" SG_ 538 TAS_restrictLevelingChargeCable 0;
BA_ "Confidence" SG_ 538 TAS_restrictLevelingSystemCheck 0;
BA_ "Confidence" SG_ 538 TAS_restrictLevelingTransport 0;
BA_ "Confidence" SG_ 538 TAS_restrictLevelingShowroom 0;
BA_ "Confidence" SG_ 538 TAS_uiControlCounter 0;
BA_ "Confidence" SG_ 538 TAS_uiControlChecksum 0;
BA_ "Confidence" SG_ 1410 TCU_alertID 1;
BA_ "Confidence" SG_ 1410 TCU_alertState 1;
BA_ "Confidence" SG_ 1409 TCU_logMux 1;
BA_ "Confidence" SG_ 1409 TCU_cpuTemp 0;
BA_ "Confidence" SG_ 1409 TCU_cpuUsage 0;
BA_ "Confidence" SG_ 1409 TCU_mdmCoreTemperature 0;
BA_ "Confidence" SG_ 1409 TCU_availableMemory 0;
BA_ "Confidence" SG_ 1409 TCU_pwm 0;
BA_ "Confidence" SG_ 1409 TCU_pwmcap 0;
BA_ "Confidence" SG_ 1409 TCU_totalResumes 0;
BA_ "Confidence" SG_ 1409 TCU_mdmUplinkQueueSize 0;
BA_ "Confidence" SG_ 1409 TCU_mdmRSRP 0;
BA_ "Confidence" SG_ 1409 TCU_mdmSINR 0;
BA_ "Confidence" SG_ 1409 TCU_mdmUplinkAllowedRate 0;
BA_ "Confidence" SG_ 1409 TCU_mdmServiceState 0;
BA_ "Confidence" SG_ 1409 TCU_mdmIMSStatus 0;
BA_ "Confidence" SG_ 1409 TCU_mdmSIMStatus 0;
BA_ "Confidence" SG_ 1409 TCU_mdmBusyActive 0;
BA_ "GenSigSNA" SG_ 1409 TCU_mdmBusyActive "4294967295";
BA_ "Confidence" SG_ 1408 TCU_statusMux 1;
BA_ "Confidence" SG_ 1408 TCU_wakeUpReason 1;
BA_ "GenSigSNA" SG_ 1408 TCU_wakeUpReason "4294967295";
BA_ "Confidence" SG_ 1408 TCU_goingToSleep 1;
BA_ "GenSigSNA" SG_ 1408 TCU_goingToSleep "4294967295";
BA_ "Confidence" SG_ 879 TPMS_c_globalHardWarning 0;
BA_ "Confidence" SG_ 879 TPMS_c_globalSoftWarning 0;
BA_ "Confidence" SG_ 879 TPMS_systemMalfunction 0;
BA_ "Confidence" SG_ 879 TPMS_WA_version 0;
BA_ "Confidence" SG_ 879 TPMS_globalDeltaPressure 0;
BA_ "Confidence" SG_ 879 TPMS_newSensorLearnt 0;
BA_ "Confidence" SG_ 879 TPMS_softWarningRR 0;
BA_ "Confidence" SG_ 879 TPMS_hardWarningRR 0;
BA_ "Confidence" SG_ 879 TPMS_softWarningRL 0;
BA_ "Confidence" SG_ 879 TPMS_hardWarningRL 0;
BA_ "Confidence" SG_ 879 TPMS_softWarningFR 0;
BA_ "Confidence" SG_ 879 TPMS_hardWarningFR 0;
BA_ "Confidence" SG_ 879 TPMS_softWarningFL 0;
BA_ "Confidence" SG_ 879 TPMS_hardWarningFL 0;
BA_ "Confidence" SG_ 879 TPMS_learningStatus 0;
BA_ "Confidence" SG_ 879 TPMS_localisationStatus 0;
BA_ "Confidence" SG_ 879 TPMS_deltaPressWarningFL 0;
BA_ "Confidence" SG_ 879 TPMS_deltaPressWarningFR 0;
BA_ "Confidence" SG_ 879 TPMS_deltaPressWarningRL 0;
BA_ "Confidence" SG_ 879 TPMS_deltaPressWarningRR 0;
BA_ "Confidence" SG_ 879 TPMS_sensorNoResponseFL 0;
BA_ "Confidence" SG_ 879 TPMS_sensorNoResponseFR 0;
BA_ "Confidence" SG_ 879 TPMS_sensorNoResponseRL 0;
BA_ "Confidence" SG_ 879 TPMS_sensorNoResponseRR 0;
BA_ "Confidence" SG_ 879 TPMS_sensorThermShutdownFL 0;
BA_ "Confidence" SG_ 879 TPMS_sensorThermShutdownFR 0;
BA_ "Confidence" SG_ 879 TPMS_sensorThermShutdownRL 0;
BA_ "Confidence" SG_ 879 TPMS_sensorThermShutdownRR 0;
BA_ "Confidence" SG_ 879 TPMS_sensorBatteryLowFL 0;
BA_ "Confidence" SG_ 879 TPMS_sensorBatteryLowFR 0;
BA_ "Confidence" SG_ 879 TPMS_sensorBatteryLowRL 0;
BA_ "Confidence" SG_ 879 TPMS_sensorBatteryLowRR 0;
BA_ "Confidence" SG_ 879 TPMS_sensorDefectiveFL 0;
BA_ "Confidence" SG_ 879 TPMS_sensorDefectiveFR 0;
BA_ "Confidence" SG_ 879 TPMS_sensorDefectiveRL 0;
BA_ "Confidence" SG_ 879 TPMS_sensorDefectiveRR 0;
BA_ "Confidence" SG_ 879 TPMS_ecuUnderVoltage 0;
BA_ "Confidence" SG_ 879 TPMS_ecuOverVoltage 0;
BA_ "Confidence" SG_ 879 TPMS_ecuRamRomNvMFail 0;
BA_ "Confidence" SG_ 879 TPMS_rfReceiverFail 0;
BA_ "Confidence" SG_ 879 TPMS_wheelPulseMissing 0;
BA_ "Confidence" SG_ 879 TPMS_vehicleSpeedFail 0;
BA_ "Confidence" SG_ 879 TPMS_externalTemperatureFail 0;
BA_ "Confidence" SG_ 879 TPMS_eolNotCompleted 0;
BA_ "Confidence" SG_ 879 TPMS_rcpFront 0;
BA_ "Confidence" SG_ 879 TPMS_rcpRear 0;
BA_ "Confidence" SG_ 802 TPMS_pressureFL 0;
BA_ "GenSigSNA" SG_ 802 TPMS_pressureFL "255";
BA_ "Confidence" SG_ 802 TPMS_temperatureFL 0;
BA_ "GenSigSNA" SG_ 802 TPMS_temperatureFL "255";
BA_ "Confidence" SG_ 802 TPMS_pressureFR 0;
BA_ "GenSigSNA" SG_ 802 TPMS_pressureFR "255";
BA_ "Confidence" SG_ 802 TPMS_temperatureFR 0;
BA_ "GenSigSNA" SG_ 802 TPMS_temperatureFR "255";
BA_ "Confidence" SG_ 802 TPMS_pressureRL 0;
BA_ "GenSigSNA" SG_ 802 TPMS_pressureRL "255";
BA_ "Confidence" SG_ 802 TPMS_temperatureRL 0;
BA_ "GenSigSNA" SG_ 802 TPMS_temperatureRL "255";
BA_ "Confidence" SG_ 802 TPMS_pressureRR 0;
BA_ "GenSigSNA" SG_ 802 TPMS_pressureRR "255";
BA_ "Confidence" SG_ 802 TPMS_temperatureRR 0;
BA_ "GenSigSNA" SG_ 802 TPMS_temperatureRR "255";
BA_ "Confidence" SG_ 1519 TPMS_infoIndex 1;
BA_ "Confidence" SG_ 1519 TPMS_infoComponentID 0;
BA_ "Confidence" SG_ 1519 TPMS_infoPcbaID 0;
BA_ "Confidence" SG_ 1519 TPMS_infoAssemblyID 0;
BA_ "Confidence" SG_ 1519 TPMS_infoUsageID 0;
BA_ "Confidence" SG_ 1519 TPMS_infoApplicationCRC 0;
BA_ "Confidence" SG_ 1519 TPMS_infoBootUdsProtoVersion 0;
BA_ "Confidence" SG_ 1519 TPMS_infoBootloaderCRC 0;
BA_ "Confidence" SG_ 1298 TRCM_alertID 1;
BA_ "Confidence" SG_ 1298 TRCM_alertState 1;
BA_ "Confidence" SG_ 1298 TRCM_a059_voltageDrop 1;
BA_ "Confidence" SG_ 1298 TRCM_a059_resistanceEstimate 1;
BA_ "Confidence" SG_ 1298 TRCM_a059_current 1;
BA_ "Confidence" SG_ 1298 TRCM_a063_ADCVoltage 1;
BA_ "SystemSignalLongSymbol" SG_ 1298 TRCM_a101_LIPC_externalWatchdogH "TRCM_a101_LIPC_externalWatchdogHeartBeat";
BA_ "SystemSignalLongSymbol" SG_ 1298 TRCM_a115_UI_corianderVehicleCon "TRCM_a115_UI_corianderVehicleControl";
BA_ "SystemSignalLongSymbol" SG_ 1298 TRCM_a117_VEH_intrusionSensorSta "TRCM_a117_VEH_intrusionSensorStatus";
BA_ "SystemSignalLongSymbol" SG_ 1298 TRCM_a118_PARTY_outputPowerStatu "TRCM_a118_PARTY_outputPowerStatus";
BA_ "SystemSignalLongSymbol" SG_ 1298 TRCM_a118_VEH_interNodeResistanc "TRCM_a118_VEH_interNodeResistance";
BA_ "SystemSignalLongSymbol" SG_ 1298 TRCM_a118_PARTY_AP_vehicleState1 "TRCM_a118_PARTY_AP_vehicleState1HzMuxed";
BA_ "SystemSignalLongSymbol" SG_ 1298 TRCM_a118_BDY_AP_vehicleState1Hz "TRCM_a118_BDY_AP_vehicleState1HzMuxed";
BA_ "SystemSignalLongSymbol" SG_ 1298 TRCM_a120_VEH_aggregatedAxleSpee "TRCM_a120_VEH_aggregatedAxleSpeed";
BA_ "SystemSignalLongSymbol" SG_ 1298 TRCM_a120_PARTY_aggregatedAxleSp "TRCM_a120_PARTY_aggregatedAxleSpeed";
BA_ "SystemSignalLongSymbol" SG_ 1298 TRCM_a120_PARTY_stalklessInterfa "TRCM_a120_PARTY_stalklessInterfaces";
VAL_ 852 TAS_matrixIndex 5 "AlertMatrix5" 4 "AlertMatrix4" 3 "AlertMatrix3" 2 "AlertMatrix2" 1 "AlertMatrix1" 0 "AlertMatrix0" ;
VAL_ 523 TAS_axleIndex 1 "axleRear" 0 "axleFront" ;
VAL_ 523 TAS_rawHeightFL 1023 "SNA" ;
VAL_ 523 TAS_staticHeightEstimateFL 1023 "SNA" ;
VAL_ 523 TAS_componentPressureFL 255 "SNA" ;
VAL_ 523 TAS_rawHeightFR 1023 "SNA" ;
VAL_ 523 TAS_staticHeightEstimateFR 1023 "SNA" ;
VAL_ 523 TAS_componentPressureFR 255 "SNA" ;
VAL_ 523 TAS_rawHeightRL 1023 "SNA" ;
VAL_ 523 TAS_staticHeightEstimateRL 1023 "SNA" ;
VAL_ 523 TAS_componentPressureRL 255 "SNA" ;
VAL_ 523 TAS_rawHeightRR 1023 "SNA" ;
VAL_ 523 TAS_staticHeightEstimateRR 1023 "SNA" ;
VAL_ 523 TAS_componentPressureRR 255 "SNA" ;
VAL_ 1398 TAS_endstopState 1 "TAS_DAMPING_STATE_ACTIVE" 0 "TAS_DAMPING_STATE_STANDBY" ;
VAL_ 1398 TAS_continuousControlState 1 "TAS_DAMPING_STATE_ACTIVE" 0 "TAS_DAMPING_STATE_STANDBY" ;
VAL_ 1398 TAS_activeTireTune 1 "TAS_TIRE_TUNE_MICHELIN_SUMMER_21" 0 "TAS_TIRE_TUNE_DEFAULT" ;
VAL_ 1398 TAS_roughnessRaiseReason 2 "TAS_ROUGHNESS_RAISE_REASON_LOOKAHEAD" 1 "TAS_ROUGHNESS_RAISE_REASON_LEGACY" 0 "TAS_ROUGHNESS_RAISE_REASON_NONE" ;
VAL_ 1398 TAS_frontMetricDrivesRear 3 "TAS_ACTION_ACTIVE" 2 "TAS_ACTION_ARMED" 1 "TAS_ACTION_STANDBY" 0 "TAS_ACTION_DISABLED" ;
VAL_ 1398 TAS_roadCondition 255 "SNA" ;
VAL_ 1398 TAS_bellyProtect 3 "TAS_ACTION_ACTIVE" 2 "TAS_ACTION_ARMED" 1 "TAS_ACTION_STANDBY" 0 "TAS_ACTION_DISABLED" ;
VAL_ 1398 TAS_frontMetricDrivesFront 3 "TAS_ACTION_ACTIVE" 2 "TAS_ACTION_ARMED" 1 "TAS_ACTION_STANDBY" 0 "TAS_ACTION_DISABLED" ;
VAL_ 1398 TAS_speedBumpAxleFront 4 "TAS_ACTION_CANCELED" 3 "TAS_ACTION_ACTIVE" 2 "TAS_ACTION_ARMED" 1 "TAS_ACTION_STANDBY" 0 "TAS_ACTION_DISABLED" ;
VAL_ 1398 TAS_speedBumpAxleRear 4 "TAS_ACTION_CANCELED" 3 "TAS_ACTION_ACTIVE" 2 "TAS_ACTION_ARMED" 1 "TAS_ACTION_STANDBY" 0 "TAS_ACTION_DISABLED" ;
VAL_ 1398 TAS_holeProtectFL 3 "TAS_ACTION_ACTIVE" 2 "TAS_ACTION_ARMED" 1 "TAS_ACTION_STANDBY" 0 "TAS_ACTION_DISABLED" ;
VAL_ 1398 TAS_holeProtectFR 3 "TAS_ACTION_ACTIVE" 2 "TAS_ACTION_ARMED" 1 "TAS_ACTION_STANDBY" 0 "TAS_ACTION_DISABLED" ;
VAL_ 1398 TAS_holeProtectRL 3 "TAS_ACTION_ACTIVE" 2 "TAS_ACTION_ARMED" 1 "TAS_ACTION_STANDBY" 0 "TAS_ACTION_DISABLED" ;
VAL_ 1398 TAS_holeProtectRR 3 "TAS_ACTION_ACTIVE" 2 "TAS_ACTION_ARMED" 1 "TAS_ACTION_STANDBY" 0 "TAS_ACTION_DISABLED" ;
VAL_ 1398 TAS_stepProtectFL 3 "TAS_ACTION_ACTIVE" 2 "TAS_ACTION_ARMED" 1 "TAS_ACTION_STANDBY" 0 "TAS_ACTION_DISABLED" ;
VAL_ 1398 TAS_stepProtectFR 3 "TAS_ACTION_ACTIVE" 2 "TAS_ACTION_ARMED" 1 "TAS_ACTION_STANDBY" 0 "TAS_ACTION_DISABLED" ;
VAL_ 1398 TAS_stepProtectRL 3 "TAS_ACTION_ACTIVE" 2 "TAS_ACTION_ARMED" 1 "TAS_ACTION_STANDBY" 0 "TAS_ACTION_DISABLED" ;
VAL_ 1398 TAS_stepProtectRR 3 "TAS_ACTION_ACTIVE" 2 "TAS_ACTION_ARMED" 1 "TAS_ACTION_STANDBY" 0 "TAS_ACTION_DISABLED" ;
VAL_ 1398 TAS_FDUTorqueCorruptionScale 15 "SNA" ;
VAL_ 1398 TAS_sprungMassEstimate 31 "SNA" ;
VAL_ 1357 TAS_infoIndex 255 "END" 41 "SUBCOMPONENT14" 40 "SUBCOMPONENT13" 39 "SUBCOMPONENT12" 38 "SUBCOMPONENT11" 37 "SUBCOMPONENT10" 36 "SUBCOMPONENT9" 35 "SUBCOMPONENT8" 34 "SUBCOMPONENT7" 33 "SUBCOMPONENT6" 32 "SUBCOMPONENT5" 31 "SUBCOMPONENT4" 24 "SUBCOMPONENT3" 23 "SUBCOMPONENT2" 20 "UDS_PROTOCOL_BOOTCRC" 19 "VERSION_DEPRECATED" 18 "BOOTLOADER_GITHASH" 17 "APP_GITHASH" 16 "SUBCOMPONENT1" 15 "BOOTLOADER_CRC" 14 "BOOTLOADER_SVN" 13 "APP_CRC" 11 "PCBAID_ASSYID_USAGEID" 10 "BUILD_HWID_COMPONENTID" 9 "DEPRECATED_9" 8 "DEPRECATED_8" 7 "DEPRECATED_7" 6 "DEPRECATED_6" 5 "DEPRECATED_5" 4 "DEPRECATED_4" 3 "DEPRECATED_3" 2 "DEPRECATED_2" 1 "DEPRECATED_1" 0 "DEPRECATED_0" ;
VAL_ 1357 TAS_infoBuildType 4 "INFO_MFG_BUILD" 3 "INFO_TRACEABLE_CI_BUILD" 2 "INFO_LOCAL_BUILD" 1 "INFO_PLATFORM_BUILD" 0 "INFO_UNKNOWN_BUILD" ;
VAL_ 1357 TAS_infoAssemblyId 255 "ASSEMBLY_SNA" 1 "ASSEMBLY1" ;
VAL_ 1357 TAS_infoMajorVersion 255 "SNA" 254 "LOCAL_BUILD" ;
VAL_ 1357 TAS_infoBranchOrigin 255 "SNA" 254 "LOCAL_BUILD" ;
VAL_ 1357 TAS_infoMaturity 255 "SNA" 254 "LOCAL_BUILD" ;
VAL_ 1357 TAS_infoHardwareRevision 255 "SNA" 254 "LOCAL_BUILD" ;
VAL_ 525 TAS_levelingState 15 "LEVELING_STATE_CROSSLINK" 14 "LEVELING_STATE_QUIET_EXHAUST" 13 "LEVELING_STATE_EXHAUST_RESERVOIR" 12 "LEVELING_STATE_LOWER_SPRING_WITH_COMPRESSOR" 11 "LEVELING_STATE_LOWER_SPRING" 10 "LEVELING_STATE_FILL_SPRING_RESERVOIR_FROM_COMPRESSOR" 9 "LEVELING_STATE_FILL_SPRING_FROM_RESERVOIR" 8 "LEVELING_STATE_FILL_SPRING_FROM_BOOST" 7 "LEVELING_STATE_FILL_SPRING_FROM_COMPRESSOR" 6 "LEVELING_STATE_FILL_RESERVOIR_FROM_COMPRESSOR" 5 "LEVELING_STATE_COMPRESSOR_PREFILL_GALLERY" 4 "LEVELING_STATE_COMPRESSOR_RAMPUP" 3 "LEVELING_STATE_EXHAUST_GALLERY" 2 "LEVELING_STATE_MEASURE_SPRING_PRESSURE" 1 "LEVELING_STATE_READ_P_RESERVOIR" 0 "LEVELING_STATE_IDLE" ;
VAL_ 525 TAS_levelingItem 7 "TAS_LEVELING_ITEM_ALL" 6 "TAS_LEVELING_ITEM_REAR_AXLE" 5 "TAS_LEVELING_ITEM_FRONT_AXLE" 4 "TAS_LEVELING_ITEM_RR" 3 "TAS_LEVELING_ITEM_RL" 2 "TAS_LEVELING_ITEM_FR" 1 "TAS_LEVELING_ITEM_FL" 0 "TAS_LEVELING_ITEM_NONE" ;
VAL_ 525 TAS_pressureGallery 255 "SNA" ;
VAL_ 525 TAS_pressureReservoir 255 "SNA" ;
VAL_ 525 TAS_runMode 7 "RUN_MODE_DYNO" 6 "RUN_MODE_LOW_POWER" 5 "RUN_MODE_NORMAL" 4 "RUN_MODE_DAN" 3 "RUN_MODE_ASSEMBLY" 2 "RUN_MODE_SERVICE" 1 "RUN_MODE_SYSTEM_CHECK" 0 "RUN_MODE_INIT" ;
VAL_ 525 TAS_filterMode 7 "MODE_STOPPING" 6 "MODE_DRIVE" 5 "MODE_LOADING" 4 "MODE_READY" 3 "MODE_TEST" 2 "MODE_CALIBRATE" 1 "MODE_INIT" 0 "MODE_NONE" ;
VAL_ 525 TAS_limpHomeMode 4 "LIMP_HOME_MODE_40" 3 "LIMP_HOME_MODE_30" 2 "LIMP_HOME_MODE_20" 1 "LIMP_HOME_MODE_10" 0 "LIMP_HOME_MODE_0" ;
VAL_ 525 TAS_targetLevel 4 "TAS_VERY_LOW" 3 "TAS_LOW" 2 "TAS_STANDARD" 1 "TAS_HIGH" 0 "TAS_VERY_HIGH" ;
VAL_ 525 TAS_currentLevel 4 "TAS_VERY_LOW" 3 "TAS_LOW" 2 "TAS_STANDARD" 1 "TAS_HIGH" 0 "TAS_VERY_HIGH" ;
VAL_ 409 TAS_adaptiveActivityFL_C 31 "SNA" ;
VAL_ 409 TAS_adaptiveActivityFL_R 31 "SNA" ;
VAL_ 409 TAS_adaptiveActivityFR_C 31 "SNA" ;
VAL_ 409 TAS_adaptiveActivityFR_R 31 "SNA" ;
VAL_ 409 TAS_adaptiveActivityRL_C 31 "SNA" ;
VAL_ 409 TAS_adaptiveActivityRL_R 31 "SNA" ;
VAL_ 409 TAS_adaptiveActivityRR_C 31 "SNA" ;
VAL_ 409 TAS_adaptiveActivityRR_R 31 "SNA" ;
VAL_ 409 TAS_uiHeightFL 63 "SNA" ;
VAL_ 409 TAS_uiHeightFR 63 "SNA" ;
VAL_ 409 TAS_uiHeightRL 63 "SNA" ;
VAL_ 409 TAS_uiHeightRR 63 "SNA" ;
VAL_ 410 TAS_bodyAccelFL 255 "SNA" ;
VAL_ 410 TAS_bodyAccelFR 255 "SNA" ;
VAL_ 410 TAS_bodyAccelRL 255 "SNA" ;
VAL_ 410 TAS_bodyAccelRR 255 "SNA" ;
VAL_ 538 TAS_adaptiveRideModeOverride 3 "TAS_ADAPTIVE_RIDE_MODE_SNA" 2 "TAS_ADAPTIVE_RIDE_MODE_SPORT" 1 "TAS_ADAPTIVE_RIDE_MODE_AUTO" 0 "TAS_ADAPTIVE_RIDE_MODE_COMFORT" ;
VAL_ 538 TAS_launchModeState 4 "TAS_LAUNCH_MODE_STATE_RAISE_SUSPENSION" 3 "TAS_LAUNCH_MODE_STATE_READY" 2 "TAS_LAUNCH_MODE_STATE_LOWER_SUSPENSION" 1 "TAS_LAUNCH_MODE_STATE_IDLE" 0 "TAS_LAUNCH_MODE_STATE_BLOCKED" ;
VAL_ 1410 TCU_alertID 6 "w006_MpssUnavailable" 5 "w005_SIMSlotError" 4 "w004_MSDTransmissionFailed" 3 "w003_ECallFailed" 2 "w002_CellRegRejected" 1 "w001_IMSRegistrationFailed" 0 "ALERT_DO_NOT_USE_ZERO" ;
VAL_ 1410 TCU_alertState 1 "SET" 0 "CLEARED" ;
VAL_ 1409 TCU_logMux 15 "mdmBusyActive" 14 "mdmSIMStatus" 13 "mdmIMSStatus" 12 "mdmServiceState" 11 "mdmUplinkAvgRage" 10 "mdmUplinkAllowedRate" 9 "mdmSINR" 8 "mdmRSRP" 7 "mdmUplinkQueueSize" 6 "totalResumes" 5 "pwmcap" 4 "pwm" 3 "availableMemory" 2 "mdmCoreTemperature" 1 "cpuUsage" 0 "cpuTemp" ;
VAL_ 1409 TCU_mdmBusyActive 4294967295 "SNA" ;
VAL_ 1408 TCU_statusMux 2 "goingToSleep" 1 "tcuCmdId" 0 "wakeUpReason" ;
VAL_ 1408 TCU_wakeUpReason 4294967295 "SNA" ;
VAL_ 1408 TCU_goingToSleep 4294967295 "SNA" ;
VAL_ 879 TPMS_learningStatus 3 "PASSED" 2 "STOPPED" 1 "ONGOING" 0 "FAILED" ;
VAL_ 879 TPMS_localisationStatus 3 "PASSED" 2 "STOPPED" 1 "ONGOING" 0 "FAILED" ;
VAL_ 802 TPMS_pressureFL 255 "SNA" 254 "OVER_RANGE" ;
VAL_ 802 TPMS_temperatureFL 255 "TPMS_TEMPERATURE_SNA" ;
VAL_ 802 TPMS_pressureFR 255 "SNA" 254 "OVER_RANGE" ;
VAL_ 802 TPMS_temperatureFR 255 "TPMS_TEMPERATURE_SNA" ;
VAL_ 802 TPMS_pressureRL 255 "SNA" 254 "OVER_RANGE" ;
VAL_ 802 TPMS_temperatureRL 255 "TPMS_TEMPERATURE_SNA" ;
VAL_ 802 TPMS_pressureRR 255 "SNA" 254 "OVER_RANGE" ;
VAL_ 802 TPMS_temperatureRR 255 "TPMS_TEMPERATURE_SNA" ;
VAL_ 1519 TPMS_infoIndex 255 "END" 31 "SUBCOMPONENT_GITHASH" 30 "PACKAGE_SN_8_14" 29 "PACKAGE_SN_1_7" 27 "PACKAGE_PN_15_20" 26 "PACKAGE_PN_8_14" 25 "PACKAGE_PN_1_7" 23 "SUBCOMPONENT2" 22 "VARIANTCRC" 20 "UDS_PROTOCOL_BOOTCRC" 19 "VERSION_DEPRECATED" 18 "BOOTLOADER_GITHASH" 17 "APP_GITHASH" 16 "SUBCOMPONENT" 15 "BOOTLOADER_CRC" 14 "BOOTLOADER_SVN" 13 "APP_CRC" 11 "PCBAID_ASSYID_USAGEID" 10 "BUILD_HWID_COMPONENTID" 9 "DEPRECATED_9" 8 "DEPRECATED_8" 7 "DEPRECATED_7" 6 "DEPRECATED_6" 5 "DEPRECATED_5" 4 "DEPRECATED_4" 3 "DEPRECATED_3" 2 "DEPRECATED_2" 1 "DEPRECATED_1" 0 "DEPRECATED_0" ;
VAL_ 1298 TRCM_alertID 632 "a632_loop31AsicStartupDiagnosticFailure" 631 "a631_loop30AsicStartupDiagnosticFailure" 630 "a630_loop29AsicStartupDiagnosticFailure" 629 "a629_loop28AsicStartupDiagnosticFailure" 628 "a628_loop27AsicStartupDiagnosticFailure" 627 "a627_loop26AsicStartupDiagnosticFailure" 626 "a626_loop25AsicStartupDiagnosticFailure" 625 "a625_loop24AsicStartupDiagnosticFailure" 624 "a624_loop23AsicStartupDiagnosticFailure" 623 "a623_loop22AsicStartupDiagnosticFailure" 622 "a622_loop21AsicStartupDiagnosticFailure" 621 "a621_loop20AsicStartupDiagnosticFailure" 620 "a620_loop19AsicStartupDiagnosticFailure" 619 "a619_loop18AsicStartupDiagnosticFailure" 618 "a618_loop17AsicStartupDiagnosticFailure" 617 "a617_loop16AsicStartupDiagnosticFailure" 616 "a616_loop15AsicStartupDiagnosticFailure" 615 "a615_loop14AsicStartupDiagnosticFailure" 614 "a614_loop13AsicStartupDiagnosticFailure" 613 "a613_loop12AsicStartupDiagnosticFailure" 612 "a612_loop11AsicStartupDiagnosticFailure" 611 "a611_loop10AsicStartupDiagnosticFailure" 610 "a610_loop9AsicStartupDiagnosticFailure" 609 "a609_loop8AsicStartupDiagnosticFailure" 608 "a608_loop7AsicStartupDiagnosticFailure" 607 "a607_loop6AsicStartupDiagnosticFailure" 606 "a606_loop5AsicStartupDiagnosticFailure" 605 "a605_loop4AsicStartupDiagnosticFailure" 604 "a604_loop3AsicStartupDiagnosticFailure" 603 "a603_loop2AsicStartupDiagnosticFailure" 602 "a602_loop1AsicStartupDiagnosticFailure" 601 "a601_loop0AsicStartupDiagnosticFailure" 600 "a600_airbagAsicStartupFailure" 599 "a599_verticalAccelOffsetNegLimit" 598 "a598_verticalAccelOffsetPosLimit" 597 "a597_lateralAccelOffsetNegLimit" 596 "a596_lateralAccelOffsetPosLimit" 595 "a595_longitudinalAccelOffsetNegLimit" 594 "a594_longitudinalAccelOffsetPosLimit" 593 "a593_rollRateOffsetNegLimit" 592 "a592_rollRateOffsetPosLimit" 591 "a591_pitchRateOffsetNegLimit" 590 "a590_pitchRateOffsetPosLimit" 589 "a589_yawRateOffsetNegLimit" 588 "a588_yawRateOffsetPosLimit" 582 "a582_AlgoWake_RCM_AWAKE" 581 "a581_AlgoWake_RCM_ENABLED_ROLL" 580 "a580_AlgoWake_RCM_ENABLED_Y" 579 "a579_AlgoWake_RCM_ENABLED_X" 578 "a578_AlgoWake_IMPACT_FINISH_ROLL" 577 "a577_AlgoWake_IMPACT_FINISH_Y" 576 "a576_AlgoWake_IMPACT_FINISH_X" 575 "a575_AlgoWake_IMPACT_FINISH_ROLL_LEFT" 574 "a574_AlgoWake_IMPACT_FINISH_ROLL_RIGHT" 573 "a573_AlgoWake_IMPACT_FINISH_Y_RCM" 572 "a572_AlgoWake_IMPACT_FINISH_Y_RCM_NEG" 571 "a571_AlgoWake_IMPACT_FINISH_Y_RCM_POS" 570 "a570_AlgoWake_IMPACT_FINISH_X_REAR" 569 "a569_AlgoWake_IMPACT_FINISH_X_FRONT" 568 "a568_AlgoWake_RCM_AWAKE_Y" 567 "a567_AlgoWake_RCM_AWAKE_X" 566 "a566_AlgoWake_RCM_AWAKE_ROLL" 565 "a565_AlgoWake_RCM_AWAKE_RIGHT" 564 "a564_AlgoWake_RCM_AWAKE_LEFT" 563 "a563_AlgoWake_RCM_AWAKE_REAR" 562 "a562_AlgoWake_RCM_AWAKE_FRONT" 561 "a561_AlgoWake_RCM_WAKE_ROLL_RIGHT" 560 "a560_AlgoWake_RCM_WAKE_ROLL_LEFT" 559 "a559_AlgoWake_PAS_RH_PLAUSI" 558 "a558_AlgoWake_PAS_RH_PLAUSI_REAR" 557 "a557_AlgoWake_PAS_RH_PLAUSI_FRONT" 556 "a556_AlgoWake_PAS_LH_PLAUSI" 555 "a555_AlgoWake_PAS_LH_PLAUSI_REAR" 554 "a554_AlgoWake_PAS_LH_PLAUSI_FRONT" 553 "a553_AlgoWake_RCM_WAKE_RIGHT" 552 "a552_AlgoWake_RCM_WAKE_LEFT" 551 "a551_AlgoWake_RCM_WAKE_REAR" 550 "a550_AlgoWake_RCM_WAKE_FRONT" 546 "a546_sensorValuesFaultedBySmart" 545 "a545_erCapBelowAutarkyThreshold" 544 "a544_erCapDiagnosticsFailed" 525 "a525_FSABConfigError" 524 "a524_FSABCrossCoupled" 523 "a523_FSABShortToSelf" 522 "a522_FSABOpen" 521 "a521_FSABShortToBattery" 520 "a520_FSABShortToGround" 519 "a519_IC1FLConfigError" 518 "a518_IC1FLCrossCoupled" 517 "a517_IC1FLShortToSelf" 516 "a516_IC1FLOpen" 515 "a515_IC1FLShortToBattery" 514 "a514_IC1FLShortToGround" 513 "a513_IC1FRConfigError" 512 "a512_IC1FRCrossCoupled" 511 "a511_IC1FRShortToSelf" 510 "a510_IC1FROpen" 509 "a509_IC1FRShortToBattery" 508 "a508_IC1FRShortToGround" 507 "a507_BTRD_AnchorConfigError" 506 "a506_BTRD_AnchorCrossCoupled" 505 "a505_BTRD_AnchorShortToSelf" 504 "a504_BTRD_AnchorOpen" 503 "a503_BTRD_AnchorShortToBattery" 502 "a502_BTRD_AnchorShortToGround" 501 "a501_BTRP_AnchorConfigError" 500 "a500_BTRP_AnchorCrossCoupled" 499 "a499_BTRP_AnchorShortToSelf" 498 "a498_BTRP_AnchorOpen" 497 "a497_BTRP_AnchorShortToBattery" 496 "a496_BTRP_AnchorShortToGround" 495 "a495_BTRLConfigError" 494 "a494_BTRLCrossCoupled" 493 "a493_BTRLShortToSelf" 492 "a492_BTRLOpen" 491 "a491_BTRLShortToBattery" 490 "a490_BTRLShortToGround" 489 "a489_BTRRConfigError" 488 "a488_BTRRCrossCoupled" 487 "a487_BTRRShortToSelf" 486 "a486_BTRROpen" 485 "a485_BTRRShortToBattery" 484 "a484_BTRRShortToGround" 483 "a483_SA1FRConfigError" 482 "a482_SA1FRCrossCoupled" 481 "a481_SA1FRShortToSelf" 480 "a480_SA1FROpen" 479 "a479_SA1FRShortToBattery" 478 "a478_SA1FRShortToGround" 477 "a477_SA1FLConfigError" 476 "a476_SA1FLCrossCoupled" 475 "a475_SA1FLShortToSelf" 474 "a474_SA1FLOpen" 473 "a473_SA1FLShortToBattery" 472 "a472_SA1FLShortToGround" 471 "a471_BTRD_RetractorConfigError" 470 "a470_BTRD_RetractorCrossCoupled" 469 "a469_BTRD_RetractorShortToSelf" 468 "a468_BTRD_RetractorOpen" 467 "a467_BTRD_RetractorShortToBattery" 466 "a466_BTRD_RetractorShortToGround" 465 "a465_BTRP_RetractorConfigError" 464 "a464_BTRP_RetractorCrossCoupled" 463 "a463_BTRP_RetractorShortToSelf" 462 "a462_BTRP_RetractorOpen" 461 "a461_BTRP_RetractorShortToBattery" 460 "a460_BTRP_RetractorShortToGround" 459 "a459_DLLConfigError" 458 "a458_DLLCrossCoupled" 457 "a457_DLLShortToSelf" 456 "a456_DLLOpen" 455 "a455_DLLShortToBattery" 454 "a454_DLLShortToGround" 453 "a453_PLLConfigError" 452 "a452_PLLCrossCoupled" 451 "a451_PLLShortToSelf" 450 "a450_PLLOpen" 449 "a449_PLLShortToBattery" 448 "a448_PLLShortToGround" 447 "a447_IKBFDConfigError" 446 "a446_IKBFDCrossCoupled" 445 "a445_IKBFDShortToSelf" 444 "a444_IKBFDOpen" 443 "a443_IKBFDShortToBattery" 442 "a442_IKBFDShortToGround" 441 "a441_IKBFPConfigError" 440 "a440_IKBFPCrossCoupled" 439 "a439_IKBFPShortToSelf" 438 "a438_IKBFPOpen" 437 "a437_IKBFPShortToBattery" 436 "a436_IKBFPShortToGround" 435 "a435_DAVConfigError" 434 "a434_DAVCrossCoupled" 433 "a433_DAVShortToSelf" 432 "a432_DAVOpen" 431 "a431_DAVShortToBattery" 430 "a430_DAVShortToGround" 429 "a429_AB2FDConfigError" 428 "a428_AB2FDCrossCoupled" 427 "a427_AB2FDShortToSelf" 426 "a426_AB2FDOpen" 425 "a425_AB2FDShortToBattery" 424 "a424_AB2FDShortToGround" 423 "a423_AB2FPConfigError" 422 "a422_AB2FPCrossCoupled" 421 "a421_AB2FPShortToSelf" 420 "a420_AB2FPOpen" 419 "a419_AB2FPShortToBattery" 418 "a418_AB2FPShortToGround" 417 "a417_PAVConfigError" 416 "a416_PAVCrossCoupled" 415 "a415_PAVShortToSelf" 414 "a414_PAVOpen" 413 "a413_PAVShortToBattery" 412 "a412_PAVShortToGround" 411 "a411_AB1FDConfigError" 410 "a410_AB1FDCrossCoupled" 409 "a409_AB1FDShortToSelf" 408 "a408_AB1FDOpen" 407 "a407_AB1FDShortToBattery" 406 "a406_AB1FDShortToGround" 405 "a405_AB1FPConfigError" 404 "a404_AB1FPCrossCoupled" 403 "a403_AB1FPShortToSelf" 402 "a402_AB1FPOpen" 401 "a401_AB1FPShortToBattery" 400 "a400_AB1FPShortToGround" 398 "a398_asicNvmReprogrammed" 397 "a397_safingMonitorError" 396 "a396_spiCommunicationProgramError" 395 "a395_imuCalibrationNotDone" 394 "a394_gspiGlobalStatusWordError" 393 "a393_depAdcConvertRatioError" 392 "a392_extAsic2ClockOrOperatingStateError" 391 "a391_extAsic1ClockOrOperatingStateError" 390 "a390_systemAsicClockOrOperatingStateError" 389 "a389_asicPwrStatusError" 388 "a388_cpuLoadHigh" 387 "a387_primaryAsicResetSource" 385 "a385_safingEngine21NoValidData" 384 "a384_safingEngine20NoValidData" 383 "a383_safingEngine19NoValidData" 382 "a382_safingEngine18NoValidData" 381 "a381_safingEngine17NoValidData" 380 "a380_safingEngine16NoValidData" 379 "a379_safingEngine15NoValidData" 378 "a378_safingEngine14NoValidData" 377 "a377_safingEngine13NoValidData" 376 "a376_safingEngine12NoValidData" 375 "a375_safingEngine11NoValidData" 374 "a374_safingEngine10NoValidData" 373 "a373_safingEngine9NoValidData" 372 "a372_safingEngine8NoValidData" 371 "a371_safingEngine7NoValidData" 370 "a370_safingEngine6NoValidData" 369 "a369_safingEngine5NoValidData" 368 "a368_safingEngine4NoValidData" 367 "a367_safingEngine3NoValidData" 366 "a366_safingEngine2NoValidData" 365 "a365_safingEngine1NoValidData" 364 "a364_safingEngine0NoValidData" 363 "a363_Loop31Deployment" 362 "a362_Loop30Deployment" 361 "a361_Loop29Deployment" 360 "a360_Loop28Deployment" 359 "a359_Loop27Deployment" 358 "a358_Loop26Deployment" 357 "a357_Loop25Deployment" 356 "a356_Loop24Deployment" 355 "a355_IC1FLDeployment" 354 "a354_IC1FRDeployment" 353 "a353_Loop21Deployment" 352 "a352_Loop20Deployment" 351 "a351_BT1FLDeployment" 350 "a350_BT1FRDeployment" 349 "a349_BT1RLDeployment" 348 "a348_BT1RRDeployment" 347 "a347_SA1FRDeployment" 346 "a346_SA1FLDeployment" 345 "a345_BT2FLDeployment" 344 "a344_BT2FRDeployment" 343 "a343_ALLFLDeployment" 342 "a342_ALLFRDeployment" 341 "a341_KA1FDDeployment" 340 "a340_KA1FPDeployment" 339 "a339_Loop7Deployment" 338 "a338_AV1FDDeployment" 337 "a337_AB2FDDeployment" 336 "a336_AB2FPDeployment" 335 "a335_Loop3Deployment" 334 "a334_AV1FPDeployment" 333 "a333_AB1FDDeployment" 332 "a332_AB1FPDeployment" 331 "a331_unarmedLoop31DeployCommand" 330 "a330_unarmedLoop30DeployCommand" 329 "a329_unarmedLoop29DeployCommand" 328 "a328_unarmedLoop28DeployCommand" 327 "a327_unarmedLoop27DeployCommand" 326 "a326_unarmedLoop26DeployCommand" 325 "a325_unarmedLoop25DeployCommand" 324 "a324_unarmedLoop24DeployCommand" 323 "a323_unarmedIC1FLDeployCommand" 322 "a322_unarmedIC1FRDeployCommand" 321 "a321_unarmedLoop21DeployCommand" 320 "a320_unarmedLoop20DeployCommand" 319 "a319_unarmedBT1FLDeployCommand" 318 "a318_unarmedBT1FRDeployCommand" 317 "a317_unarmedBT1RLDeployCommand" 316 "a316_unarmedBT1RRDeployCommand" 315 "a315_unarmedSA1FRDeployCommand" 314 "a314_unarmedSA1FLDeployCommand" 313 "a313_unarmedBT2FLDeployCommand" 312 "a312_unarmedBT2FRDeployCommand" 311 "a311_unarmedALLFLDeployCommand" 310 "a310_unarmedALLFRDeployCommand" 309 "a309_unarmedKA1FDDeployCommand" 308 "a308_unarmedKA1FPDeployCommand" 307 "a307_unarmedLoop7DeployCommand" 306 "a306_unarmedAV1FDDeployCommand" 305 "a305_unarmedAB2FDDeployCommand" 304 "a304_unarmedAB2FPDeployCommand" 303 "a303_unarmedFSABDeployCommand" 302 "a302_unarmedAV1FPDeployCommand" 301 "a301_unarmedAB1FDDeployCommand" 300 "a300_unarmedAB1FPDeployCommand" 299 "a299_safingEngine21Armed" 298 "a298_safingEngine20Armed" 297 "a297_safingEngine19Armed" 296 "a296_safingEngine18Armed" 295 "a295_safingEngine17Armed" 294 "a294_safingEngine16Armed" 293 "a293_safingEngine15Armed" 292 "a292_safingEngine14Armed" 291 "a291_safingEngine13Armed" 290 "a290_safingEngine12Armed" 289 "a289_safingEngine11Armed" 288 "a288_safingEngine10Armed" 287 "a287_safingEngine9Armed" 286 "a286_safingEngine8Armed" 285 "a285_safingEngine7Armed" 284 "a284_safingEngine6Armed" 283 "a283_safingEngine5Armed" 282 "a282_safingEngine4Armed" 281 "a281_safingEngine3Armed" 280 "a280_safingEngine2Armed" 279 "a279_safingEngine1Armed" 278 "a278_safingEngine0Armed" 276 "a276_watchdogStatus" 275 "a275_asm5AccStatusError" 274 "a274_asm5ArsStatusZError" 273 "a273_asm5ArsStatusXError" 272 "a272_asm5ComStatusError" 267 "a267_frontCenterAccelYSignalMonitor" 266 "a266_frontCenterAccelYSensorDefect" 265 "a265_frontCenterAccelYCommError" 264 "a264_frontCenterAccelYOpen" 263 "a263_frontCenterAccelYConfigError" 262 "a262_frontCenterAccelYShortToBattery" 261 "a261_frontCenterAccelYShortToGround" 260 "a260_frontCenterAccelYInitFailure" 257 "a257_frontCenterAccelXSignalMonitor" 256 "a256_frontCenterAccelXSensorDefect" 255 "a255_frontCenterAccelXCommError" 254 "a254_frontCenterAccelXOpen" 253 "a253_frontCenterAccelXConfigError" 252 "a252_frontCenterAccelXShortToBattery" 251 "a251_frontCenterAccelXShortToGround" 250 "a250_frontCenterAccelXInitFailure" 247 "a247_rightRearDoorPressureSignalMonitor" 246 "a246_rightRearDoorPressureSensorDefect" 245 "a245_rightRearDoorPressureCommError" 244 "a244_rightRearDoorPressureOpen" 243 "a243_rightRearDoorPressureConfigError" 242 "a242_rightRearDoorPressureShortToBattery" 241 "a241_rightRearDoorPressureShortToGround" 240 "a240_rightRearDoorPressureInitFailure" 237 "a237_leftRearDoorPressureSignalMonitor" 236 "a236_leftRearDoorPressureSensorDefect" 235 "a235_leftRearDoorPressureCommError" 234 "a234_leftRearDoorPressureOpen" 233 "a233_leftRearDoorPressureConfigError" 232 "a232_leftRearDoorPressureShortToBattery" 231 "a231_leftRearDoorPressureShortToGround" 230 "a230_leftRearDoorPressureInitFailure" 227 "a227_rightCPillarAccelSignalMonitor" 226 "a226_rightCPillarAccelSensorDefect" 225 "a225_rightCPillarAccelCommError" 224 "a224_rightCPillarAccelOpen" 223 "a223_rightCPillarAccelConfigError" 222 "a222_rightCPillarAccelShortToBattery" 221 "a221_rightCPillarAccelShortToGround" 220 "a220_rightCPillarAccelInitFailure" 217 "a217_leftCPillarAccelSignalMonitor" 216 "a216_leftCPillarAccelSensorDefect" 215 "a215_leftCPillarAccelCommError" 214 "a214_leftCPillarAccelOpen" 213 "a213_leftCPillarAccelConfigError" 212 "a212_leftCPillarAccelShortToBattery" 211 "a211_leftCPillarAccelShortToGround" 210 "a210_leftCPillarAccelInitFailure" 207 "a207_frontCenterAccelSignalMonitor" 206 "a206_frontCenterAccelSensorDefect" 205 "a205_frontCenterAccelCommError" 204 "a204_frontCenterAccelOpen" 203 "a203_frontCenterAccelConfigError" 202 "a202_frontCenterAccelShortToBattery" 201 "a201_frontCenterAccelShortToGround" 200 "a200_frontCenterAccelInitFailure" 197 "a197_leftBPillarAccelSignalMonitor" 196 "a196_leftBPillarAccelSensorDefect" 195 "a195_leftBPillarAccelCommError" 194 "a194_leftBPillarAccelOpen" 193 "a193_leftBPillarAccelConfigError" 192 "a192_leftBPillarAccelShortToBattery" 191 "a191_leftBPillarAccelShortToGround" 190 "a190_leftBPillarAccelInitFailure" 187 "a187_rightBPillarAccelSignalMonitor" 186 "a186_rightBPillarAccelSensorDefect" 185 "a185_rightBPillarAccelCommError" 184 "a184_rightBPillarAccelOpen" 183 "a183_rightBPillarAccelConfigError" 182 "a182_rightBPillarAccelShortToBattery" 181 "a181_rightBPillarAccelShortToGround" 180 "a180_rightBPillarAccelInitFailure" 177 "a177_leftFrontDoorPressureSignalMonitor" 176 "a176_leftFrontDoorPressureSensorDefect" 175 "a175_leftFrontDoorPressureCommError" 174 "a174_leftFrontDoorPressureOpen" 173 "a173_leftFrontDoorPressureConfigError" 172 "a172_leftFrontDoorPressureShortToBattery" 171 "a171_leftFrontDoorPressureShortToGround" 170 "a170_leftFrontDoorPressureInitFailure" 167 "a167_frontLeftAccelSignalMonitor" 166 "a166_frontLeftAccelSensorDefect" 165 "a165_frontLeftAccelCommError" 164 "a164_frontLeftAccelOpen" 163 "a163_frontLeftAccelConfigError" 162 "a162_frontLeftAccelShortToBattery" 161 "a161_frontLeftAccelShortToGround" 160 "a160_frontLeftAccelInitFailure" 157 "a157_rightFrontDoorPressureSignalMonitor" 156 "a156_rightFrontDoorPressureSensorDefect" 155 "a155_rightFrontDoorPressureCommError" 154 "a154_rightFrontDoorPressureOpen" 153 "a153_rightFrontDoorPressureConfigError" 152 "a152_rightFrontDoorPressureShortToBattery" 151 "a151_rightFrontDoorPressureShortToGround" 150 "a150_rightFrontDoorPressureInitFailure" 147 "a147_frontRightAccelSignalMonitor" 146 "a146_frontRightAccelSensorDefect" 145 "a145_frontRightAccelCommError" 144 "a144_frontRightAccelOpen" 143 "a143_frontRightAccelConfigError" 142 "a142_frontRightAccelShortToBattery" 141 "a141_frontRightAccelShortToGround" 140 "a140_frontRightAccelInitFailure" 139 "a139_disarmed" 138 "a138_ext2AsicSnoopTestFailed" 137 "a137_ext1AsicSnoopTestFailed" 136 "a136_asm5DeviceFaulted" 135 "a135_asm5StatusError" 134 "a134_glacierDeviceFaulted" 133 "a133_glacierDeviceReset" 132 "a132_glacierNormalOperationFailure" 131 "a131_glacierOffsetVerificationFailure" 130 "a130_glacierFinalStatusFailure" 129 "a129_glacierOscillatorVerificationFailure" 128 "a128_glacierAnalogSelfTestFailure" 127 "a127_glacierSelfTestFFailure" 126 "a126_glacierSelfTestEFailure" 125 "a125_glacierFixedPatternSelfTestFailure" 124 "a124_glacierRegisterPatternWriteFailure" 123 "a123_glacierTraceabilityReadoutB0B0Failure" 122 "a122_glacierTraceabilityReadoutA0A0Failure" 121 "a121_glacierInitialStatusFailure" 120 "a120_DI_DRIVE_MIA" 119 "a119_SCCM_MIA" 118 "a118_VCFRONT_MIA" 117 "a117_VCLEFT_MIA" 116 "a116_VCRIGHT_MIA" 115 "a115_VCSEC_MIA" 114 "a114_ESP_MIA" 113 "a113_UI_MIA" 112 "a112_EPBL_MIA" 111 "a111_EPBR_MIA" 110 "a110_GTW_MIA" 109 "a109_RCM_MIA" 108 "a108_DIF_MIA" 107 "a107_BMS_MIA" 106 "a106_PCS_MIA" 105 "a105_TAS_MIA" 104 "a104_DAS_MIA" 103 "a103_CP_MIA" 102 "a102_PTC_MIA" 101 "a101_PM_MIA" 100 "a100_CANbus_MIA" 99 "a099_PARK_MIA" 98 "a098_DIR_MIA" 97 "a097_CMP_MIA" 96 "a096_OCS1P_MIA" 95 "a095_CHG_MIA" 94 "a094_EPAS3P_MIA" 93 "a093_VCSEATP_MIA" 92 "a092_VCSEATD_MIA" 91 "a091_CMPD_MIA" 90 "a090_APS_MIA" 89 "a089_IBST_MIA" 88 "a088_DIRER_MIA" 87 "a087_DIREL_MIA" 86 "a086_VCBATT_MIA" 85 "a085_CCCM_MIA" 84 "a084_TPMS_MIA" 83 "a083_VCLEFT_IPC_MIA" 82 "a082_VCRIGHT_IPC_MIA" 81 "a081_autarkyActive" 77 "a077_ais2120SelfTestYNegativeFailed" 76 "a076_ais2120SelfTestYPositiveFailed" 75 "a075_ais2120SelfTestXNegativeFailed" 74 "a074_ais2120SelfTestXPositiveFailed" 73 "a073_ais2120DeviceFaulted" 72 "a072_ais2120StatusError" 71 "a071_asm3DeviceFaulted" 70 "a070_asm3StatusError" 69 "a069_swAppBoot" 68 "a068_vBusCUnderVoltage" 67 "a067_vBusBUnderVoltage" 66 "a066_vBusAUnderVoltage" 65 "a065_vSafingFetUnderVoltage" 64 "a064_busSleepReqTimeout" 63 "a063_SwitchFault" 62 "a062_XCPWasConnected" 61 "a061_XCPConnected" 60 "a060_engineeringBuild" 59 "a059_inputResistanceHigh" 58 "a058_inputRHighSyncDebug" 57 "a057_HVP_MIA" 46 "a046_Task1000msError" 45 "a045_Task100msError" 44 "a044_Task10msError" 43 "a043_Task1msError" 42 "a042_HighStackUsage" 41 "a041_HighCPULoad" 35 "a035_hvDisconnectCommanded" 34 "a034_apClipTrigger" 33 "a033_HercLogCreated" 31 "a031_UDSActive" 30 "a030_ECULogUploadRequest" 27 "a027_airbagAsicDeploymentDiagnosticFault" 26 "a026_airbagAsicDiagnosticFault" 25 "a025_CHCANBusFaults" 24 "a024_asm3AccStatusError" 23 "a023_asm3ArsStatusXError" 22 "a022_TaskInitError" 21 "a021_TaskSchedulerError" 20 "a020_asm3ComStatusError" 19 "a019_Task500usError" 18 "a018_asm3TemperatureOutsideOperatingRange" 17 "a017_asm5TemperatureOutsideOperatingRange" 16 "a016_NVMMRecordError" 15 "a015_NVMMError" 14 "a014_asm3TemperatureOutsideSignalRange" 13 "a013_AlertManagerFault" 12 "a012_asm5TemperatureOutsideSignalRange" 10 "a010_partyCounterError" 9 "a009_partyChecksumError" 8 "a008_chassisCounterError" 7 "a007_chassisChecksumError" 6 "a006_CANTX_cyclicError" 5 "a005_CANTXError" 3 "a003_SWAssertion" 0 "ALERT_DO_NOT_USE_ZERO" ;
VAL_ 1298 TRCM_alertState 1 "SET" 0 "CLEARED" ;
